VERSION "created by canmatrix"

NS_ :

BS_:

BU_: IPD

BO_ 299 LHZCU_LHBKBCANFD_20ms_FrP03: 8 Vector__XXX
 SG_ LHZCU_20ms_Group03_CRC : 7|8@0+ (1,0) [0|255] "null" IPD
 SG_ LHZCU_20ms_Group03_RC : 11|4@0+ (1,0) [0|15] "null" IPD
 SG_ LHZCU_20ms_Group03_Reserved1 : 15|4@0+ (1,0) [0|15] "null" IPD
 SG_ LHZCU_20ms_Group03_Reserved2 : 23|8@0+ (1,0) [0|255] "null" IPD
 SG_ LHZCU_20ms_Group03_Reserved3 : 31|8@0+ (1,0) [0|255] "null" IPD
 SG_ LHZCU_20ms_Group03_Reserved4 : 39|8@0+ (1,0) [0|255] "null" IPD
 SG_ LHZCU_20ms_Group03_Reserved6 : 41|4@0+ (1,0) [0|15] "null" IPD
 SG_ DippedBeamActStatus : 42|1@0+ (1,0) [0|1] "null" IPD
 SG_ LHZCU_20ms_Group03_Reserved5 : 47|5@0+ (1,0) [0|31] "null" IPD
 SG_ RevsLghtCtrl : 48|1@0+ (1,0) [0|1] "null" IPD
 SG_ PriySSBA : 49|1@0+ (1,0) [0|1] "null" IPD
 SG_ PriySSBAV : 50|1@0+ (1,0) [0|1] "null" IPD
 SG_ SecySSBA : 51|1@0+ (1,0) [0|1] "null" IPD
 SG_ SecySSBAV : 52|1@0+ (1,0) [0|1] "null" IPD
 SG_ SSBTrigd : 53|1@0+ (1,0) [0|1] "null" IPD
 SG_ RMainBeamLghtCtrl : 56|1@0+ (1,0) [0|1] "null" IPD
 SG_ LMainBeamLghtCtrl : 57|1@0+ (1,0) [0|1] "null" IPD
 SG_ RRDircnLghtCtrl : 58|1@0+ (1,0) [0|1] "null" IPD
 SG_ RLDircnLghtCtrl : 59|1@0+ (1,0) [0|1] "null" IPD
 SG_ FRDircnLghtCtrl : 60|1@0+ (1,0) [0|1] "null" IPD
 SG_ FLDircnLghtCtrl : 61|1@0+ (1,0) [0|1] "null" IPD
 SG_ BrkLghtCtrl : 62|1@0+ (1,0) [0|1] "null" IPD
 SG_ HzrdLghtSwReq : 63|1@0+ (1,0) [0|1] "null" IPD

BO_ 566 LHZCU_LHBKBCANFD_50ms_FrP04: 8 Vector__XXX
 SG_ FindCarFuncInfoDsp : 2|2@0+ (1,0) [0|3] "null" Vector__XXX
 SG_ FLDoorHndlPESwtActv : 7|2@0+ (1,0) [0|3] "null" IPD
 SG_ FRDoorHndlPESwtActv : 13|2@0+ (1,0) [0|3] "null" IPD
 SG_ BrkLghtSwStsV : 21|1@0+ (1,0) [0|1] "null" Vector__XXX
 SG_ BrkLghtSwSts : 22|1@0+ (1,0) [0|1] "null" Vector__XXX
 SG_ RrWiperReq : 23|1@0+ (1,0) [0|1] "null" Vector__XXX
 SG_ MainBeamLghtSwSts : 29|2@0+ (1,0) [0|3] "null" Vector__XXX
 SG_ DircnIndLghtSwSts : 31|2@0+ (1,0) [0|3] "null" IPD
 SG_ LdspcRlseSwtActv : 32|1@0+ (1,0) [0|1] "null" Vector__XXX
 SG_ FLDSP_RRWinSwtSts : 35|3@0+ (1,0) [0|7] "null" Vector__XXX
 SG_ FLDSP_RLWinSwtSts : 44|3@0+ (1,0) [0|7] "null" Vector__XXX
 SG_ FLDSP_FRWinSwtSts : 47|3@0+ (1,0) [0|7] "null" Vector__XXX
 SG_ BrkPdlTrigd : 49|1@0+ (1,0) [0|1] "null" Vector__XXX
 SG_ FLWinLclSwtSts : 52|3@0+ (1,0) [0|7] "null" Vector__XXX
 SG_ ExtrLckActnIndcn : 55|3@0+ (1,0) [0|7] "null" Vector__XXX
 SG_ AutoMainBeamLghtSts : 57|2@0+ (1,0) [0|3] "null" Vector__XXX
 SG_ DrvrDetSnsrFltSts : 60|3@0+ (1,0) [0|7] "null" Vector__XXX
 SG_ DircnIndLghtMdSts : 63|3@0+ (1,0) [0|7] "null" IPD

BO_ 652 LHZCU_LHBKBCANFD_50ms_FrP06: 8 Vector__XXX
 SG_ LHZCU_50ms_Group06_CRC : 7|8@0+ (1,0) [0|255] "null" IPD
 SG_ LHZCU_50ms_Group06_RC : 11|4@0+ (1,0) [0|15] "null" IPD
 SG_ DrvrDetSts : 13|2@0+ (1,0) [0|3] "null" IPD
 SG_ RLDoorOpenSts : 15|2@0+ (1,0) [0|3] "null" IPD
 SG_ LHZCU_50ms_Group06_Reserved1 : 16|1@0+ (1,0) [0|1] "null" IPD
 SG_ DrvrDoorOpenSts : 18|2@0+ (1,0) [0|3] "null" IPD
 SG_ BntOpenSts : 20|2@0+ (1,0) [0|3] "null" IPD
 SG_ VehLckSts : 23|3@0+ (1,0) [0|7] "null" IPD
 SG_ LHZCU_50ms_Group06_Reserved2 : 31|8@0+ (1,0) [0|255] "null" IPD
 SG_ LHZCU_50ms_Group06_Reserved3 : 39|8@0+ (1,0) [0|255] "null" IPD
 SG_ LHZCU_50ms_Group06_Reserved5 : 42|3@0+ (1,0) [0|7] "null" IPD
 SG_ RLSInitnFltPrst : 43|1@0+ (1,0) [0|1] "null" IPD
 SG_ LHZCU_50ms_Group06_Reserved4 : 47|4@0+ (1,0) [0|15] "null" IPD
 SG_ LHZCU_50ms_Group06_Reserved7 : 48|1@0+ (1,0) [0|1] "null" IPD
 SG_ DirnLghtSftyMonErr : 50|2@0+ (1,0) [0|3] "null" IPD
 SG_ LHZCU_50ms_Group06_Reserved6 : 55|5@0+ (1,0) [0|31] "null" IPD
 SG_ LHZCU_50ms_Group06_Reserved8 : 63|8@0+ (1,0) [0|255] "null" IPD

BO_ 547 LHZCU_LHBKBCANFD_50ms_FrP08: 8 Vector__XXX
 SG_ SideLghtSts : 0|1@0+ (1,0) [0|1] "null" IPD
 SG_ LHZCUeFs12Sts : 3|3@0+ (1,0) [0|7] "null" Vector__XXX
 SG_ LHZCUeFs12DiagSts : 7|4@0+ (1,0) [0|15] "null" Vector__XXX
 SG_ LHZCUeSw17Sts : 11|3@0+ (1,0) [0|7] "null" Vector__XXX
 SG_ LHZCUeSw17DiagSts : 15|4@0+ (1,0) [0|15] "null" Vector__XXX
 SG_ LHZCUeSw16Sts : 19|3@0+ (1,0) [0|7] "null" Vector__XXX
 SG_ LHZCUeSw16DiagSts : 23|4@0+ (1,0) [0|15] "null" Vector__XXX
 SG_ LHZCUeSw15Sts : 27|3@0+ (1,0) [0|7] "null" Vector__XXX
 SG_ LHZCUeSw15DiagSts : 31|4@0+ (1,0) [0|15] "null" Vector__XXX
 SG_ LHZCUeSw14Sts : 35|3@0+ (1,0) [0|7] "null" Vector__XXX
 SG_ LHZCUeSw14DiagSts : 39|4@0+ (1,0) [0|15] "null" Vector__XXX
 SG_ LHZCUeSw13Sts : 43|3@0+ (1,0) [0|7] "null" Vector__XXX
 SG_ LHZCUeSw13DiagSts : 47|4@0+ (1,0) [0|15] "null" Vector__XXX
 SG_ LHZCUeSw12Sts : 51|3@0+ (1,0) [0|7] "null" Vector__XXX
 SG_ LHZCUeSw12DiagSts : 55|4@0+ (1,0) [0|15] "null" Vector__XXX
 SG_ LHZCUeFs13Sts : 59|3@0+ (1,0) [0|7] "null" Vector__XXX
 SG_ LHZCUeFs13DiagSts : 63|4@0+ (1,0) [0|15] "null" Vector__XXX

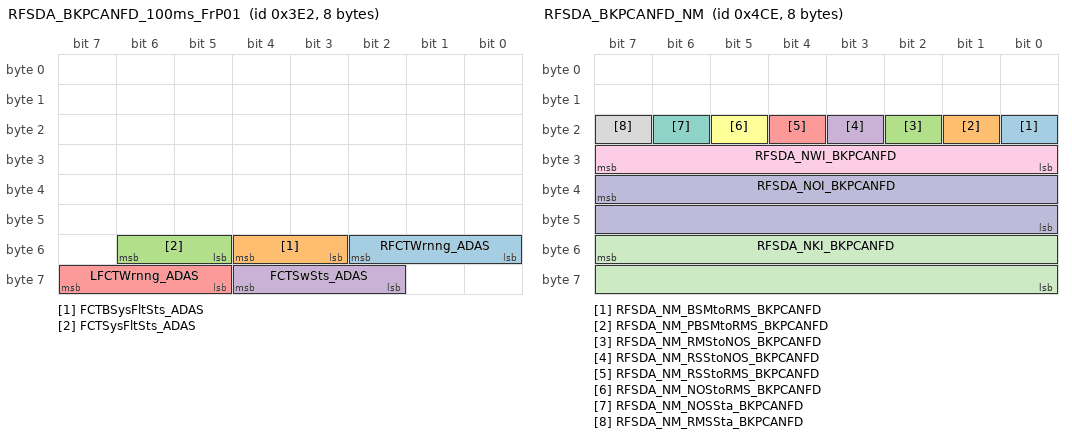
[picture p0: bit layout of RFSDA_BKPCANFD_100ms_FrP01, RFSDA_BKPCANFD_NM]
BO_ 994 RFSDA_BKPCANFD_100ms_FrP01: 8 Vector__XXX
 SG_ RFCTWrnng_ADAS : 50|3@0+ (1,0) [0|7] "null" IPD
 SG_ FCTBSysFltSts_ADAS : 52|2@0+ (1,0) [0|3] "null" IPD
 SG_ FCTSysFltSts_ADAS : 54|2@0+ (1,0) [0|3] "null" IPD
 SG_ FCTSwSts_ADAS : 60|3@0+ (1,0) [0|7] "null" IPD
 SG_ LFCTWrnng_ADAS : 63|3@0+ (1,0) [0|7] "null" IPD

BO_ 484 RFSDA_BKPCANFD_20ms_FrP02: 16 Vector__XXX
 SG_ RFSDA_20ms_Group02_CRC : 7|8@0+ (1,0) [0|255] "null" IPD
 SG_ RFSDA_20ms_Group02_RC : 11|4@0+ (1,0) [0|15] "null" IPD
 SG_ RFSDA_20ms_Group02_Reserved1 : 13|2@0+ (1,0) [0|3] "null" IPD
 SG_ AEBDclReqSts_ADAS : 15|2@0+ (1,0) [0|3] "null" IPD
 SG_ AEBDclReqToqVal_ADAS : 23|16@0+ (1,0) [0|65535] "Nm" IPD
 SG_ AEBDclReqVal_ADAS : 39|8@0+ (0.1,-12.7) [-12.7|12.8] "m/s2" IPD
 SG_ RFSDA_20ms_Group02_Reserved2 : 47|8@0+ (1,0) [0|255] "null" IPD
 SG_ RFSDA_20ms_Group02_Reserved3 : 55|8@0+ (1,0) [0|255] "null" IPD
 SG_ RFSDA_20ms_Group02_Reserved4 : 63|8@0+ (1,0) [0|255] "null" IPD
 SG_ RFSDA_20ms_Group02_Reserved5 : 71|8@0+ (1,0) [0|255] "null" IPD
 SG_ RFSDA_20ms_Group02_Reserved6 : 79|8@0+ (1,0) [0|255] "null" IPD
 SG_ RFSDA_20ms_Group02_Reserved7 : 87|8@0+ (1,0) [0|255] "null" IPD
 SG_ RFSDA_20ms_Group02_Reserved8 : 95|8@0+ (1,0) [0|255] "null" IPD
 SG_ RFSDA_20ms_Group02_Reserved9 : 103|8@0+ (1,0) [0|255] "null" IPD
 SG_ RFSDA_20ms_Group02_Reserved10 : 111|8@0+ (1,0) [0|255] "null" IPD
 SG_ RFSDA_20ms_Group02_Reserved11 : 119|8@0+ (1,0) [0|255] "null" IPD
 SG_ RFSDA_20ms_Group02_Reserved12 : 127|8@0+ (1,0) [0|255] "null" IPD

BO_ 1230 RFSDA_BKPCANFD_NM: 8 Vector__XXX
 SG_ RFSDA_NM_BSMtoRMS_BKPCANFD : 16|1@0+ (1,0) [0|1] "null" Vector__XXX
 SG_ RFSDA_NM_PBSMtoRMS_BKPCANFD : 17|1@0+ (1,0) [0|1] "null" Vector__XXX
 SG_ RFSDA_NM_RMStoNOS_BKPCANFD : 18|1@0+ (1,0) [0|1] "null" Vector__XXX
 SG_ RFSDA_NM_RSStoNOS_BKPCANFD : 19|1@0+ (1,0) [0|1] "null" Vector__XXX
 SG_ RFSDA_NM_RSStoRMS_BKPCANFD : 20|1@0+ (1,0) [0|1] "null" Vector__XXX
 SG_ RFSDA_NM_NOStoRMS_BKPCANFD : 21|1@0+ (1,0) [0|1] "null" Vector__XXX
 SG_ RFSDA_NM_NOSSta_BKPCANFD : 22|1@0+ (1,0) [0|1] "null" Vector__XXX
 SG_ RFSDA_NM_RMSSta_BKPCANFD : 23|1@0+ (1,0) [0|1] "null" Vector__XXX
 SG_ RFSDA_NWI_BKPCANFD : 31|8@0+ (1,0) [0|255] "null" Vector__XXX
 SG_ RFSDA_NOI_BKPCANFD : 39|16@0+ (1,0) [0|65535] "null" Vector__XXX
 SG_ RFSDA_NKI_BKPCANFD : 55|16@0+ (1,0) [0|65535] "null" Vector__XXX

BO_ 725 RHRDA_BKPCANFD_50ms_FrP04: 8 Vector__XXX
 SG_ RHRDA_50ms_Group04_CRC : 7|8@0+ (1,0) [0|255] "null" IPD
 SG_ RHRDA_50ms_Group04_RC : 11|4@0+ (1,0) [0|15] "null" IPD
 SG_ RDOWWrnng : 13|2@0+ (1,0) [0|3] "null" IPD
 SG_ LDOWWrnng : 15|2@0+ (1,0) [0|3] "null" IPD
 SG_ RHRDA_50ms_Group04_Reserved1 : 18|3@0+ (1,0) [0|7] "null" IPD
 SG_ RDASysSta : 23|5@0+ (1,0) [0|31] "null" IPD
 SG_ RBSDAndLCAWrnng : 25|2@0+ (1,0) [0|3] "null" IPD
 SG_ LBSDAndLCAWrnng : 27|2@0+ (1,0) [0|3] "null" IPD
 SG_ DOWSelSts : 29|2@0+ (1,0) [0|3] "null" IPD
 SG_ RDASwSts : 31|2@0+ (1,0) [0|3] "null" IPD
 SG_ LCASelSts : 33|2@0+ (1,0) [0|3] "null" IPD
 SG_ RRCTAWrnng : 35|2@0+ (1,0) [0|3] "null" IPD
 SG_ RCTSysSelSts : 37|2@0+ (1,0) [0|3] "null" IPD
 SG_ LRCTAWrnng : 39|2@0+ (1,0) [0|3] "null" IPD
 SG_ RHRDA_50ms_Group04_Reserved2 : 40|1@0+ (1,0) [0|1] "null" IPD
 SG_ RRRdrEmgcLineChngWrnng : 42|2@0+ (1,0) [0|3] "null" IPD
 SG_ RrCrnRdrCalSts : 45|3@0+ (1,0) [0|7] "null" IPD
 SG_ BSDSelSts : 47|2@0+ (1,0) [0|3] "null" IPD
 SG_ RHRDA_50ms_Group04_Reserved3 : 53|6@0+ (1,0) [0|63] "null" IPD
 SG_ RLRdrEmgcLineChngWrnng : 55|2@0+ (1,0) [0|3] "null" IPD
 SG_ RHRDA_50ms_Group04_Reserved4 : 63|8@0+ (1,0) [0|255] "null" IPD

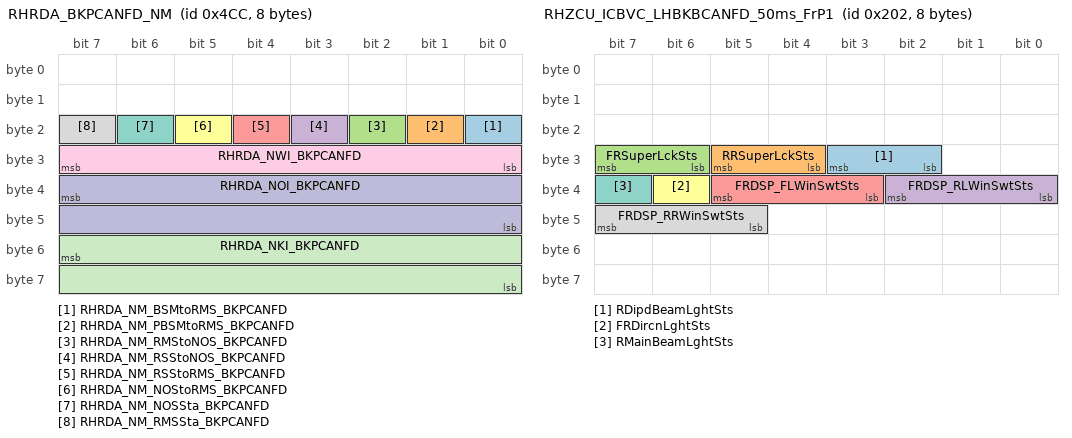
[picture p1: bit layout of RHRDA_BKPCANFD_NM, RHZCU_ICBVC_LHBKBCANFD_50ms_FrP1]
BO_ 1228 RHRDA_BKPCANFD_NM: 8 Vector__XXX
 SG_ RHRDA_NM_BSMtoRMS_BKPCANFD : 16|1@0+ (1,0) [0|1] "null" Vector__XXX
 SG_ RHRDA_NM_PBSMtoRMS_BKPCANFD : 17|1@0+ (1,0) [0|1] "null" Vector__XXX
 SG_ RHRDA_NM_RMStoNOS_BKPCANFD : 18|1@0+ (1,0) [0|1] "null" Vector__XXX
 SG_ RHRDA_NM_RSStoNOS_BKPCANFD : 19|1@0+ (1,0) [0|1] "null" Vector__XXX
 SG_ RHRDA_NM_RSStoRMS_BKPCANFD : 20|1@0+ (1,0) [0|1] "null" Vector__XXX
 SG_ RHRDA_NM_NOStoRMS_BKPCANFD : 21|1@0+ (1,0) [0|1] "null" Vector__XXX
 SG_ RHRDA_NM_NOSSta_BKPCANFD : 22|1@0+ (1,0) [0|1] "null" Vector__XXX
 SG_ RHRDA_NM_RMSSta_BKPCANFD : 23|1@0+ (1,0) [0|1] "null" Vector__XXX
 SG_ RHRDA_NWI_BKPCANFD : 31|8@0+ (1,0) [0|255] "null" Vector__XXX
 SG_ RHRDA_NOI_BKPCANFD : 39|16@0+ (1,0) [0|65535] "null" Vector__XXX
 SG_ RHRDA_NKI_BKPCANFD : 55|16@0+ (1,0) [0|65535] "null" Vector__XXX

BO_ 936 RHZCU_BDCAN_100ms_FrP06: 8 Vector__XXX
 SG_ FrtCamrHeatSts : 11|2@0+ (1,0) [0|3] "null" IPD
 SG_ FrSsdLrngFailRrsn : 22|3@0+ (1,0) [0|7] "null" Vector__XXX

BO_ 544 RHZCU_BKBCANFD_50ms_FrP27: 8 Vector__XXX
 SG_ RHZCU_50ms_Group27_CRC : 7|8@0+ (1,0) [0|255] "null" IPD
 SG_ RHZCU_50ms_Group27_RC : 11|4@0+ (1,0) [0|15] "null" IPD
 SG_ RHZCU_50ms_Group27_Reserved1 : 15|4@0+ (1,0) [0|15] "null" IPD
 SG_ RHZCU_50ms_Group27_Reserved2 : 16|1@0+ (1,0) [0|1] "null" IPD
 SG_ RHZCUeSw37Sts : 19|3@0+ (1,0) [0|7] "null" IPD
 SG_ RHZCUeSw37DiagSts : 23|4@0+ (1,0) [0|15] "null" IPD
 SG_ RHZCU_50ms_Group27_Reserved3 : 24|1@0+ (1,0) [0|1] "null" IPD
 SG_ RHZCUeSw3Sts : 27|3@0+ (1,0) [0|7] "null" IPD
 SG_ RHZCUeSw3DiagSts : 31|4@0+ (1,0) [0|15] "null" IPD
 SG_ RHZCU_50ms_Group27_Reserved4 : 32|1@0+ (1,0) [0|1] "null" IPD
 SG_ RHZCUeSw9Sts : 35|3@0+ (1,0) [0|7] "null" IPD
 SG_ RHZCUeSw9DiagSts : 39|4@0+ (1,0) [0|15] "null" IPD
 SG_ RHZCU_50ms_Group27_Reserved5 : 40|1@0+ (1,0) [0|1] "null" IPD
 SG_ RHZCUeSw33Sts : 43|3@0+ (1,0) [0|7] "null" IPD
 SG_ RHZCUeSw33DiagSts : 47|4@0+ (1,0) [0|15] "null" IPD
 SG_ RHZCU_50ms_Group27_Reserved6 : 48|1@0+ (1,0) [0|1] "null" IPD
 SG_ RHZCUeSw42Sts : 51|3@0+ (1,0) [0|7] "null" IPD
 SG_ RHZCUeSw42DiagSts : 55|4@0+ (1,0) [0|15] "null" IPD
 SG_ RHZCU_50ms_Group27_Reserved7 : 56|1@0+ (1,0) [0|1] "null" IPD
 SG_ RHZCUeSw43Sts : 59|3@0+ (1,0) [0|7] "null" IPD
 SG_ RHZCUeSw43DiagSts : 63|4@0+ (1,0) [0|15] "null" IPD

BO_ 514 RHZCU_ICBVC_LHBKBCANFD_50ms_FrP1: 8 Vector__XXX
 SG_ RDipdBeamLghtSts : 27|2@0+ (1,0) [0|3] "null" Vector__XXX
 SG_ RRSuperLckSts : 29|2@0+ (1,0) [0|3] "null" Vector__XXX
 SG_ FRSuperLckSts : 31|2@0+ (1,0) [0|3] "null" Vector__XXX
 SG_ FRDSP_RLWinSwtSts : 34|3@0+ (1,0) [0|7] "null" Vector__XXX
 SG_ FRDSP_FLWinSwtSts : 37|3@0+ (1,0) [0|7] "null" Vector__XXX
 SG_ FRDircnLghtSts : 38|1@0+ (1,0) [0|1] "null" IPD
 SG_ RMainBeamLghtSts : 39|1@0+ (1,0) [0|1] "null" Vector__XXX
 SG_ FRDSP_RRWinSwtSts : 47|3@0+ (1,0) [0|7] "null" Vector__XXX

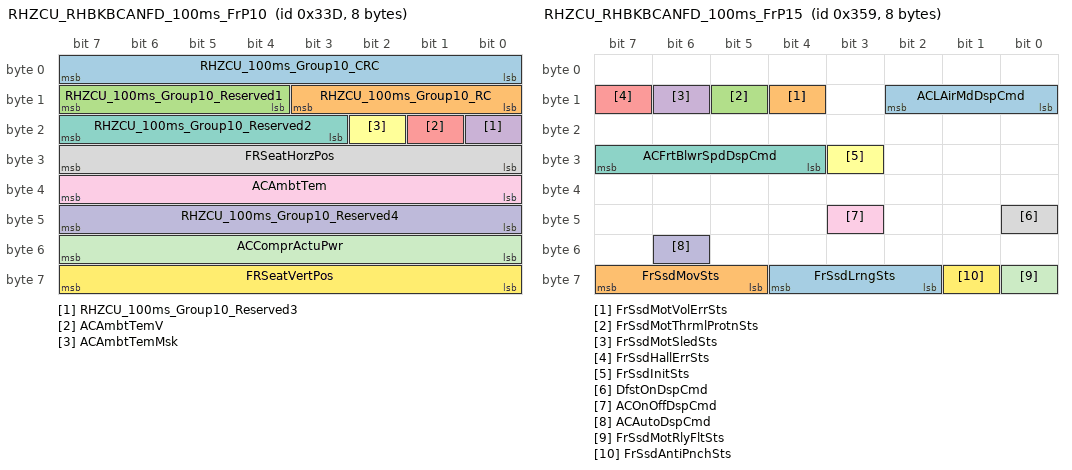
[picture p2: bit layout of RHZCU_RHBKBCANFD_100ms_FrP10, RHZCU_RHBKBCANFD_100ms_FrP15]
BO_ 829 RHZCU_RHBKBCANFD_100ms_FrP10: 8 Vector__XXX
 SG_ RHZCU_100ms_Group10_CRC : 7|8@0+ (1,0) [0|255] "null" IPD
 SG_ RHZCU_100ms_Group10_RC : 11|4@0+ (1,0) [0|15] "null" IPD
 SG_ RHZCU_100ms_Group10_Reserved1 : 15|4@0+ (1,0) [0|15] "null" IPD
 SG_ RHZCU_100ms_Group10_Reserved3 : 16|1@0+ (1,0) [0|1] "null" IPD
 SG_ ACAmbtTemV : 17|1@0+ (1,0) [0|1] "null" IPD
 SG_ ACAmbtTemMsk : 18|1@0+ (1,0) [0|1] "null" IPD
 SG_ RHZCU_100ms_Group10_Reserved2 : 23|5@0+ (1,0) [0|31] "null" IPD
 SG_ FRSeatHorzPos : 31|8@0+ (1,0) [0|255] "%" IPD
 SG_ ACAmbtTem : 39|8@0+ (0.5,-40) [-40|87.5] "degreeCelsius" IPD
 SG_ RHZCU_100ms_Group10_Reserved4 : 47|8@0+ (1,0) [0|255] "null" IPD
 SG_ ACComprActuPwr : 55|8@0+ (0.04,0) [0.00|10.20] "null" IPD
 SG_ FRSeatVertPos : 63|8@0+ (1,0) [0|255] "%" IPD

BO_ 857 RHZCU_RHBKBCANFD_100ms_FrP15: 8 Vector__XXX
 SG_ ACLAirMdDspCmd : 10|3@0+ (1,0) [0|7] "null" Vector__XXX
 SG_ FrSsdMotVolErrSts : 12|1@0+ (1,0) [0|1] "null" Vector__XXX
 SG_ FrSsdMotThrmlProtnSts : 13|1@0+ (1,0) [0|1] "null" Vector__XXX
 SG_ FrSsdMotSledSts : 14|1@0+ (1,0) [0|1] "null" Vector__XXX
 SG_ FrSsdHallErrSts : 15|1@0+ (1,0) [0|1] "null" Vector__XXX
 SG_ FrSsdInitSts : 27|1@0+ (1,0) [0|1] "null" Vector__XXX
 SG_ ACFrtBlwrSpdDspCmd : 31|4@0+ (1,0) [0|15] "null" Vector__XXX
 SG_ DfstOnDspCmd : 40|1@0+ (1,0) [0|1] "null" IPD
 SG_ ACOnOffDspCmd : 43|1@0+ (1,0) [0|1] "null" Vector__XXX
 SG_ ACAutoDspCmd : 54|1@0+ (1,0) [0|1] "null" Vector__XXX
 SG_ FrSsdMotRlyFltSts : 56|1@0+ (1,0) [0|1] "null" Vector__XXX
 SG_ FrSsdAntiPnchSts : 57|1@0+ (1,0) [0|1] "null" Vector__XXX
 SG_ FrSsdLrngSts : 60|3@0+ (1,0) [0|7] "null" Vector__XXX
 SG_ FrSsdMovSts : 63|3@0+ (1,0) [0|7] "null" Vector__XXX

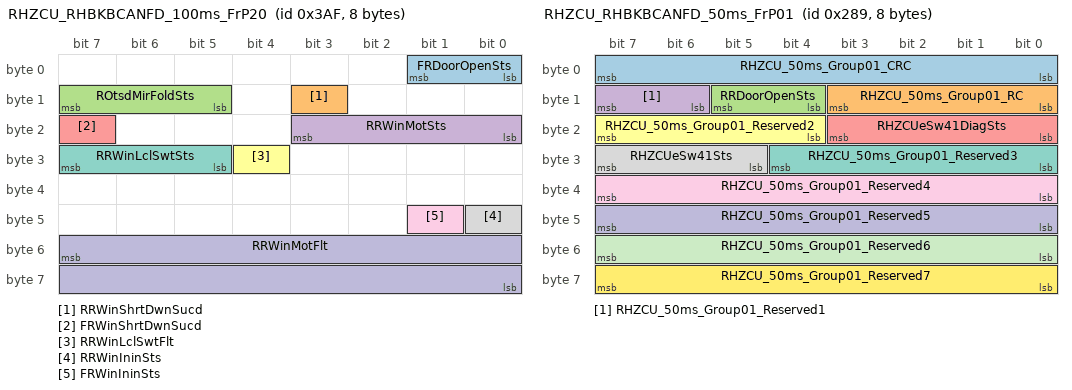
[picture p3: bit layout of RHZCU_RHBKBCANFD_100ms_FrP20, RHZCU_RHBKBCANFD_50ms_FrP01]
BO_ 943 RHZCU_RHBKBCANFD_100ms_FrP20: 8 Vector__XXX
 SG_ FRDoorOpenSts : 1|2@0+ (1,0) [0|3] "null" IPD
 SG_ RRWinShrtDwnSucd : 11|1@0+ (1,0) [0|1] "null" Vector__XXX
 SG_ ROtsdMirFoldSts : 15|3@0+ (1,0) [0|7] "null" Vector__XXX
 SG_ RRWinMotSts : 19|4@0+ (1,0) [0|15] "null" Vector__XXX
 SG_ FRWinShrtDwnSucd : 23|1@0+ (1,0) [0|1] "null" Vector__XXX
 SG_ RRWinLclSwtFlt : 28|1@0+ (1,0) [0|1] "null" Vector__XXX
 SG_ RRWinLclSwtSts : 31|3@0+ (1,0) [0|7] "null" Vector__XXX
 SG_ RRWinIninSts : 40|1@0+ (1,0) [0|1] "null" Vector__XXX
 SG_ FRWinIninSts : 41|1@0+ (1,0) [0|1] "null" Vector__XXX
 SG_ RRWinMotFlt : 55|16@0+ (1,0) [0|65535] "null" Vector__XXX

BO_ 649 RHZCU_RHBKBCANFD_50ms_FrP01: 8 Vector__XXX
 SG_ RHZCU_50ms_Group01_CRC : 7|8@0+ (1,0) [0|255] "null" IPD
 SG_ RHZCU_50ms_Group01_RC : 11|4@0+ (1,0) [0|15] "null" IPD
 SG_ RRDoorOpenSts : 13|2@0+ (1,0) [0|3] "null" IPD
 SG_ RHZCU_50ms_Group01_Reserved1 : 15|2@0+ (1,0) [0|3] "null" IPD
 SG_ RHZCUeSw41DiagSts : 19|4@0+ (1,0) [0|15] "null" IPD
 SG_ RHZCU_50ms_Group01_Reserved2 : 23|4@0+ (1,0) [0|15] "null" IPD
 SG_ RHZCU_50ms_Group01_Reserved3 : 28|5@0+ (1,0) [0|31] "null" IPD
 SG_ RHZCUeSw41Sts : 31|3@0+ (1,0) [0|7] "null" IPD
 SG_ RHZCU_50ms_Group01_Reserved4 : 39|8@0+ (1,0) [0|255] "null" IPD
 SG_ RHZCU_50ms_Group01_Reserved5 : 47|8@0+ (1,0) [0|255] "null" IPD
 SG_ RHZCU_50ms_Group01_Reserved6 : 55|8@0+ (1,0) [0|255] "null" IPD
 SG_ RHZCU_50ms_Group01_Reserved7 : 63|8@0+ (1,0) [0|255] "null" IPD

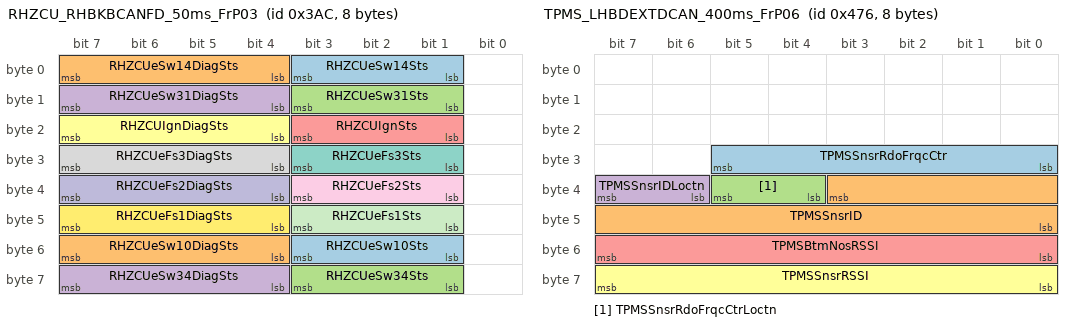
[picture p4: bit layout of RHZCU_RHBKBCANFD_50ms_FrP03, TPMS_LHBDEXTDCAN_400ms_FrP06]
BO_ 940 RHZCU_RHBKBCANFD_50ms_FrP03: 8 Vector__XXX
 SG_ RHZCUeSw14Sts : 3|3@0+ (1,0) [0|7] "null" Vector__XXX
 SG_ RHZCUeSw14DiagSts : 7|4@0+ (1,0) [0|15] "null" Vector__XXX
 SG_ RHZCUeSw31Sts : 11|3@0+ (1,0) [0|7] "null" Vector__XXX
 SG_ RHZCUeSw31DiagSts : 15|4@0+ (1,0) [0|15] "null" Vector__XXX
 SG_ RHZCUIgnSts : 19|3@0+ (1,0) [0|7] "null" Vector__XXX
 SG_ RHZCUIgnDiagSts : 23|4@0+ (1,0) [0|15] "null" Vector__XXX
 SG_ RHZCUeFs3Sts : 27|3@0+ (1,0) [0|7] "null" Vector__XXX
 SG_ RHZCUeFs3DiagSts : 31|4@0+ (1,0) [0|15] "null" Vector__XXX
 SG_ RHZCUeFs2Sts : 35|3@0+ (1,0) [0|7] "null" Vector__XXX
 SG_ RHZCUeFs2DiagSts : 39|4@0+ (1,0) [0|15] "null" Vector__XXX
 SG_ RHZCUeFs1Sts : 43|3@0+ (1,0) [0|7] "null" IPD
 SG_ RHZCUeFs1DiagSts : 47|4@0+ (1,0) [0|15] "null" Vector__XXX
 SG_ RHZCUeSw10Sts : 51|3@0+ (1,0) [0|7] "null" Vector__XXX
 SG_ RHZCUeSw10DiagSts : 55|4@0+ (1,0) [0|15] "null" Vector__XXX
 SG_ RHZCUeSw34Sts : 59|3@0+ (1,0) [0|7] "null" Vector__XXX
 SG_ RHZCUeSw34DiagSts : 63|4@0+ (1,0) [0|15] "null" Vector__XXX

BO_ 564 RZCU_LHBKBCANFD_50ms_FrP37: 8 Vector__XXX
 SG_ RZCU_50ms_Group37_CRC : 7|8@0+ (1,0) [0|255] "null" IPD
 SG_ RZCU_50ms_Group37_RC : 11|4@0+ (1,0) [0|15] "null" IPD
 SG_ RZCU_50ms_Group37_Reserved15 : 15|4@0+ (1,0) [0|15] "null" IPD
 SG_ RZCU_50ms_Group37_Reserved23 : 23|8@0+ (1,0) [0|255] "null" IPD
 SG_ ChrgrFlapLtchCtrl : 25|2@0+ (1,0) [0|3] "null" IPD
 SG_ RLDircnLghtSts : 26|1@0+ (1,0) [0|1] "null" IPD
 SG_ RZCU_50ms_Group37_Reserved31 : 31|5@0+ (1,0) [0|31] "null" IPD
 SG_ RZCU_50ms_Group37_Reserved34 : 34|5@0+ (1,0) [0|31] "null" IPD
 SG_ RRDircnLghtSts : 35|1@0+ (1,0) [0|1] "null" IPD
 SG_ RZCU_50ms_Group37_Reserved36 : 36|1@0+ (1,0) [0|1] "null" IPD
 SG_ RRDircnLghtFltsts : 37|1@0+ (1,0) [0|1] "null" IPD
 SG_ RZCU_50ms_Group37_Reserved38 : 38|1@0+ (1,0) [0|1] "null" IPD
 SG_ RLDircnLghtFltsts : 39|1@0+ (1,0) [0|1] "null" IPD
 SG_ RRDircnLghtFltsts_HW : 40|1@0+ (1,0) [0|1] "null" IPD
 SG_ RLDircnLghtFltsts_HW : 41|1@0+ (1,0) [0|1] "null" IPD
 SG_ RearFogLghtFltsts : 42|1@0+ (1,0) [0|1] "null" IPD
 SG_ RearFogLghtSts : 43|1@0+ (1,0) [0|1] "null" IPD
 SG_ RevsLghtFltSts : 44|1@0+ (1,0) [0|1] "null" IPD
 SG_ BrkLghtFltSts_HW : 45|1@0+ (1,0) [0|1] "null" IPD
 SG_ PwrLftgtClsSwtActv : 49|2@0+ (1,0) [0|3] "null" IPD
 SG_ BrkLghtSts_HW : 50|1@0+ (1,0) [0|1] "null" IPD
 SG_ RLDircnLghtSts_HW : 51|1@0+ (1,0) [0|1] "null" IPD
 SG_ RRDircnLghtSts_HW : 52|1@0+ (1,0) [0|1] "null" IPD
 SG_ LdspcOpenSts : 53|1@0+ (1,0) [0|1] "null" IPD
 SG_ RevsLghtSts : 54|1@0+ (1,0) [0|1] "null" IPD
 SG_ LdspcOpenStsV : 55|1@0+ (1,0) [0|1] "null" IPD
 SG_ RZCU_50ms_Group37_Reserved63 : 63|8@0+ (1,0) [0|255] "null" IPD

BO_ 1142 TPMS_LHBDEXTDCAN_400ms_FrP06: 8 Vector__XXX
 SG_ TPMSSnsrRdoFrqcCtr : 29|6@0+ (1,0) [0|63] "null" IPD
 SG_ TPMSSnsrID : 35|12@0+ (1,0) [0|4095] "null" IPD
 SG_ TPMSSnsrRdoFrqcCtrLoctn : 37|2@0+ (1,0) [0|3] "null" IPD
 SG_ TPMSSnsrIDLoctn : 39|2@0+ (1,0) [0|3] "null" IPD
 SG_ TPMSBtmNosRSSI : 55|8@0+ (1,0) [0|255] "null" IPD
 SG_ TPMSSnsrRSSI : 63|8@0+ (1,0) [0|255] "null" IPD

BO_ 210 Tester_ECM_SFCANFD_10ms_FrP20: 8 Vector__XXX
 SG_ En12VoltStrMotCmddOn : 56|1@0+ (1,0) [0|1] "null" IPD

BO_ 805 ZXD_BKBCANFD_100ms_FrP257: 24 Vector__XXX
 SG_ NOAQukChgSwReq : 12|1@0+ (1,0) [0|1] "null" IPD
 SG_ PDCPwrSts : 13|1@0+ (1,0) [0|1] "null" Vector__XXX
 SG_ MMCUPwrSts : 14|1@0+ (1,0) [0|1] "null" Vector__XXX
 SG_ FICMACRTemV : 15|1@0+ (1,0) [0|1] "null" Vector__XXX
 SG_ AIParkngReq_ZXD : 23|8@0+ (1,0) [0|255] "null" IPD
 SG_ FICMACRAirMdSwReq : 25|2@0+ (1,0) [0|3] "null" Vector__XXX
 SG_ FICMACLAirMdSwReq : 27|2@0+ (1,0) [0|3] "null" Vector__XXX
 SG_ FICMACIonizerReqSwReq : 29|2@0+ (1,0) [0|3] "null" Vector__XXX
 SG_ FICMACFreshSwReq : 31|2@0+ (1,0) [0|3] "null" Vector__XXX
 SG_ FICMClmOnOffSwReq : 33|2@0+ (1,0) [0|3] "null" Vector__XXX
 SG_ FICMACSyncSwReq : 35|2@0+ (1,0) [0|3] "null" Vector__XXX
 SG_ FICMACRTemIncSwReq : 37|2@0+ (1,0) [0|3] "null" Vector__XXX
 SG_ FICMACRTemDecSwReq : 39|2@0+ (1,0) [0|3] "null" Vector__XXX
 SG_ FICMAirClnrBlwrLvlReq : 42|3@0+ (1,0) [0|7] "null" Vector__XXX
 SG_ FICMACRTemReq : 47|5@0+ (0.5,15.5) [15.5|31] "null" Vector__XXX
 SG_ AutoLaneChngVcCmd : 51|4@0+ (1,0) [0|15] "null" IPD
 SG_ APAParkInOffsetTypeReq : 55|4@0+ (1,0) [0|15] "null" IPD
 SG_ FICMIFPACOnOffSwReq : 57|2@0+ (1,0) [0|3] "null" Vector__XXX
 SG_ NOAReportSetSwReq : 60|3@0+ (1,0) [0|7] "null" IPD
 SG_ NarRoVslAssSwReq : 63|3@0+ (1,0) [0|7] "null" IPD
 SG_ ParkngSpdSwResp : 65|2@0+ (1,0) [0|3] "null" IPD
 SG_ NrwroadBwdAssSwReq : 68|3@0+ (1,0) [0|7] "null" IPD
 SG_ AutoLaneChngSwReq : 71|3@0+ (1,0) [0|7] "null" IPD
 SG_ ESSAdoWrnngReq : 73|2@0+ (1,0) [0|3] "null" IPD
 SG_ AutoLaneChngSetReq : 75|2@0+ (1,0) [0|3] "null" IPD
 SG_ APASWReq : 77|2@0+ (1,0) [0|3] "null" IPD
 SG_ APAOneKeyParkSwReq : 79|2@0+ (1,0) [0|3] "null" IPD
 SG_ NarRoVslAssQuit : 81|2@0+ (1,0) [0|3] "null" IPD
 SG_ LCRSwReq : 83|2@0+ (1,0) [0|3] "null" IPD
 SG_ FrtCarGoNotfrSwReq : 85|2@0+ (1,0) [0|3] "null" IPD
 SG_ ESSswReq : 87|2@0+ (1,0) [0|3] "null" IPD
 SG_ NOPSwReq : 89|2@0+ (1,0) [0|3] "null" IPD
 SG_ NOPCitySwReq : 91|2@0+ (1,0) [0|3] "null" IPD
 SG_ NOALaneSetSwReq : 93|2@0+ (1,0) [0|3] "null" IPD
 SG_ NOAETCSetSwReq : 95|2@0+ (1,0) [0|3] "null" IPD
 SG_ WlcmLghtReq : 96|1@0+ (1,0) [0|1] "null" Vector__XXX
 SG_ D2DSwReq : 98|2@0+ (1,0) [0|3] "null" IPD
 SG_ ParkngDirSw : 101|2@0+ (1,0) [0|3] "null" IPD
 SG_ NrwroadBwdAssConfrmSwReq : 103|2@0+ (1,0) [0|3] "null" IPD
 SG_ DistToDsttnNavForSus : 111|8@0+ (2,0) [0|510] "m" Vector__XXX
 SG_ FrwlLghtReq : 112|1@0+ (1,0) [0|1] "null" Vector__XXX
 SG_ FollowMeHomeReq : 113|1@0+ (1,0) [0|1] "null" Vector__XXX
 SG_ FICMChrgSttnMchngSta : 115|2@0+ (1,0) [0|3] "null" Vector__XXX
 SG_ FVCMPowerFailSwReq : 117|2@0+ (1,0) [0|3] "null" Vector__XXX
 SG_ D2DPriETClanSwReq : 119|2@0+ (1,0) [0|3] "null" IPD
 SG_ SLIFWrnngMdReq : 126|2@0+ (1,0) [0|3] "null" IPD
 SG_ AIParkngEPAMdsw : 127|1@0+ (1,0) [0|1] "null" IPD
 SG_ PEBSwReq : 135|1@0+ (1,0) [0|1] "null" IPD

BO_ 711 ZXD_BKPCANFD_100ms_FrP76: 16 Vector__XXX
 SG_ SpedRegulaModSwReq : 55|3@0+ (1,0) [0|7] "null" IPD

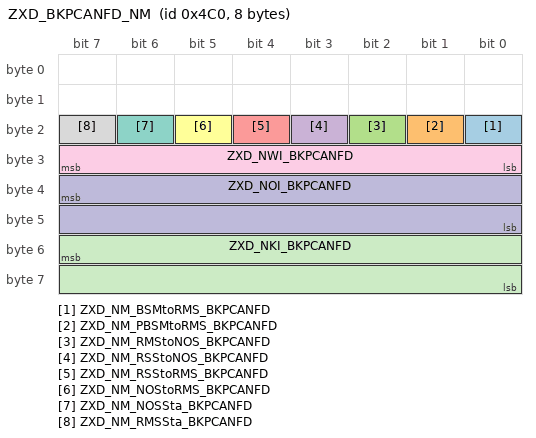
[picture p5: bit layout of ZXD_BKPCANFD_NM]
BO_ 1216 ZXD_BKPCANFD_NM: 8 Vector__XXX
 SG_ ZXD_NM_BSMtoRMS_BKPCANFD : 16|1@0+ (1,0) [0|1] "null" Vector__XXX
 SG_ ZXD_NM_PBSMtoRMS_BKPCANFD : 17|1@0+ (1,0) [0|1] "null" Vector__XXX
 SG_ ZXD_NM_RMStoNOS_BKPCANFD : 18|1@0+ (1,0) [0|1] "null" Vector__XXX
 SG_ ZXD_NM_RSStoNOS_BKPCANFD : 19|1@0+ (1,0) [0|1] "null" Vector__XXX
 SG_ ZXD_NM_RSStoRMS_BKPCANFD : 20|1@0+ (1,0) [0|1] "null" Vector__XXX
 SG_ ZXD_NM_NOStoRMS_BKPCANFD : 21|1@0+ (1,0) [0|1] "null" Vector__XXX
 SG_ ZXD_NM_NOSSta_BKPCANFD : 22|1@0+ (1,0) [0|1] "null" Vector__XXX
 SG_ ZXD_NM_RMSSta_BKPCANFD : 23|1@0+ (1,0) [0|1] "null" Vector__XXX
 SG_ ZXD_NWI_BKPCANFD : 31|8@0+ (1,0) [0|255] "null" Vector__XXX
 SG_ ZXD_NOI_BKPCANFD : 39|16@0+ (1,0) [0|65535] "null" Vector__XXX
 SG_ ZXD_NKI_BKPCANFD : 55|16@0+ (1,0) [0|65535] "null" Vector__XXX

BA_DEF_ BO_ "FrameTriggeringName" STRING;
BA_DEF_ BO_ "GenMsgCycleTime" INT 0 65535;
BA_DEF_ BO_ "GenMsgDelayTime" INT 0 65535;
BA_DEF_ BO_ "GenMsgSendType" ENUM  "cyclicX","spontanX","cyclicIfActiveX","spontanWithDelay","cyclicAndSpontanX","cyclicAndSpontanWithDelay","spontanWithRepitition","cyclicIfActiveAndSpontanWD","cyclicIfActiveFast","cyclicWithRepeatOnDemand","none";
BA_DEF_ BO_ "GenMsgStartValue" STRING;
BA_DEF_ BO_ "PduName" STRING;
BA_DEF_ BO_ "SystemMessageLongSymbol" STRING;
BA_DEF_ BO_ "VFrameFormat" ENUM  "StandardCAN","ExtendedCAN","reserved","reserved","reserved","reserved","reserved","reserved","reserved","reserved","reserved","reserved","reserved","reserved","StandardCAN_FD","ExtendedCAN_FD";
BA_DEF_ SG_ "CompuMethodName" STRING;
BA_DEF_ SG_ "GenSigStartValue" FLOAT 0 100000000000;
BA_DEF_ SG_ "ISignalName" STRING;
BA_DEF_ SG_ "LongName" STRING;
BA_DEF_ SG_ "SysSignalName" STRING;
BA_DEF_ SG_ "SystemSignalLongSymbol" STRING;
BA_ "FrameTriggeringName" BO_ 299 "LHZCU_LHBKBCANFD_20ms_FrP03";
BA_ "GenMsgCycleTime" BO_ 299 20;
BA_ "GenMsgSendType" BO_ 299 0;
BA_ "GenMsgStartValue" BO_ 299 "00f0fffffffbc000";
BA_ "PduName" BO_ 299 "LHZCU_20ms_PDU03";
BA_ "VFrameFormat" BO_ 299 14;
BA_ "FrameTriggeringName" BO_ 566 "LHZCU_LHBKBCANFD_50ms_FrP04";
BA_ "GenMsgCycleTime" BO_ 566 50;
BA_ "GenMsgSendType" BO_ 566 0;
BA_ "GenMsgStartValue" BO_ 566 "0000000000000000";
BA_ "PduName" BO_ 566 "LHZCU_50ms_PDU04";
BA_ "VFrameFormat" BO_ 566 14;
BA_ "FrameTriggeringName" BO_ 652 "LHZCU_LHBKBCANFD_50ms_FrP06";
BA_ "GenMsgCycleTime" BO_ 652 50;
BA_ "GenMsgSendType" BO_ 652 0;
BA_ "GenMsgStartValue" BO_ 652 "0000e1fffff7f9ff";
BA_ "PduName" BO_ 652 "LHZCU_50ms_PDU06";
BA_ "VFrameFormat" BO_ 652 14;
BA_ "FrameTriggeringName" BO_ 547 "LHZCU_LHBKBCANFD_50ms_FrP08";
BA_ "GenMsgCycleTime" BO_ 547 50;
BA_ "GenMsgSendType" BO_ 547 0;
BA_ "GenMsgStartValue" BO_ 547 "0000000000000000";
BA_ "PduName" BO_ 547 "LHZCU_50ms_PDU08";
BA_ "VFrameFormat" BO_ 547 14;
BA_ "FrameTriggeringName" BO_ 994 "RFSDA_BKPCANFD_100ms_FrP01";
BA_ "GenMsgCycleTime" BO_ 994 100;
BA_ "GenMsgSendType" BO_ 994 0;
BA_ "GenMsgStartValue" BO_ 994 "0000000000000004";
BA_ "PduName" BO_ 994 "RFSDA_100ms_PDU01";
BA_ "VFrameFormat" BO_ 994 14;
BA_ "FrameTriggeringName" BO_ 484 "RFSDA_BKPCANFD_20ms_FrP02";
BA_ "GenMsgCycleTime" BO_ 484 20;
BA_ "GenMsgSendType" BO_ 484 0;
BA_ "GenMsgStartValue" BO_ 484 "003000007fffffffffffffffffffffff";
BA_ "PduName" BO_ 484 "RFSDA_20ms_PDU02";
BA_ "VFrameFormat" BO_ 484 14;
BA_ "FrameTriggeringName" BO_ 1230 "RFSDA_BKPCANFD_NM";
BA_ "GenMsgSendType" BO_ 1230 1;
BA_ "GenMsgStartValue" BO_ 1230 "0000000000000000";
BA_ "PduName" BO_ 1230 "NmPDU_BKPCANFD_RFSDA";
BA_ "VFrameFormat" BO_ 1230 14;
BA_ "FrameTriggeringName" BO_ 725 "RHRDA_BKPCANFD_50ms_FrP04";
BA_ "GenMsgCycleTime" BO_ 725 50;
BA_ "GenMsgSendType" BO_ 725 0;
BA_ "GenMsgStartValue" BO_ 725 "00000f0000013fff";
BA_ "PduName" BO_ 725 "RHRDA_50ms_PDU04";
BA_ "VFrameFormat" BO_ 725 14;
BA_ "FrameTriggeringName" BO_ 1228 "RHRDA_BKPCANFD_NM";
BA_ "GenMsgSendType" BO_ 1228 1;
BA_ "GenMsgStartValue" BO_ 1228 "0000000000000000";
BA_ "PduName" BO_ 1228 "NmPDU_BKPCANFD_RHRDA";
BA_ "VFrameFormat" BO_ 1228 14;
BA_ "FrameTriggeringName" BO_ 936 "RHZCU_BDCAN_100ms_FrP06";
BA_ "GenMsgCycleTime" BO_ 936 100;
BA_ "GenMsgSendType" BO_ 936 0;
BA_ "GenMsgStartValue" BO_ 936 "0000000000000000";
BA_ "PduName" BO_ 936 "RHZCU_100ms_PDU06";
BA_ "VFrameFormat" BO_ 936 14;
BA_ "FrameTriggeringName" BO_ 544 "RHZCU_BKBCANFD_50ms_FrP27";
BA_ "GenMsgCycleTime" BO_ 544 50;
BA_ "GenMsgSendType" BO_ 544 0;
BA_ "GenMsgStartValue" BO_ 544 "00f0010101010101";
BA_ "PduName" BO_ 544 "RHZCU_50ms_PDU27";
BA_ "VFrameFormat" BO_ 544 14;
BA_ "FrameTriggeringName" BO_ 514 "RHZCU_ICBVC_LHBKBCANFD_50ms_FrP14";
BA_ "GenMsgCycleTime" BO_ 514 50;
BA_ "GenMsgSendType" BO_ 514 0;
BA_ "GenMsgStartValue" BO_ 514 "0000000000000000";
BA_ "PduName" BO_ 514 "RHZCU_ICBVC_50ms_PDU14";
BA_ "SystemMessageLongSymbol" BO_ 514 "RHZCU_ICBVC_LHBKBCANFD_50ms_FrP14";
BA_ "VFrameFormat" BO_ 514 14;
BA_ "FrameTriggeringName" BO_ 829 "RHZCU_RHBKBCANFD_100ms_FrP10";
BA_ "GenMsgCycleTime" BO_ 829 100;
BA_ "GenMsgSendType" BO_ 829 0;
BA_ "GenMsgStartValue" BO_ 829 "00f0fbff00ff00ff";
BA_ "PduName" BO_ 829 "RHZCU_100ms_PDU10";
BA_ "VFrameFormat" BO_ 829 14;
BA_ "FrameTriggeringName" BO_ 857 "RHZCU_RHBKBCANFD_100ms_FrP15";
BA_ "GenMsgCycleTime" BO_ 857 100;
BA_ "GenMsgSendType" BO_ 857 0;
BA_ "GenMsgStartValue" BO_ 857 "000700f000000000";
BA_ "PduName" BO_ 857 "RHZCU_100ms_PDU15";
BA_ "VFrameFormat" BO_ 857 14;
BA_ "FrameTriggeringName" BO_ 943 "RHZCU_RHBKBCANFD_100ms_FrP20";
BA_ "GenMsgCycleTime" BO_ 943 100;
BA_ "GenMsgSendType" BO_ 943 0;
BA_ "GenMsgStartValue" BO_ 943 "0000000000000000";
BA_ "PduName" BO_ 943 "RHZCU_100ms_PDU20";
BA_ "VFrameFormat" BO_ 943 14;
BA_ "FrameTriggeringName" BO_ 649 "RHZCU_RHBKBCANFD_50ms_FrP01";
BA_ "GenMsgCycleTime" BO_ 649 50;
BA_ "GenMsgSendType" BO_ 649 0;
BA_ "GenMsgStartValue" BO_ 649 "00c0f01fffffffff";
BA_ "PduName" BO_ 649 "RHZCU_50ms_PDU01";
BA_ "VFrameFormat" BO_ 649 14;
BA_ "FrameTriggeringName" BO_ 940 "RHZCU_RHBKBCANFD_50ms_FrP03";
BA_ "GenMsgCycleTime" BO_ 940 50;
BA_ "GenMsgSendType" BO_ 940 0;
BA_ "GenMsgStartValue" BO_ 940 "0000000000000000";
BA_ "PduName" BO_ 940 "RHZCU_50ms_PDU03";
BA_ "VFrameFormat" BO_ 940 14;
BA_ "FrameTriggeringName" BO_ 564 "RZCU_LHBKBCANFD_50ms_FrP37";
BA_ "GenMsgCycleTime" BO_ 564 50;
BA_ "GenMsgSendType" BO_ 564 0;
BA_ "GenMsgStartValue" BO_ 564 "00f0fff857c000ff";
BA_ "PduName" BO_ 564 "RZCU_50ms_PDU37";
BA_ "VFrameFormat" BO_ 564 14;
BA_ "FrameTriggeringName" BO_ 1142 "TPMS_LHBDEXTDCAN_400ms_FrP06";
BA_ "GenMsgCycleTime" BO_ 1142 400;
BA_ "GenMsgSendType" BO_ 1142 0;
BA_ "GenMsgStartValue" BO_ 1142 "0000000000000000";
BA_ "PduName" BO_ 1142 "TPMS_400ms_PDU06";
BA_ "VFrameFormat" BO_ 1142 14;
BA_ "FrameTriggeringName" BO_ 210 "Tester_ECM_SFCANFD_10ms_FrP20";
BA_ "GenMsgCycleTime" BO_ 210 10;
BA_ "GenMsgSendType" BO_ 210 0;
BA_ "GenMsgStartValue" BO_ 210 "0000000000000000";
BA_ "PduName" BO_ 210 "Teter_ECM_10ms_PDU20";
BA_ "VFrameFormat" BO_ 210 14;
BA_ "FrameTriggeringName" BO_ 805 "ZXD_BKBCANFD_100ms_FrP257";
BA_ "GenMsgCycleTime" BO_ 805 100;
BA_ "GenMsgSendType" BO_ 805 0;
BA_ "GenMsgStartValue" BO_ 805 "0080000000f800000000000000ff00000000000000000000";
BA_ "PduName" BO_ 805 "ICBVC_100ms_PDU257";
BA_ "VFrameFormat" BO_ 805 14;
BA_ "FrameTriggeringName" BO_ 711 "ZXD_BKPCANFD_100ms_FrP76";
BA_ "GenMsgCycleTime" BO_ 711 100;
BA_ "GenMsgSendType" BO_ 711 0;
BA_ "GenMsgStartValue" BO_ 711 "00000000000000000000000000000000";
BA_ "PduName" BO_ 711 "ZXD_100ms_PDU76";
BA_ "VFrameFormat" BO_ 711 14;
BA_ "FrameTriggeringName" BO_ 1216 "ZXD_BKPCANFD_NM";
BA_ "GenMsgSendType" BO_ 1216 1;
BA_ "GenMsgStartValue" BO_ 1216 "0000000000000000";
BA_ "PduName" BO_ 1216 "NmPDU_BKPCANFD_ZXD";
BA_ "VFrameFormat" BO_ 1216 14;
BA_ "CompuMethodName" SG_ 299 LHZCU_20ms_Group03_CRC "LHZCU_20ms_Group03_CRC";
BA_ "ISignalName" SG_ 299 LHZCU_20ms_Group03_CRC "ILHZCU_20ms_Group03_CRC";
BA_ "LongName" SG_ 299 LHZCU_20ms_Group03_CRC "LHZCU_20ms_Group03_CRC";
BA_ "SysSignalName" SG_ 299 LHZCU_20ms_Group03_CRC "LHZCU_20ms_Group03_CRC";
BA_ "CompuMethodName" SG_ 299 LHZCU_20ms_Group03_RC "LHZCU_20ms_Group03_RC";
BA_ "ISignalName" SG_ 299 LHZCU_20ms_Group03_RC "ILHZCU_20ms_Group03_RC";
BA_ "LongName" SG_ 299 LHZCU_20ms_Group03_RC "LHZCU_20ms_Group03_RC";
BA_ "SysSignalName" SG_ 299 LHZCU_20ms_Group03_RC "LHZCU_20ms_Group03_RC";
BA_ "CompuMethodName" SG_ 299 LHZCU_20ms_Group03_Reserved1 "LHZCU_20ms_Group03_Reserved1";
BA_ "GenSigStartValue" SG_ 299 LHZCU_20ms_Group03_Reserved1 15;
BA_ "ISignalName" SG_ 299 LHZCU_20ms_Group03_Reserved1 "ILHZCU_20ms_Group03_Reserved1";
BA_ "SysSignalName" SG_ 299 LHZCU_20ms_Group03_Reserved1 "LHZCU_20ms_Group03_Reserved1";
BA_ "CompuMethodName" SG_ 299 LHZCU_20ms_Group03_Reserved2 "LHZCU_20ms_Group03_Reserved2";
BA_ "GenSigStartValue" SG_ 299 LHZCU_20ms_Group03_Reserved2 255;
BA_ "ISignalName" SG_ 299 LHZCU_20ms_Group03_Reserved2 "ILHZCU_20ms_Group03_Reserved2";
BA_ "SysSignalName" SG_ 299 LHZCU_20ms_Group03_Reserved2 "LHZCU_20ms_Group03_Reserved2";
BA_ "CompuMethodName" SG_ 299 LHZCU_20ms_Group03_Reserved3 "LHZCU_20ms_Group03_Reserved3";
BA_ "GenSigStartValue" SG_ 299 LHZCU_20ms_Group03_Reserved3 255;
BA_ "ISignalName" SG_ 299 LHZCU_20ms_Group03_Reserved3 "ILHZCU_20ms_Group03_Reserved3";
BA_ "SysSignalName" SG_ 299 LHZCU_20ms_Group03_Reserved3 "LHZCU_20ms_Group03_Reserved3";
BA_ "CompuMethodName" SG_ 299 LHZCU_20ms_Group03_Reserved4 "LHZCU_20ms_Group03_Reserved4";
BA_ "GenSigStartValue" SG_ 299 LHZCU_20ms_Group03_Reserved4 255;
BA_ "ISignalName" SG_ 299 LHZCU_20ms_Group03_Reserved4 "ILHZCU_20ms_Group03_Reserved4";
BA_ "SysSignalName" SG_ 299 LHZCU_20ms_Group03_Reserved4 "LHZCU_20ms_Group03_Reserved4";
BA_ "CompuMethodName" SG_ 299 LHZCU_20ms_Group03_Reserved6 "LHZCU_20ms_Group03_Reserved6";
BA_ "GenSigStartValue" SG_ 299 LHZCU_20ms_Group03_Reserved6 15;
BA_ "ISignalName" SG_ 299 LHZCU_20ms_Group03_Reserved6 "ILHZCU_20ms_Group03_Reserved6";
BA_ "SysSignalName" SG_ 299 LHZCU_20ms_Group03_Reserved6 "LHZCU_20ms_Group03_Reserved6";
BA_ "CompuMethodName" SG_ 299 DippedBeamActStatus "DippedBeamActStatus";
BA_ "ISignalName" SG_ 299 DippedBeamActStatus "IDippedBeamActStatus";
BA_ "LongName" SG_ 299 DippedBeamActStatus "Dipped Beam Activated Status";
BA_ "SysSignalName" SG_ 299 DippedBeamActStatus "DippedBeamActStatus";
BA_ "CompuMethodName" SG_ 299 LHZCU_20ms_Group03_Reserved5 "LHZCU_20ms_Group03_Reserved5";
BA_ "GenSigStartValue" SG_ 299 LHZCU_20ms_Group03_Reserved5 31;
BA_ "ISignalName" SG_ 299 LHZCU_20ms_Group03_Reserved5 "ILHZCU_20ms_Group03_Reserved5";
BA_ "SysSignalName" SG_ 299 LHZCU_20ms_Group03_Reserved5 "LHZCU_20ms_Group03_Reserved5";
BA_ "CompuMethodName" SG_ 299 RevsLghtCtrl "RevsLghtCtrl";
BA_ "ISignalName" SG_ 299 RevsLghtCtrl "IRevsLghtCtrl";
BA_ "LongName" SG_ 299 RevsLghtCtrl "Reverse_Light_Control";
BA_ "SysSignalName" SG_ 299 RevsLghtCtrl "RevsLghtCtrl";
BA_ "CompuMethodName" SG_ 299 PriySSBA "PriySSBA";
BA_ "ISignalName" SG_ 299 PriySSBA "IPriySSBA";
BA_ "LongName" SG_ 299 PriySSBA "Primary_Start_Stop_Button_Active";
BA_ "SysSignalName" SG_ 299 PriySSBA "PriySSBA";
BA_ "CompuMethodName" SG_ 299 PriySSBAV "PriySSBAV";
BA_ "ISignalName" SG_ 299 PriySSBAV "IPriySSBAV";
BA_ "LongName" SG_ 299 PriySSBAV "Primary_Start_Stop_Button_Active_Validity";
BA_ "SysSignalName" SG_ 299 PriySSBAV "PriySSBAV";
BA_ "CompuMethodName" SG_ 299 SecySSBA "SecySSBA";
BA_ "ISignalName" SG_ 299 SecySSBA "ISecySSBA";
BA_ "LongName" SG_ 299 SecySSBA "Secondary_Start_Stop_Button_Active";
BA_ "SysSignalName" SG_ 299 SecySSBA "SecySSBA";
BA_ "CompuMethodName" SG_ 299 SecySSBAV "SecySSBAV";
BA_ "ISignalName" SG_ 299 SecySSBAV "ISecySSBAV";
BA_ "LongName" SG_ 299 SecySSBAV "Secondary_Start_Stop_Button_Active_Validity";
BA_ "SysSignalName" SG_ 299 SecySSBAV "SecySSBAV";
BA_ "CompuMethodName" SG_ 299 SSBTrigd "SSBTrigd";
BA_ "ISignalName" SG_ 299 SSBTrigd "ISSBTrigd";
BA_ "LongName" SG_ 299 SSBTrigd "Start Stop Button Triggered";
BA_ "SysSignalName" SG_ 299 SSBTrigd "SSBTrigd";
BA_ "CompuMethodName" SG_ 299 RMainBeamLghtCtrl "RMainBeamLghtCtrl";
BA_ "ISignalName" SG_ 299 RMainBeamLghtCtrl "IRMainBeamLghtCtrl";
BA_ "LongName" SG_ 299 RMainBeamLghtCtrl "Right_Main_beam_Light _Control";
BA_ "SysSignalName" SG_ 299 RMainBeamLghtCtrl "RMainBeamLghtCtrl";
BA_ "CompuMethodName" SG_ 299 LMainBeamLghtCtrl "LMainBeamLghtCtrl";
BA_ "ISignalName" SG_ 299 LMainBeamLghtCtrl "ILMainBeamLghtCtrl";
BA_ "LongName" SG_ 299 LMainBeamLghtCtrl "Left_Main_beam_Light _Control";
BA_ "SysSignalName" SG_ 299 LMainBeamLghtCtrl "LMainBeamLghtCtrl";
BA_ "CompuMethodName" SG_ 299 RRDircnLghtCtrl "RRDircnLghtCtrl";
BA_ "ISignalName" SG_ 299 RRDircnLghtCtrl "IRRDircnLghtCtrl";
BA_ "LongName" SG_ 299 RRDircnLghtCtrl "Right_Rear_Direction_Light_Control";
BA_ "SysSignalName" SG_ 299 RRDircnLghtCtrl "RRDircnLghtCtrl";
BA_ "CompuMethodName" SG_ 299 RLDircnLghtCtrl "RLDircnLghtCtrl";
BA_ "ISignalName" SG_ 299 RLDircnLghtCtrl "IRLDircnLghtCtrl";
BA_ "LongName" SG_ 299 RLDircnLghtCtrl "Left_Rear_Direction_Light_Control";
BA_ "SysSignalName" SG_ 299 RLDircnLghtCtrl "RLDircnLghtCtrl";
BA_ "CompuMethodName" SG_ 299 FRDircnLghtCtrl "FRDircnLghtCtrl";
BA_ "ISignalName" SG_ 299 FRDircnLghtCtrl "IFRDircnLghtCtrl";
BA_ "LongName" SG_ 299 FRDircnLghtCtrl "Right_Front_Direction_Light_Control";
BA_ "SysSignalName" SG_ 299 FRDircnLghtCtrl "FRDircnLghtCtrl";
BA_ "CompuMethodName" SG_ 299 FLDircnLghtCtrl "FLDircnLghtCtrl";
BA_ "ISignalName" SG_ 299 FLDircnLghtCtrl "IFLDircnLghtCtrl";
BA_ "LongName" SG_ 299 FLDircnLghtCtrl "Left_Front_Direction_Light_Control";
BA_ "SysSignalName" SG_ 299 FLDircnLghtCtrl "FLDircnLghtCtrl";
BA_ "CompuMethodName" SG_ 299 BrkLghtCtrl "BrkLghtCtrl";
BA_ "ISignalName" SG_ 299 BrkLghtCtrl "IBrkLghtCtrl";
BA_ "LongName" SG_ 299 BrkLghtCtrl "Brake_Light_Control";
BA_ "SysSignalName" SG_ 299 BrkLghtCtrl "BrkLghtCtrl";
BA_ "CompuMethodName" SG_ 299 HzrdLghtSwReq "HzrdLghtSwReq";
BA_ "ISignalName" SG_ 299 HzrdLghtSwReq "IHzrdLghtSwReq";
BA_ "LongName" SG_ 299 HzrdLghtSwReq "Hazard_Light_Switch_Request";
BA_ "SysSignalName" SG_ 299 HzrdLghtSwReq "HzrdLghtSwReq";
BA_ "CompuMethodName" SG_ 566 FindCarFuncInfoDsp "FindCarFuncInfoDsp";
BA_ "ISignalName" SG_ 566 FindCarFuncInfoDsp "IFindCarFuncInfoDsp";
BA_ "LongName" SG_ 566 FindCarFuncInfoDsp "Find car function information Display";
BA_ "SysSignalName" SG_ 566 FindCarFuncInfoDsp "FindCarFuncInfoDsp";
BA_ "CompuMethodName" SG_ 566 FLDoorHndlPESwtActv "FLDoorHndlPESwtActv";
BA_ "ISignalName" SG_ 566 FLDoorHndlPESwtActv "IFLDoorHndlPESwtActv";
BA_ "LongName" SG_ 566 FLDoorHndlPESwtActv "Front Left Door Handle Passive Entry Switch Active";
BA_ "SysSignalName" SG_ 566 FLDoorHndlPESwtActv "FLDoorHndlPESwtActv";
BA_ "CompuMethodName" SG_ 566 FRDoorHndlPESwtActv "FRDoorHndlPESwtActv";
BA_ "ISignalName" SG_ 566 FRDoorHndlPESwtActv "IFRDoorHndlPESwtActv";
BA_ "LongName" SG_ 566 FRDoorHndlPESwtActv "Front Right Door Handle Passive Entry Switch Active";
BA_ "SysSignalName" SG_ 566 FRDoorHndlPESwtActv "FRDoorHndlPESwtActv";
BA_ "CompuMethodName" SG_ 566 BrkLghtSwStsV "BrkLghtSwStsV";
BA_ "ISignalName" SG_ 566 BrkLghtSwStsV "IBrkLghtSwStsV";
BA_ "LongName" SG_ 566 BrkLghtSwStsV "Brake_Light_Switch _Status_Validty";
BA_ "SysSignalName" SG_ 566 BrkLghtSwStsV "BrkLghtSwStsV";
BA_ "CompuMethodName" SG_ 566 BrkLghtSwSts "BrkLghtSwSts";
BA_ "ISignalName" SG_ 566 BrkLghtSwSts "IBrkLghtSwSts";
BA_ "LongName" SG_ 566 BrkLghtSwSts "Brake Light Switch Status";
BA_ "SysSignalName" SG_ 566 BrkLghtSwSts "BrkLghtSwSts";
BA_ "CompuMethodName" SG_ 566 RrWiperReq "RrWiperReq";
BA_ "ISignalName" SG_ 566 RrWiperReq "IRrWiperReq";
BA_ "LongName" SG_ 566 RrWiperReq "Rear Wiper Request";
BA_ "SysSignalName" SG_ 566 RrWiperReq "RrWiperReq";
BA_ "CompuMethodName" SG_ 566 MainBeamLghtSwSts "MainBeamLghtSwSts";
BA_ "ISignalName" SG_ 566 MainBeamLghtSwSts "IMainBeamLghtSwSts";
BA_ "LongName" SG_ 566 MainBeamLghtSwSts "Main beam Light switch  Status";
BA_ "SysSignalName" SG_ 566 MainBeamLghtSwSts "MainBeamLghtSwSts";
BA_ "CompuMethodName" SG_ 566 DircnIndLghtSwSts "DircnIndLghtSwSts";
BA_ "ISignalName" SG_ 566 DircnIndLghtSwSts "IDircnIndLghtSwSts";
BA_ "LongName" SG_ 566 DircnIndLghtSwSts "Direction_Indication_Light_Switch_Status";
BA_ "SysSignalName" SG_ 566 DircnIndLghtSwSts "DircnIndLghtSwSts";
BA_ "CompuMethodName" SG_ 566 LdspcRlseSwtActv "LdspcRlseSwtActv";
BA_ "ISignalName" SG_ 566 LdspcRlseSwtActv "ILdspcRlseSwtActv";
BA_ "LongName" SG_ 566 LdspcRlseSwtActv "Loadspace Release Switch Active";
BA_ "SysSignalName" SG_ 566 LdspcRlseSwtActv "LdspcRlseSwtActv";
BA_ "CompuMethodName" SG_ 566 FLDSP_RRWinSwtSts "FLDSP_RRWinSwtSts";
BA_ "ISignalName" SG_ 566 FLDSP_RRWinSwtSts "IFLDSP_RRWinSwtSts";
BA_ "LongName" SG_ 566 FLDSP_RRWinSwtSts "Rear Right Window Driver Switch Status";
BA_ "SysSignalName" SG_ 566 FLDSP_RRWinSwtSts "FLDSP_RRWinSwtSts";
BA_ "CompuMethodName" SG_ 566 FLDSP_RLWinSwtSts "FLDSP_RLWinSwtSts";
BA_ "ISignalName" SG_ 566 FLDSP_RLWinSwtSts "IFLDSP_RLWinSwtSts";
BA_ "LongName" SG_ 566 FLDSP_RLWinSwtSts "Rear Left Window Driver Switch Status";
BA_ "SysSignalName" SG_ 566 FLDSP_RLWinSwtSts "FLDSP_RLWinSwtSts";
BA_ "CompuMethodName" SG_ 566 FLDSP_FRWinSwtSts "FLDSP_FRWinSwtSts";
BA_ "ISignalName" SG_ 566 FLDSP_FRWinSwtSts "IFLDSP_FRWinSwtSts";
BA_ "LongName" SG_ 566 FLDSP_FRWinSwtSts "Front Right Window Driver Switch Status";
BA_ "SysSignalName" SG_ 566 FLDSP_FRWinSwtSts "FLDSP_FRWinSwtSts";
BA_ "CompuMethodName" SG_ 566 BrkPdlTrigd "BrkPdlTrigd";
BA_ "ISignalName" SG_ 566 BrkPdlTrigd "IBrkPdlTrigd";
BA_ "LongName" SG_ 566 BrkPdlTrigd "Brake Pedal Triggerd";
BA_ "SysSignalName" SG_ 566 BrkPdlTrigd "BrkPdlTrigd";
BA_ "CompuMethodName" SG_ 566 FLWinLclSwtSts "FLWinLclSwtSts";
BA_ "ISignalName" SG_ 566 FLWinLclSwtSts "IFLWinLclSwtSts";
BA_ "LongName" SG_ 566 FLWinLclSwtSts "Front Left Window Local Switch Status";
BA_ "SysSignalName" SG_ 566 FLWinLclSwtSts "FLWinLclSwtSts";
BA_ "CompuMethodName" SG_ 566 ExtrLckActnIndcn "ExtrLckActnIndcn";
BA_ "ISignalName" SG_ 566 ExtrLckActnIndcn "IExtrLckActnIndcn";
BA_ "LongName" SG_ 566 ExtrLckActnIndcn "Exterior Lock Action Indication";
BA_ "SysSignalName" SG_ 566 ExtrLckActnIndcn "ExtrLckActnIndcn";
BA_ "CompuMethodName" SG_ 566 AutoMainBeamLghtSts "AutoMainBeamLghtSts";
BA_ "ISignalName" SG_ 566 AutoMainBeamLghtSts "IAutoMainBeamLghtSts";
BA_ "LongName" SG_ 566 AutoMainBeamLghtSts "Auto_Main_Beam_Light_Status";
BA_ "SysSignalName" SG_ 566 AutoMainBeamLghtSts "AutoMainBeamLghtSts";
BA_ "CompuMethodName" SG_ 566 DrvrDetSnsrFltSts "DrvrDetSnsrFltSts";
BA_ "ISignalName" SG_ 566 DrvrDetSnsrFltSts "IDrvrDetSnsrFltSts";
BA_ "LongName" SG_ 566 DrvrDetSnsrFltSts "Driver Detected Sensor Fault Status";
BA_ "SysSignalName" SG_ 566 DrvrDetSnsrFltSts "DrvrDetSnsrFltSts";
BA_ "CompuMethodName" SG_ 566 DircnIndLghtMdSts "DircnIndLghtMdSts";
BA_ "ISignalName" SG_ 566 DircnIndLghtMdSts "IDircnIndLghtMdSts";
BA_ "LongName" SG_ 566 DircnIndLghtMdSts "Direction Indication Light Mode Status";
BA_ "SysSignalName" SG_ 566 DircnIndLghtMdSts "DircnIndLghtMdSts";
BA_ "CompuMethodName" SG_ 652 LHZCU_50ms_Group06_CRC "LHZCU_50ms_Group06_CRC";
BA_ "ISignalName" SG_ 652 LHZCU_50ms_Group06_CRC "ILHZCU_50ms_Group06_CRC";
BA_ "LongName" SG_ 652 LHZCU_50ms_Group06_CRC "LHZCU_50ms_Group06_CRC";
BA_ "SysSignalName" SG_ 652 LHZCU_50ms_Group06_CRC "LHZCU_50ms_Group06_CRC";
BA_ "CompuMethodName" SG_ 652 LHZCU_50ms_Group06_RC "LHZCU_50ms_Group06_RC";
BA_ "ISignalName" SG_ 652 LHZCU_50ms_Group06_RC "ILHZCU_50ms_Group06_RC";
BA_ "LongName" SG_ 652 LHZCU_50ms_Group06_RC "LHZCU_50ms_Group06_RC";
BA_ "SysSignalName" SG_ 652 LHZCU_50ms_Group06_RC "LHZCU_50ms_Group06_RC";
BA_ "CompuMethodName" SG_ 652 DrvrDetSts "DrvrDetSts";
BA_ "ISignalName" SG_ 652 DrvrDetSts "IDrvrDetSts";
BA_ "LongName" SG_ 652 DrvrDetSts "Driver Detected Status";
BA_ "SysSignalName" SG_ 652 DrvrDetSts "DrvrDetSts";
BA_ "CompuMethodName" SG_ 652 RLDoorOpenSts "RLDoorOpenSts";
BA_ "ISignalName" SG_ 652 RLDoorOpenSts "IRLDoorOpenSts";
BA_ "LongName" SG_ 652 RLDoorOpenSts "Rear Left Door Open Status";
BA_ "SysSignalName" SG_ 652 RLDoorOpenSts "RLDoorOpenSts";
BA_ "CompuMethodName" SG_ 652 LHZCU_50ms_Group06_Reserved1 "LHZCU_50ms_Group06_Reserved1";
BA_ "GenSigStartValue" SG_ 652 LHZCU_50ms_Group06_Reserved1 1;
BA_ "ISignalName" SG_ 652 LHZCU_50ms_Group06_Reserved1 "ILHZCU_50ms_Group06_Reserved1";
BA_ "SysSignalName" SG_ 652 LHZCU_50ms_Group06_Reserved1 "LHZCU_50ms_Group06_Reserved1";
BA_ "CompuMethodName" SG_ 652 DrvrDoorOpenSts "DrvrDoorOpenSts";
BA_ "ISignalName" SG_ 652 DrvrDoorOpenSts "IDrvrDoorOpenSts";
BA_ "LongName" SG_ 652 DrvrDoorOpenSts "Driver Door Open Status";
BA_ "SysSignalName" SG_ 652 DrvrDoorOpenSts "DrvrDoorOpenSts";
BA_ "CompuMethodName" SG_ 652 BntOpenSts "BntOpenSts";
BA_ "ISignalName" SG_ 652 BntOpenSts "IBntOpenSts";
BA_ "LongName" SG_ 652 BntOpenSts "Bonnet Open Status";
BA_ "SysSignalName" SG_ 652 BntOpenSts "BntOpenSts";
BA_ "CompuMethodName" SG_ 652 VehLckSts "VehLckSts";
BA_ "GenSigStartValue" SG_ 652 VehLckSts 7;
BA_ "ISignalName" SG_ 652 VehLckSts "IVehLckSts";
BA_ "LongName" SG_ 652 VehLckSts "Vehicle Lock Status";
BA_ "SysSignalName" SG_ 652 VehLckSts "VehLckSts";
BA_ "CompuMethodName" SG_ 652 LHZCU_50ms_Group06_Reserved2 "LHZCU_50ms_Group06_Reserved2";
BA_ "GenSigStartValue" SG_ 652 LHZCU_50ms_Group06_Reserved2 255;
BA_ "ISignalName" SG_ 652 LHZCU_50ms_Group06_Reserved2 "ILHZCU_50ms_Group06_Reserved2";
BA_ "SysSignalName" SG_ 652 LHZCU_50ms_Group06_Reserved2 "LHZCU_50ms_Group06_Reserved2";
BA_ "CompuMethodName" SG_ 652 LHZCU_50ms_Group06_Reserved3 "LHZCU_50ms_Group06_Reserved3";
BA_ "GenSigStartValue" SG_ 652 LHZCU_50ms_Group06_Reserved3 255;
BA_ "ISignalName" SG_ 652 LHZCU_50ms_Group06_Reserved3 "ILHZCU_50ms_Group06_Reserved3";
BA_ "SysSignalName" SG_ 652 LHZCU_50ms_Group06_Reserved3 "LHZCU_50ms_Group06_Reserved3";
BA_ "CompuMethodName" SG_ 652 LHZCU_50ms_Group06_Reserved5 "LHZCU_50ms_Group06_Reserved5";
BA_ "GenSigStartValue" SG_ 652 LHZCU_50ms_Group06_Reserved5 7;
BA_ "ISignalName" SG_ 652 LHZCU_50ms_Group06_Reserved5 "ILHZCU_50ms_Group06_Reserved5";
BA_ "SysSignalName" SG_ 652 LHZCU_50ms_Group06_Reserved5 "LHZCU_50ms_Group06_Reserved5";
BA_ "CompuMethodName" SG_ 652 RLSInitnFltPrst "RLSInitnFltPrst";
BA_ "ISignalName" SG_ 652 RLSInitnFltPrst "IRLSInitnFltPrst";
BA_ "LongName" SG_ 652 RLSInitnFltPrst "Rain Light Sensor Initialization Fault Present";
BA_ "SysSignalName" SG_ 652 RLSInitnFltPrst "RLSInitnFltPrst";
BA_ "CompuMethodName" SG_ 652 LHZCU_50ms_Group06_Reserved4 "LHZCU_50ms_Group06_Reserved4";
BA_ "GenSigStartValue" SG_ 652 LHZCU_50ms_Group06_Reserved4 15;
BA_ "ISignalName" SG_ 652 LHZCU_50ms_Group06_Reserved4 "ILHZCU_50ms_Group06_Reserved4";
BA_ "SysSignalName" SG_ 652 LHZCU_50ms_Group06_Reserved4 "LHZCU_50ms_Group06_Reserved4";
BA_ "CompuMethodName" SG_ 652 LHZCU_50ms_Group06_Reserved7 "LHZCU_50ms_Group06_Reserved7";
BA_ "GenSigStartValue" SG_ 652 LHZCU_50ms_Group06_Reserved7 1;
BA_ "ISignalName" SG_ 652 LHZCU_50ms_Group06_Reserved7 "ILHZCU_50ms_Group06_Reserved7";
BA_ "SysSignalName" SG_ 652 LHZCU_50ms_Group06_Reserved7 "LHZCU_50ms_Group06_Reserved7";
BA_ "CompuMethodName" SG_ 652 DirnLghtSftyMonErr "DirnLghtSftyMonErr";
BA_ "ISignalName" SG_ 652 DirnLghtSftyMonErr "IDirnLghtSftyMonErr";
BA_ "LongName" SG_ 652 DirnLghtSftyMonErr "Direction_Light_safety monitor error";
BA_ "SysSignalName" SG_ 652 DirnLghtSftyMonErr "DirnLghtSftyMonErr";
BA_ "CompuMethodName" SG_ 652 LHZCU_50ms_Group06_Reserved6 "LHZCU_50ms_Group06_Reserved6";
BA_ "GenSigStartValue" SG_ 652 LHZCU_50ms_Group06_Reserved6 31;
BA_ "ISignalName" SG_ 652 LHZCU_50ms_Group06_Reserved6 "ILHZCU_50ms_Group06_Reserved6";
BA_ "SysSignalName" SG_ 652 LHZCU_50ms_Group06_Reserved6 "LHZCU_50ms_Group06_Reserved6";
BA_ "CompuMethodName" SG_ 652 LHZCU_50ms_Group06_Reserved8 "LHZCU_50ms_Group06_Reserved8";
BA_ "GenSigStartValue" SG_ 652 LHZCU_50ms_Group06_Reserved8 255;
BA_ "ISignalName" SG_ 652 LHZCU_50ms_Group06_Reserved8 "ILHZCU_50ms_Group06_Reserved8";
BA_ "SysSignalName" SG_ 652 LHZCU_50ms_Group06_Reserved8 "LHZCU_50ms_Group06_Reserved8";
BA_ "CompuMethodName" SG_ 547 SideLghtSts "SideLghtSts";
BA_ "ISignalName" SG_ 547 SideLghtSts "ISideLghtSts";
BA_ "LongName" SG_ 547 SideLghtSts "Side_Light_Status";
BA_ "SysSignalName" SG_ 547 SideLghtSts "SideLghtSts";
BA_ "CompuMethodName" SG_ 547 LHZCUeFs12Sts "LHZCUeFs12Sts";
BA_ "ISignalName" SG_ 547 LHZCUeFs12Sts "ILHZCUeFs12Sts";
BA_ "LongName" SG_ 547 LHZCUeFs12Sts "LHZCU eFuse12 Status";
BA_ "SysSignalName" SG_ 547 LHZCUeFs12Sts "LHZCUeFs12Sts";
BA_ "CompuMethodName" SG_ 547 LHZCUeFs12DiagSts "LHZCUeFs12DiagSts";
BA_ "ISignalName" SG_ 547 LHZCUeFs12DiagSts "ILHZCUeFs12DiagSts";
BA_ "LongName" SG_ 547 LHZCUeFs12DiagSts "LHZCU_eFuse12 Diagnostic Status";
BA_ "SysSignalName" SG_ 547 LHZCUeFs12DiagSts "LHZCUeFs12DiagSts";
BA_ "CompuMethodName" SG_ 547 LHZCUeSw17Sts "LHZCUeSw17Sts";
BA_ "ISignalName" SG_ 547 LHZCUeSw17Sts "ILHZCUeSw17Sts";
BA_ "LongName" SG_ 547 LHZCUeSw17Sts "LHZCU eSwitch17 Status";
BA_ "SysSignalName" SG_ 547 LHZCUeSw17Sts "LHZCUeSw17Sts";
BA_ "CompuMethodName" SG_ 547 LHZCUeSw17DiagSts "LHZCUeSw17DiagSts";
BA_ "ISignalName" SG_ 547 LHZCUeSw17DiagSts "ILHZCUeSw17DiagSts";
BA_ "LongName" SG_ 547 LHZCUeSw17DiagSts "LHZCU eSwitch17 Diagnostic Status";
BA_ "SysSignalName" SG_ 547 LHZCUeSw17DiagSts "LHZCUeSw17DiagSts";
BA_ "CompuMethodName" SG_ 547 LHZCUeSw16Sts "LHZCUeSw16Sts";
BA_ "ISignalName" SG_ 547 LHZCUeSw16Sts "ILHZCUeSw16Sts";
BA_ "LongName" SG_ 547 LHZCUeSw16Sts "LHZCU eSwitch16 Status";
BA_ "SysSignalName" SG_ 547 LHZCUeSw16Sts "LHZCUeSw16Sts";
BA_ "CompuMethodName" SG_ 547 LHZCUeSw16DiagSts "LHZCUeSw16DiagSts";
BA_ "ISignalName" SG_ 547 LHZCUeSw16DiagSts "ILHZCUeSw16DiagSts";
BA_ "LongName" SG_ 547 LHZCUeSw16DiagSts "LHZCU eSwitch16 Diagnostic Status";
BA_ "SysSignalName" SG_ 547 LHZCUeSw16DiagSts "LHZCUeSw16DiagSts";
BA_ "CompuMethodName" SG_ 547 LHZCUeSw15Sts "LHZCUeSw15Sts";
BA_ "ISignalName" SG_ 547 LHZCUeSw15Sts "ILHZCUeSw15Sts";
BA_ "LongName" SG_ 547 LHZCUeSw15Sts "LHZCU eSwitch15 Status";
BA_ "SysSignalName" SG_ 547 LHZCUeSw15Sts "LHZCUeSw15Sts";
BA_ "CompuMethodName" SG_ 547 LHZCUeSw15DiagSts "LHZCUeSw15DiagSts";
BA_ "ISignalName" SG_ 547 LHZCUeSw15DiagSts "ILHZCUeSw15DiagSts";
BA_ "LongName" SG_ 547 LHZCUeSw15DiagSts "LHZCU eSwitch15 Diagnostic Status";
BA_ "SysSignalName" SG_ 547 LHZCUeSw15DiagSts "LHZCUeSw15DiagSts";
BA_ "CompuMethodName" SG_ 547 LHZCUeSw14Sts "LHZCUeSw14Sts";
BA_ "ISignalName" SG_ 547 LHZCUeSw14Sts "ILHZCUeSw14Sts";
BA_ "LongName" SG_ 547 LHZCUeSw14Sts "LHZCU eSwitch14 Status";
BA_ "SysSignalName" SG_ 547 LHZCUeSw14Sts "LHZCUeSw14Sts";
BA_ "CompuMethodName" SG_ 547 LHZCUeSw14DiagSts "LHZCUeSw14DiagSts";
BA_ "ISignalName" SG_ 547 LHZCUeSw14DiagSts "ILHZCUeSw14DiagSts";
BA_ "LongName" SG_ 547 LHZCUeSw14DiagSts "LHZCU eSwitch14 Diagnostic Status";
BA_ "SysSignalName" SG_ 547 LHZCUeSw14DiagSts "LHZCUeSw14DiagSts";
BA_ "CompuMethodName" SG_ 547 LHZCUeSw13Sts "LHZCUeSw13Sts";
BA_ "ISignalName" SG_ 547 LHZCUeSw13Sts "ILHZCUeSw13Sts";
BA_ "LongName" SG_ 547 LHZCUeSw13Sts "LHZCU eSwitch13 Status";
BA_ "SysSignalName" SG_ 547 LHZCUeSw13Sts "LHZCUeSw13Sts";
BA_ "CompuMethodName" SG_ 547 LHZCUeSw13DiagSts "LHZCUeSw13DiagSts";
BA_ "ISignalName" SG_ 547 LHZCUeSw13DiagSts "ILHZCUeSw13DiagSts";
BA_ "LongName" SG_ 547 LHZCUeSw13DiagSts "LHZCU eSwitch13 Diagnostic Status";
BA_ "SysSignalName" SG_ 547 LHZCUeSw13DiagSts "LHZCUeSw13DiagSts";
BA_ "CompuMethodName" SG_ 547 LHZCUeSw12Sts "LHZCUeSw12Sts";
BA_ "ISignalName" SG_ 547 LHZCUeSw12Sts "ILHZCUeSw12Sts";
BA_ "LongName" SG_ 547 LHZCUeSw12Sts "LHZCU eSwitch12 Status";
BA_ "SysSignalName" SG_ 547 LHZCUeSw12Sts "LHZCUeSw12Sts";
BA_ "CompuMethodName" SG_ 547 LHZCUeSw12DiagSts "LHZCUeSw12DiagSts";
BA_ "ISignalName" SG_ 547 LHZCUeSw12DiagSts "ILHZCUeSw12DiagSts";
BA_ "LongName" SG_ 547 LHZCUeSw12DiagSts "LHZCU eSwitch12 Diagnostic Status";
BA_ "SysSignalName" SG_ 547 LHZCUeSw12DiagSts "LHZCUeSw12DiagSts";
BA_ "CompuMethodName" SG_ 547 LHZCUeFs13Sts "LHZCUeFs13Sts";
BA_ "ISignalName" SG_ 547 LHZCUeFs13Sts "ILHZCUeFs13Sts";
BA_ "LongName" SG_ 547 LHZCUeFs13Sts "LHZCU eFuse13 Status";
BA_ "SysSignalName" SG_ 547 LHZCUeFs13Sts "LHZCUeFs13Sts";
BA_ "CompuMethodName" SG_ 547 LHZCUeFs13DiagSts "LHZCUeFs13DiagSts";
BA_ "ISignalName" SG_ 547 LHZCUeFs13DiagSts "ILHZCUeFs13DiagSts";
BA_ "LongName" SG_ 547 LHZCUeFs13DiagSts "LHZCU_eFuse13 Diagnostic Status";
BA_ "SysSignalName" SG_ 547 LHZCUeFs13DiagSts "LHZCUeFs13DiagSts";
BA_ "CompuMethodName" SG_ 994 RFCTWrnng_ADAS "RFCTWrnng_ADAS";
BA_ "ISignalName" SG_ 994 RFCTWrnng_ADAS "IRFCTWrnng_ADAS";
BA_ "LongName" SG_ 994 RFCTWrnng_ADAS "Right FCTAB_Warning";
BA_ "SysSignalName" SG_ 994 RFCTWrnng_ADAS "RFCTWrnng_ADAS";
BA_ "CompuMethodName" SG_ 994 FCTBSysFltSts_ADAS "FCTBSysFltSts_ADAS";
BA_ "ISignalName" SG_ 994 FCTBSysFltSts_ADAS "IFCTBSysFltSts_ADAS";
BA_ "LongName" SG_ 994 FCTBSysFltSts_ADAS "FCTB System Fault Status";
BA_ "SysSignalName" SG_ 994 FCTBSysFltSts_ADAS "FCTBSysFltSts_ADAS";
BA_ "CompuMethodName" SG_ 994 FCTSysFltSts_ADAS "FCTSysFltSts_ADAS";
BA_ "ISignalName" SG_ 994 FCTSysFltSts_ADAS "IFCTSysFltSts_ADAS";
BA_ "LongName" SG_ 994 FCTSysFltSts_ADAS "FCTA System Fault Status";
BA_ "SysSignalName" SG_ 994 FCTSysFltSts_ADAS "FCTSysFltSts_ADAS";
BA_ "CompuMethodName" SG_ 994 FCTSwSts_ADAS "FCTSwSts_ADAS";
BA_ "GenSigStartValue" SG_ 994 FCTSwSts_ADAS 1;
BA_ "ISignalName" SG_ 994 FCTSwSts_ADAS "IFCTSwSts_ADAS";
BA_ "LongName" SG_ 994 FCTSwSts_ADAS "FCTAB  Switch status";
BA_ "SysSignalName" SG_ 994 FCTSwSts_ADAS "FCTSwSts_ADAS";
BA_ "CompuMethodName" SG_ 994 LFCTWrnng_ADAS "LFCTWrnng_ADAS";
BA_ "ISignalName" SG_ 994 LFCTWrnng_ADAS "ILFCTWrnng_ADAS";
BA_ "LongName" SG_ 994 LFCTWrnng_ADAS "Left FCTAB_Warning";
BA_ "SysSignalName" SG_ 994 LFCTWrnng_ADAS "LFCTWrnng_ADAS";
BA_ "CompuMethodName" SG_ 484 RFSDA_20ms_Group02_CRC "RFSDA_20ms_Group02_CRC";
BA_ "ISignalName" SG_ 484 RFSDA_20ms_Group02_CRC "IRFSDA_20ms_Group02_CRC";
BA_ "LongName" SG_ 484 RFSDA_20ms_Group02_CRC "RFSDA_20ms_Group02_CRC";
BA_ "SysSignalName" SG_ 484 RFSDA_20ms_Group02_CRC "RFSDA_20ms_Group02_CRC";
BA_ "CompuMethodName" SG_ 484 RFSDA_20ms_Group02_RC "RFSDA_20ms_Group02_RC";
BA_ "ISignalName" SG_ 484 RFSDA_20ms_Group02_RC "IRFSDA_20ms_Group02_RC";
BA_ "LongName" SG_ 484 RFSDA_20ms_Group02_RC "RFSDA_20ms_Group02_RC";
BA_ "SysSignalName" SG_ 484 RFSDA_20ms_Group02_RC "RFSDA_20ms_Group02_RC";
BA_ "CompuMethodName" SG_ 484 RFSDA_20ms_Group02_Reserved1 "RFSDA_20ms_Group02_Reserved1";
BA_ "GenSigStartValue" SG_ 484 RFSDA_20ms_Group02_Reserved1 3;
BA_ "ISignalName" SG_ 484 RFSDA_20ms_Group02_Reserved1 "IRFSDA_20ms_Group02_Reserved1";
BA_ "SysSignalName" SG_ 484 RFSDA_20ms_Group02_Reserved1 "RFSDA_20ms_Group02_Reserved1";
BA_ "CompuMethodName" SG_ 484 AEBDclReqSts_ADAS "AEBDclReqSts_ADAS";
BA_ "ISignalName" SG_ 484 AEBDclReqSts_ADAS "IAEBDclReqSts_ADAS";
BA_ "LongName" SG_ 484 AEBDclReqSts_ADAS "Autonomous Emergency Braking Deceleration Request Status";
BA_ "SysSignalName" SG_ 484 AEBDclReqSts_ADAS "AEBDclReqSts_ADAS";
BA_ "CompuMethodName" SG_ 484 AEBDclReqToqVal_ADAS "AEBDclReqToqVal_ADAS";
BA_ "ISignalName" SG_ 484 AEBDclReqToqVal_ADAS "IAEBDclReqToqVal_ADAS";
BA_ "LongName" SG_ 484 AEBDclReqToqVal_ADAS "Autonomous Emergency Braking Deceleration Request Torque Value";
BA_ "SysSignalName" SG_ 484 AEBDclReqToqVal_ADAS "AEBDclReqToqVal_ADAS";
BA_ "CompuMethodName" SG_ 484 AEBDclReqVal_ADAS "AEBDclReqVal_ADAS";
BA_ "GenSigStartValue" SG_ 484 AEBDclReqVal_ADAS 127;
BA_ "ISignalName" SG_ 484 AEBDclReqVal_ADAS "IAEBDclReqVal_ADAS";
BA_ "LongName" SG_ 484 AEBDclReqVal_ADAS "Autonomous Emergency Braking Deceleration Request Value";
BA_ "SysSignalName" SG_ 484 AEBDclReqVal_ADAS "AEBDclReqVal_ADAS";
BA_ "CompuMethodName" SG_ 484 RFSDA_20ms_Group02_Reserved2 "RFSDA_20ms_Group02_Reserved2";
BA_ "GenSigStartValue" SG_ 484 RFSDA_20ms_Group02_Reserved2 255;
BA_ "ISignalName" SG_ 484 RFSDA_20ms_Group02_Reserved2 "IRFSDA_20ms_Group02_Reserved2";
BA_ "SysSignalName" SG_ 484 RFSDA_20ms_Group02_Reserved2 "RFSDA_20ms_Group02_Reserved2";
BA_ "CompuMethodName" SG_ 484 RFSDA_20ms_Group02_Reserved3 "RFSDA_20ms_Group02_Reserved3";
BA_ "GenSigStartValue" SG_ 484 RFSDA_20ms_Group02_Reserved3 255;
BA_ "ISignalName" SG_ 484 RFSDA_20ms_Group02_Reserved3 "IRFSDA_20ms_Group02_Reserved3";
BA_ "SysSignalName" SG_ 484 RFSDA_20ms_Group02_Reserved3 "RFSDA_20ms_Group02_Reserved3";
BA_ "CompuMethodName" SG_ 484 RFSDA_20ms_Group02_Reserved4 "RFSDA_20ms_Group02_Reserved4";
BA_ "GenSigStartValue" SG_ 484 RFSDA_20ms_Group02_Reserved4 255;
BA_ "ISignalName" SG_ 484 RFSDA_20ms_Group02_Reserved4 "IRFSDA_20ms_Group02_Reserved4";
BA_ "SysSignalName" SG_ 484 RFSDA_20ms_Group02_Reserved4 "RFSDA_20ms_Group02_Reserved4";
BA_ "CompuMethodName" SG_ 484 RFSDA_20ms_Group02_Reserved5 "RFSDA_20ms_Group02_Reserved5";
BA_ "GenSigStartValue" SG_ 484 RFSDA_20ms_Group02_Reserved5 255;
BA_ "ISignalName" SG_ 484 RFSDA_20ms_Group02_Reserved5 "IRFSDA_20ms_Group02_Reserved5";
BA_ "SysSignalName" SG_ 484 RFSDA_20ms_Group02_Reserved5 "RFSDA_20ms_Group02_Reserved5";
BA_ "CompuMethodName" SG_ 484 RFSDA_20ms_Group02_Reserved6 "RFSDA_20ms_Group02_Reserved6";
BA_ "GenSigStartValue" SG_ 484 RFSDA_20ms_Group02_Reserved6 255;
BA_ "ISignalName" SG_ 484 RFSDA_20ms_Group02_Reserved6 "IRFSDA_20ms_Group02_Reserved6";
BA_ "SysSignalName" SG_ 484 RFSDA_20ms_Group02_Reserved6 "RFSDA_20ms_Group02_Reserved6";
BA_ "CompuMethodName" SG_ 484 RFSDA_20ms_Group02_Reserved7 "RFSDA_20ms_Group02_Reserved7";
BA_ "GenSigStartValue" SG_ 484 RFSDA_20ms_Group02_Reserved7 255;
BA_ "ISignalName" SG_ 484 RFSDA_20ms_Group02_Reserved7 "IRFSDA_20ms_Group02_Reserved7";
BA_ "SysSignalName" SG_ 484 RFSDA_20ms_Group02_Reserved7 "RFSDA_20ms_Group02_Reserved7";
BA_ "CompuMethodName" SG_ 484 RFSDA_20ms_Group02_Reserved8 "RFSDA_20ms_Group02_Reserved8";
BA_ "GenSigStartValue" SG_ 484 RFSDA_20ms_Group02_Reserved8 255;
BA_ "ISignalName" SG_ 484 RFSDA_20ms_Group02_Reserved8 "IRFSDA_20ms_Group02_Reserved8";
BA_ "SysSignalName" SG_ 484 RFSDA_20ms_Group02_Reserved8 "RFSDA_20ms_Group02_Reserved8";
BA_ "CompuMethodName" SG_ 484 RFSDA_20ms_Group02_Reserved9 "RFSDA_20ms_Group02_Reserved9";
BA_ "GenSigStartValue" SG_ 484 RFSDA_20ms_Group02_Reserved9 255;
BA_ "ISignalName" SG_ 484 RFSDA_20ms_Group02_Reserved9 "IRFSDA_20ms_Group02_Reserved9";
BA_ "SysSignalName" SG_ 484 RFSDA_20ms_Group02_Reserved9 "RFSDA_20ms_Group02_Reserved9";
BA_ "CompuMethodName" SG_ 484 RFSDA_20ms_Group02_Reserved10 "RFSDA_20ms_Group02_Reserved10";
BA_ "GenSigStartValue" SG_ 484 RFSDA_20ms_Group02_Reserved10 255;
BA_ "ISignalName" SG_ 484 RFSDA_20ms_Group02_Reserved10 "IRFSDA_20ms_Group02_Reserved10";
BA_ "SysSignalName" SG_ 484 RFSDA_20ms_Group02_Reserved10 "RFSDA_20ms_Group02_Reserved10";
BA_ "CompuMethodName" SG_ 484 RFSDA_20ms_Group02_Reserved11 "RFSDA_20ms_Group02_Reserved11";
BA_ "GenSigStartValue" SG_ 484 RFSDA_20ms_Group02_Reserved11 255;
BA_ "ISignalName" SG_ 484 RFSDA_20ms_Group02_Reserved11 "IRFSDA_20ms_Group02_Reserved11";
BA_ "SysSignalName" SG_ 484 RFSDA_20ms_Group02_Reserved11 "RFSDA_20ms_Group02_Reserved11";
BA_ "CompuMethodName" SG_ 484 RFSDA_20ms_Group02_Reserved12 "RFSDA_20ms_Group02_Reserved12";
BA_ "GenSigStartValue" SG_ 484 RFSDA_20ms_Group02_Reserved12 255;
BA_ "ISignalName" SG_ 484 RFSDA_20ms_Group02_Reserved12 "IRFSDA_20ms_Group02_Reserved12";
BA_ "SysSignalName" SG_ 484 RFSDA_20ms_Group02_Reserved12 "RFSDA_20ms_Group02_Reserved12";
BA_ "CompuMethodName" SG_ 1230 RFSDA_NM_BSMtoRMS_BKPCANFD "RFSDA_NM_BSMtoRMS_BKPCANFD";
BA_ "ISignalName" SG_ 1230 RFSDA_NM_BSMtoRMS_BKPCANFD "IRFSDA_NM_BSMtoRMS_BKPCANFD";
BA_ "LongName" SG_ 1230 RFSDA_NM_BSMtoRMS_BKPCANFD "RFSDA_NM_BSMtoRMS_BKPCANFD";
BA_ "SysSignalName" SG_ 1230 RFSDA_NM_BSMtoRMS_BKPCANFD "RFSDA_NM_BSMtoRMS_BKPCANFD";
BA_ "CompuMethodName" SG_ 1230 RFSDA_NM_PBSMtoRMS_BKPCANFD "RFSDA_NM_PBSMtoRMS_BKPCANFD";
BA_ "ISignalName" SG_ 1230 RFSDA_NM_PBSMtoRMS_BKPCANFD "IRFSDA_NM_PBSMtoRMS_BKPCANFD";
BA_ "LongName" SG_ 1230 RFSDA_NM_PBSMtoRMS_BKPCANFD "RFSDA_NM_PBSMtoRMS_BKPCANFD";
BA_ "SysSignalName" SG_ 1230 RFSDA_NM_PBSMtoRMS_BKPCANFD "RFSDA_NM_PBSMtoRMS_BKPCANFD";
BA_ "CompuMethodName" SG_ 1230 RFSDA_NM_RMStoNOS_BKPCANFD "RFSDA_NM_RMStoNOS_BKPCANFD";
BA_ "ISignalName" SG_ 1230 RFSDA_NM_RMStoNOS_BKPCANFD "IRFSDA_NM_RMStoNOS_BKPCANFD";
BA_ "LongName" SG_ 1230 RFSDA_NM_RMStoNOS_BKPCANFD "RFSDA_NM_RMStoNOS_BKPCANFD";
BA_ "SysSignalName" SG_ 1230 RFSDA_NM_RMStoNOS_BKPCANFD "RFSDA_NM_RMStoNOS_BKPCANFD";
BA_ "CompuMethodName" SG_ 1230 RFSDA_NM_RSStoNOS_BKPCANFD "RFSDA_NM_RSStoNOS_BKPCANFD";
BA_ "ISignalName" SG_ 1230 RFSDA_NM_RSStoNOS_BKPCANFD "IRFSDA_NM_RSStoNOS_BKPCANFD";
BA_ "LongName" SG_ 1230 RFSDA_NM_RSStoNOS_BKPCANFD "RFSDA_NM_RSStoNOS_BKPCANFD";
BA_ "SysSignalName" SG_ 1230 RFSDA_NM_RSStoNOS_BKPCANFD "RFSDA_NM_RSStoNOS_BKPCANFD";
BA_ "CompuMethodName" SG_ 1230 RFSDA_NM_RSStoRMS_BKPCANFD "RFSDA_NM_RSStoRMS_BKPCANFD";
BA_ "ISignalName" SG_ 1230 RFSDA_NM_RSStoRMS_BKPCANFD "IRFSDA_NM_RSStoRMS_BKPCANFD";
BA_ "LongName" SG_ 1230 RFSDA_NM_RSStoRMS_BKPCANFD "RFSDA_NM_RSStoRMS_BKPCANFD";
BA_ "SysSignalName" SG_ 1230 RFSDA_NM_RSStoRMS_BKPCANFD "RFSDA_NM_RSStoRMS_BKPCANFD";
BA_ "CompuMethodName" SG_ 1230 RFSDA_NM_NOStoRMS_BKPCANFD "RFSDA_NM_NOStoRMS_BKPCANFD";
BA_ "ISignalName" SG_ 1230 RFSDA_NM_NOStoRMS_BKPCANFD "IRFSDA_NM_NOStoRMS_BKPCANFD";
BA_ "LongName" SG_ 1230 RFSDA_NM_NOStoRMS_BKPCANFD "RFSDA_NM_NOStoRMS_BKPCANFD";
BA_ "SysSignalName" SG_ 1230 RFSDA_NM_NOStoRMS_BKPCANFD "RFSDA_NM_NOStoRMS_BKPCANFD";
BA_ "CompuMethodName" SG_ 1230 RFSDA_NM_NOSSta_BKPCANFD "RFSDA_NM_NOSSta_BKPCANFD";
BA_ "ISignalName" SG_ 1230 RFSDA_NM_NOSSta_BKPCANFD "IRFSDA_NM_NOSSta_BKPCANFD";
BA_ "LongName" SG_ 1230 RFSDA_NM_NOSSta_BKPCANFD "RFSDA_NM_NOSSta_BKPCANFD";
BA_ "SysSignalName" SG_ 1230 RFSDA_NM_NOSSta_BKPCANFD "RFSDA_NM_NOSSta_BKPCANFD";
BA_ "CompuMethodName" SG_ 1230 RFSDA_NM_RMSSta_BKPCANFD "RFSDA_NM_RMSSta_BKPCANFD";
BA_ "ISignalName" SG_ 1230 RFSDA_NM_RMSSta_BKPCANFD "IRFSDA_NM_RMSSta_BKPCANFD";
BA_ "LongName" SG_ 1230 RFSDA_NM_RMSSta_BKPCANFD "RFSDA_NM_RMSSta_BKPCANFD";
BA_ "SysSignalName" SG_ 1230 RFSDA_NM_RMSSta_BKPCANFD "RFSDA_NM_RMSSta_BKPCANFD";
BA_ "CompuMethodName" SG_ 1230 RFSDA_NWI_BKPCANFD "RFSDA_NWI_BKPCANFD";
BA_ "ISignalName" SG_ 1230 RFSDA_NWI_BKPCANFD "IRFSDA_NWI_BKPCANFD";
BA_ "LongName" SG_ 1230 RFSDA_NWI_BKPCANFD "RFSDA_BKPCANFD Network Wakeup Indication";
BA_ "SysSignalName" SG_ 1230 RFSDA_NWI_BKPCANFD "RFSDA_NWI_BKPCANFD";
BA_ "CompuMethodName" SG_ 1230 RFSDA_NOI_BKPCANFD "RFSDA_NOI_BKPCANFD";
BA_ "ISignalName" SG_ 1230 RFSDA_NOI_BKPCANFD "IRFSDA_NOI_BKPCANFD";
BA_ "LongName" SG_ 1230 RFSDA_NOI_BKPCANFD "RFSDA BKPCANFD Network Operation Indication";
BA_ "SysSignalName" SG_ 1230 RFSDA_NOI_BKPCANFD "RFSDA_NOI_BKPCANFD";
BA_ "CompuMethodName" SG_ 1230 RFSDA_NKI_BKPCANFD "RFSDA_NKI_BKPCANFD";
BA_ "ISignalName" SG_ 1230 RFSDA_NKI_BKPCANFD "IRFSDA_NKI_BKPCANFD";
BA_ "LongName" SG_ 1230 RFSDA_NKI_BKPCANFD "RFSDA BKPCANFD Network Keep Indication";
BA_ "SysSignalName" SG_ 1230 RFSDA_NKI_BKPCANFD "RFSDA_NKI_BKPCANFD";
BA_ "CompuMethodName" SG_ 725 RHRDA_50ms_Group04_CRC "RHRDA_50ms_Group04_CRC";
BA_ "ISignalName" SG_ 725 RHRDA_50ms_Group04_CRC "IRHRDA_50ms_Group04_CRC";
BA_ "SysSignalName" SG_ 725 RHRDA_50ms_Group04_CRC "RHRDA_50ms_Group04_CRC";
BA_ "CompuMethodName" SG_ 725 RHRDA_50ms_Group04_RC "RHRDA_50ms_Group04_RC";
BA_ "ISignalName" SG_ 725 RHRDA_50ms_Group04_RC "IRHRDA_50ms_Group04_RC";
BA_ "SysSignalName" SG_ 725 RHRDA_50ms_Group04_RC "RHRDA_50ms_Group04_RC";
BA_ "CompuMethodName" SG_ 725 RDOWWrnng "RDOWWrnng";
BA_ "ISignalName" SG_ 725 RDOWWrnng "IRDOWWrnng";
BA_ "LongName" SG_ 725 RDOWWrnng "Right Door Open Warning Warning";
BA_ "SysSignalName" SG_ 725 RDOWWrnng "RDOWWrnng";
BA_ "CompuMethodName" SG_ 725 LDOWWrnng "LDOWWrnng";
BA_ "ISignalName" SG_ 725 LDOWWrnng "ILDOWWrnng";
BA_ "LongName" SG_ 725 LDOWWrnng "Left Door Open Warning Warning";
BA_ "SysSignalName" SG_ 725 LDOWWrnng "LDOWWrnng";
BA_ "CompuMethodName" SG_ 725 RHRDA_50ms_Group04_Reserved1 "RHRDA_50ms_Group04_Reserved1";
BA_ "GenSigStartValue" SG_ 725 RHRDA_50ms_Group04_Reserved1 7;
BA_ "ISignalName" SG_ 725 RHRDA_50ms_Group04_Reserved1 "IRHRDA_50ms_Group04_Reserved1";
BA_ "SysSignalName" SG_ 725 RHRDA_50ms_Group04_Reserved1 "RHRDA_50ms_Group04_Reserved1";
BA_ "CompuMethodName" SG_ 725 RDASysSta "RDASysSta";
BA_ "GenSigStartValue" SG_ 725 RDASysSta 1;
BA_ "ISignalName" SG_ 725 RDASysSta "IRDASysSta";
BA_ "LongName" SG_ 725 RDASysSta "Rear Drive Assist System State";
BA_ "SysSignalName" SG_ 725 RDASysSta "RDASysSta";
BA_ "CompuMethodName" SG_ 725 RBSDAndLCAWrnng "RBSDAndLCAWrnng";
BA_ "ISignalName" SG_ 725 RBSDAndLCAWrnng "IRBSDAndLCAWrnng";
BA_ "LongName" SG_ 725 RBSDAndLCAWrnng "Right Blind Spot Detect And Lane Change Assist Warning";
BA_ "SysSignalName" SG_ 725 RBSDAndLCAWrnng "RBSDAndLCAWrnng";
BA_ "CompuMethodName" SG_ 725 LBSDAndLCAWrnng "LBSDAndLCAWrnng";
BA_ "ISignalName" SG_ 725 LBSDAndLCAWrnng "ILBSDAndLCAWrnng";
BA_ "LongName" SG_ 725 LBSDAndLCAWrnng "Left Blind Spot Detect And Lane Change Assist Warning";
BA_ "SysSignalName" SG_ 725 LBSDAndLCAWrnng "LBSDAndLCAWrnng";
BA_ "CompuMethodName" SG_ 725 DOWSelSts "DOWSelSts";
BA_ "ISignalName" SG_ 725 DOWSelSts "IDOWSelSts";
BA_ "LongName" SG_ 725 DOWSelSts "Door Open Warning Select Status";
BA_ "SysSignalName" SG_ 725 DOWSelSts "DOWSelSts";
BA_ "CompuMethodName" SG_ 725 RDASwSts "RDASwSts";
BA_ "ISignalName" SG_ 725 RDASwSts "IRDASwSts";
BA_ "LongName" SG_ 725 RDASwSts "Rear Drive Assist Switch Status";
BA_ "SysSignalName" SG_ 725 RDASwSts "RDASwSts";
BA_ "CompuMethodName" SG_ 725 LCASelSts "LCASelSts";
BA_ "ISignalName" SG_ 725 LCASelSts "ILCASelSts";
BA_ "LongName" SG_ 725 LCASelSts "Lane Change Assist Select Status";
BA_ "SysSignalName" SG_ 725 LCASelSts "LCASelSts";
BA_ "CompuMethodName" SG_ 725 RRCTAWrnng "RRCTAWrnng";
BA_ "ISignalName" SG_ 725 RRCTAWrnng "IRRCTAWrnng";
BA_ "LongName" SG_ 725 RRCTAWrnng "Rear Right Cross Traffic Alert Warning";
BA_ "SysSignalName" SG_ 725 RRCTAWrnng "RRCTAWrnng";
BA_ "CompuMethodName" SG_ 725 RCTSysSelSts "RCTSysSelSts";
BA_ "ISignalName" SG_ 725 RCTSysSelSts "IRCTSysSelSts";
BA_ "LongName" SG_ 725 RCTSysSelSts "Rear Cross Traffic System Select Status";
BA_ "SysSignalName" SG_ 725 RCTSysSelSts "RCTSysSelSts";
BA_ "CompuMethodName" SG_ 725 LRCTAWrnng "LRCTAWrnng";
BA_ "ISignalName" SG_ 725 LRCTAWrnng "ILRCTAWrnng";
BA_ "LongName" SG_ 725 LRCTAWrnng "Left Rear Cross Traffic Alert Warning";
BA_ "SysSignalName" SG_ 725 LRCTAWrnng "LRCTAWrnng";
BA_ "CompuMethodName" SG_ 725 RHRDA_50ms_Group04_Reserved2 "RHRDA_50ms_Group04_Reserved2";
BA_ "GenSigStartValue" SG_ 725 RHRDA_50ms_Group04_Reserved2 1;
BA_ "ISignalName" SG_ 725 RHRDA_50ms_Group04_Reserved2 "IRHRDA_50ms_Group04_Reserved2";
BA_ "SysSignalName" SG_ 725 RHRDA_50ms_Group04_Reserved2 "RHRDA_50ms_Group04_Reserved2";
BA_ "CompuMethodName" SG_ 725 RRRdrEmgcLineChngWrnng "RRRdrEmgcLineChngWrnng";
BA_ "ISignalName" SG_ 725 RRRdrEmgcLineChngWrnng "IRRRdrEmgcLineChngWrnng";
BA_ "LongName" SG_ 725 RRRdrEmgcLineChngWrnng "Right Rear Radar Emergency Line Change Warning";
BA_ "SysSignalName" SG_ 725 RRRdrEmgcLineChngWrnng "RRRdrEmgcLineChngWrnng";
BA_ "CompuMethodName" SG_ 725 RrCrnRdrCalSts "RrCrnRdrCalSts";
BA_ "ISignalName" SG_ 725 RrCrnRdrCalSts "IRrCrnRdrCalSts";
BA_ "LongName" SG_ 725 RrCrnRdrCalSts "Rear Corner Radar Calibration Status";
BA_ "SysSignalName" SG_ 725 RrCrnRdrCalSts "RrCrnRdrCalSts";
BA_ "CompuMethodName" SG_ 725 BSDSelSts "BSDSelSts";
BA_ "ISignalName" SG_ 725 BSDSelSts "IBSDSelSts";
BA_ "LongName" SG_ 725 BSDSelSts "Blind Spot Detect Select Status";
BA_ "SysSignalName" SG_ 725 BSDSelSts "BSDSelSts";
BA_ "CompuMethodName" SG_ 725 RHRDA_50ms_Group04_Reserved3 "RHRDA_50ms_Group04_Reserved3";
BA_ "GenSigStartValue" SG_ 725 RHRDA_50ms_Group04_Reserved3 63;
BA_ "ISignalName" SG_ 725 RHRDA_50ms_Group04_Reserved3 "IRHRDA_50ms_Group04_Reserved3";
BA_ "SysSignalName" SG_ 725 RHRDA_50ms_Group04_Reserved3 "RHRDA_50ms_Group04_Reserved3";
BA_ "CompuMethodName" SG_ 725 RLRdrEmgcLineChngWrnng "RLRdrEmgcLineChngWrnng";
BA_ "ISignalName" SG_ 725 RLRdrEmgcLineChngWrnng "IRLRdrEmgcLineChngWrnng";
BA_ "LongName" SG_ 725 RLRdrEmgcLineChngWrnng "Rear Left Radar Emergency Line Change Warning";
BA_ "SysSignalName" SG_ 725 RLRdrEmgcLineChngWrnng "RLRdrEmgcLineChngWrnng";
BA_ "CompuMethodName" SG_ 725 RHRDA_50ms_Group04_Reserved4 "RHRDA_50ms_Group04_Reserved4";
BA_ "GenSigStartValue" SG_ 725 RHRDA_50ms_Group04_Reserved4 255;
BA_ "ISignalName" SG_ 725 RHRDA_50ms_Group04_Reserved4 "IRHRDA_50ms_Group04_Reserved4";
BA_ "SysSignalName" SG_ 725 RHRDA_50ms_Group04_Reserved4 "RHRDA_50ms_Group04_Reserved4";
BA_ "CompuMethodName" SG_ 1228 RHRDA_NM_BSMtoRMS_BKPCANFD "RHRDA_NM_BSMtoRMS_BKPCANFD";
BA_ "ISignalName" SG_ 1228 RHRDA_NM_BSMtoRMS_BKPCANFD "IRHRDA_NM_BSMtoRMS_BKPCANFD";
BA_ "LongName" SG_ 1228 RHRDA_NM_BSMtoRMS_BKPCANFD "RHRDA_NM_BSMtoRMS_BKPCANFD";
BA_ "SysSignalName" SG_ 1228 RHRDA_NM_BSMtoRMS_BKPCANFD "RHRDA_NM_BSMtoRMS_BKPCANFD";
BA_ "CompuMethodName" SG_ 1228 RHRDA_NM_PBSMtoRMS_BKPCANFD "RHRDA_NM_PBSMtoRMS_BKPCANFD";
BA_ "ISignalName" SG_ 1228 RHRDA_NM_PBSMtoRMS_BKPCANFD "IRHRDA_NM_PBSMtoRMS_BKPCANFD";
BA_ "LongName" SG_ 1228 RHRDA_NM_PBSMtoRMS_BKPCANFD "RHRDA_NM_PBSMtoRMS_BKPCANFD";
BA_ "SysSignalName" SG_ 1228 RHRDA_NM_PBSMtoRMS_BKPCANFD "RHRDA_NM_PBSMtoRMS_BKPCANFD";
BA_ "CompuMethodName" SG_ 1228 RHRDA_NM_RMStoNOS_BKPCANFD "RHRDA_NM_RMStoNOS_BKPCANFD";
BA_ "ISignalName" SG_ 1228 RHRDA_NM_RMStoNOS_BKPCANFD "IRHRDA_NM_RMStoNOS_BKPCANFD";
BA_ "LongName" SG_ 1228 RHRDA_NM_RMStoNOS_BKPCANFD "RHRDA_NM_RMStoNOS_BKPCANFD";
BA_ "SysSignalName" SG_ 1228 RHRDA_NM_RMStoNOS_BKPCANFD "RHRDA_NM_RMStoNOS_BKPCANFD";
BA_ "CompuMethodName" SG_ 1228 RHRDA_NM_RSStoNOS_BKPCANFD "RHRDA_NM_RSStoNOS_BKPCANFD";
BA_ "ISignalName" SG_ 1228 RHRDA_NM_RSStoNOS_BKPCANFD "IRHRDA_NM_RSStoNOS_BKPCANFD";
BA_ "LongName" SG_ 1228 RHRDA_NM_RSStoNOS_BKPCANFD "RHRDA_NM_RSStoNOS_BKPCANFD";
BA_ "SysSignalName" SG_ 1228 RHRDA_NM_RSStoNOS_BKPCANFD "RHRDA_NM_RSStoNOS_BKPCANFD";
BA_ "CompuMethodName" SG_ 1228 RHRDA_NM_RSStoRMS_BKPCANFD "RHRDA_NM_RSStoRMS_BKPCANFD";
BA_ "ISignalName" SG_ 1228 RHRDA_NM_RSStoRMS_BKPCANFD "IRHRDA_NM_RSStoRMS_BKPCANFD";
BA_ "LongName" SG_ 1228 RHRDA_NM_RSStoRMS_BKPCANFD "RHRDA_NM_RSStoRMS_BKPCANFD";
BA_ "SysSignalName" SG_ 1228 RHRDA_NM_RSStoRMS_BKPCANFD "RHRDA_NM_RSStoRMS_BKPCANFD";
BA_ "CompuMethodName" SG_ 1228 RHRDA_NM_NOStoRMS_BKPCANFD "RHRDA_NM_NOStoRMS_BKPCANFD";
BA_ "ISignalName" SG_ 1228 RHRDA_NM_NOStoRMS_BKPCANFD "IRHRDA_NM_NOStoRMS_BKPCANFD";
BA_ "LongName" SG_ 1228 RHRDA_NM_NOStoRMS_BKPCANFD "RHRDA_NM_NOStoRMS_BKPCANFD";
BA_ "SysSignalName" SG_ 1228 RHRDA_NM_NOStoRMS_BKPCANFD "RHRDA_NM_NOStoRMS_BKPCANFD";
BA_ "CompuMethodName" SG_ 1228 RHRDA_NM_NOSSta_BKPCANFD "RHRDA_NM_NOSSta_BKPCANFD";
BA_ "ISignalName" SG_ 1228 RHRDA_NM_NOSSta_BKPCANFD "IRHRDA_NM_NOSSta_BKPCANFD";
BA_ "LongName" SG_ 1228 RHRDA_NM_NOSSta_BKPCANFD "RHRDA_NM_NOSSta_BKPCANFD";
BA_ "SysSignalName" SG_ 1228 RHRDA_NM_NOSSta_BKPCANFD "RHRDA_NM_NOSSta_BKPCANFD";
BA_ "CompuMethodName" SG_ 1228 RHRDA_NM_RMSSta_BKPCANFD "RHRDA_NM_RMSSta_BKPCANFD";
BA_ "ISignalName" SG_ 1228 RHRDA_NM_RMSSta_BKPCANFD "IRHRDA_NM_RMSSta_BKPCANFD";
BA_ "LongName" SG_ 1228 RHRDA_NM_RMSSta_BKPCANFD "RHRDA_NM_RMSSta_BKPCANFD";
BA_ "SysSignalName" SG_ 1228 RHRDA_NM_RMSSta_BKPCANFD "RHRDA_NM_RMSSta_BKPCANFD";
BA_ "CompuMethodName" SG_ 1228 RHRDA_NWI_BKPCANFD "RHRDA_NWI_BKPCANFD";
BA_ "ISignalName" SG_ 1228 RHRDA_NWI_BKPCANFD "IRHRDA_NWI_BKPCANFD";
BA_ "LongName" SG_ 1228 RHRDA_NWI_BKPCANFD "RHRDA BKPCANFD Network_Wakeup_Indication";
BA_ "SysSignalName" SG_ 1228 RHRDA_NWI_BKPCANFD "RHRDA_NWI_BKPCANFD";
BA_ "CompuMethodName" SG_ 1228 RHRDA_NOI_BKPCANFD "RHRDA_NOI_BKPCANFD";
BA_ "ISignalName" SG_ 1228 RHRDA_NOI_BKPCANFD "IRHRDA_NOI_BKPCANFD";
BA_ "LongName" SG_ 1228 RHRDA_NOI_BKPCANFD "RHRDA BKPCANFD Network Operation Indication";
BA_ "SysSignalName" SG_ 1228 RHRDA_NOI_BKPCANFD "RHRDA_NOI_BKPCANFD";
BA_ "CompuMethodName" SG_ 1228 RHRDA_NKI_BKPCANFD "RHRDA_NKI_BKPCANFD";
BA_ "ISignalName" SG_ 1228 RHRDA_NKI_BKPCANFD "IRHRDA_NKI_BKPCANFD";
BA_ "LongName" SG_ 1228 RHRDA_NKI_BKPCANFD "RHRDA BKPCANFD Network Keep Indication";
BA_ "SysSignalName" SG_ 1228 RHRDA_NKI_BKPCANFD "RHRDA_NKI_BKPCANFD";
BA_ "CompuMethodName" SG_ 936 FrtCamrHeatSts "FrtCamrHeatSts";
BA_ "ISignalName" SG_ 936 FrtCamrHeatSts "IFrtCamrHeatSts";
BA_ "LongName" SG_ 936 FrtCamrHeatSts "Front Camera Heat Status";
BA_ "SysSignalName" SG_ 936 FrtCamrHeatSts "FrtCamrHeatSts";
BA_ "CompuMethodName" SG_ 936 FrSsdLrngFailRrsn "FrSsdLrngFailRrsn";
BA_ "ISignalName" SG_ 936 FrSsdLrngFailRrsn "IFrSsdLrngFailRrsn";
BA_ "LongName" SG_ 936 FrSsdLrngFailRrsn "Front_Sunshade_Learning_Fail_Reason";
BA_ "SysSignalName" SG_ 936 FrSsdLrngFailRrsn "FrSsdLrngFailRrsn";
BA_ "CompuMethodName" SG_ 544 RHZCU_50ms_Group27_CRC "RHZCU_50ms_Group27_CRC";
BA_ "ISignalName" SG_ 544 RHZCU_50ms_Group27_CRC "IRHZCU_50ms_Group27_CRC";
BA_ "LongName" SG_ 544 RHZCU_50ms_Group27_CRC "RHZCU_50ms_Group27_CRC";
BA_ "SysSignalName" SG_ 544 RHZCU_50ms_Group27_CRC "RHZCU_50ms_Group27_CRC";
BA_ "CompuMethodName" SG_ 544 RHZCU_50ms_Group27_RC "RHZCU_50ms_Group27_RC";
BA_ "ISignalName" SG_ 544 RHZCU_50ms_Group27_RC "IRHZCU_50ms_Group27_RC";
BA_ "LongName" SG_ 544 RHZCU_50ms_Group27_RC "RHZCU_50ms_Group27_RC";
BA_ "SysSignalName" SG_ 544 RHZCU_50ms_Group27_RC "RHZCU_50ms_Group27_RC";
BA_ "CompuMethodName" SG_ 544 RHZCU_50ms_Group27_Reserved1 "RHZCU_50ms_Group27_Reserved1";
BA_ "GenSigStartValue" SG_ 544 RHZCU_50ms_Group27_Reserved1 15;
BA_ "ISignalName" SG_ 544 RHZCU_50ms_Group27_Reserved1 "IRHZCU_50ms_Group27_Reserved1";
BA_ "SysSignalName" SG_ 544 RHZCU_50ms_Group27_Reserved1 "RHZCU_50ms_Group27_Reserved1";
BA_ "CompuMethodName" SG_ 544 RHZCU_50ms_Group27_Reserved2 "RHZCU_50ms_Group27_Reserved2";
BA_ "GenSigStartValue" SG_ 544 RHZCU_50ms_Group27_Reserved2 1;
BA_ "ISignalName" SG_ 544 RHZCU_50ms_Group27_Reserved2 "IRHZCU_50ms_Group27_Reserved2";
BA_ "SysSignalName" SG_ 544 RHZCU_50ms_Group27_Reserved2 "RHZCU_50ms_Group27_Reserved2";
BA_ "CompuMethodName" SG_ 544 RHZCUeSw37Sts "RHZCUeSw37Sts";
BA_ "ISignalName" SG_ 544 RHZCUeSw37Sts "IRHZCUeSw37Sts";
BA_ "LongName" SG_ 544 RHZCUeSw37Sts "RHZCU eSwitch37 Status";
BA_ "SysSignalName" SG_ 544 RHZCUeSw37Sts "RHZCUeSw37Sts";
BA_ "CompuMethodName" SG_ 544 RHZCUeSw37DiagSts "RHZCUeSw37DiagSts";
BA_ "ISignalName" SG_ 544 RHZCUeSw37DiagSts "IRHZCUeSw37DiagSts";
BA_ "LongName" SG_ 544 RHZCUeSw37DiagSts "RHZCU eSwitch37 Diagnostic Status";
BA_ "SysSignalName" SG_ 544 RHZCUeSw37DiagSts "RHZCUeSw37DiagSts";
BA_ "CompuMethodName" SG_ 544 RHZCU_50ms_Group27_Reserved3 "RHZCU_50ms_Group27_Reserved3";
BA_ "GenSigStartValue" SG_ 544 RHZCU_50ms_Group27_Reserved3 1;
BA_ "ISignalName" SG_ 544 RHZCU_50ms_Group27_Reserved3 "IRHZCU_50ms_Group27_Reserved3";
BA_ "SysSignalName" SG_ 544 RHZCU_50ms_Group27_Reserved3 "RHZCU_50ms_Group27_Reserved3";
BA_ "CompuMethodName" SG_ 544 RHZCUeSw3Sts "RHZCUeSw3Sts";
BA_ "ISignalName" SG_ 544 RHZCUeSw3Sts "IRHZCUeSw3Sts";
BA_ "LongName" SG_ 544 RHZCUeSw3Sts "RHZCU eSwitch3 Status";
BA_ "SysSignalName" SG_ 544 RHZCUeSw3Sts "RHZCUeSw3Sts";
BA_ "CompuMethodName" SG_ 544 RHZCUeSw3DiagSts "RHZCUeSw3DiagSts";
BA_ "ISignalName" SG_ 544 RHZCUeSw3DiagSts "IRHZCUeSw3DiagSts";
BA_ "LongName" SG_ 544 RHZCUeSw3DiagSts "RHZCU eSwitch3 Diagnostic Status";
BA_ "SysSignalName" SG_ 544 RHZCUeSw3DiagSts "RHZCUeSw3DiagSts";
BA_ "CompuMethodName" SG_ 544 RHZCU_50ms_Group27_Reserved4 "RHZCU_50ms_Group27_Reserved4";
BA_ "GenSigStartValue" SG_ 544 RHZCU_50ms_Group27_Reserved4 1;
BA_ "ISignalName" SG_ 544 RHZCU_50ms_Group27_Reserved4 "IRHZCU_50ms_Group27_Reserved4";
BA_ "SysSignalName" SG_ 544 RHZCU_50ms_Group27_Reserved4 "RHZCU_50ms_Group27_Reserved4";
BA_ "CompuMethodName" SG_ 544 RHZCUeSw9Sts "RHZCUeSw9Sts";
BA_ "ISignalName" SG_ 544 RHZCUeSw9Sts "IRHZCUeSw9Sts";
BA_ "LongName" SG_ 544 RHZCUeSw9Sts "RHZCU eSwitch9 Status";
BA_ "SysSignalName" SG_ 544 RHZCUeSw9Sts "RHZCUeSw9Sts";
BA_ "CompuMethodName" SG_ 544 RHZCUeSw9DiagSts "RHZCUeSw9DiagSts";
BA_ "ISignalName" SG_ 544 RHZCUeSw9DiagSts "IRHZCUeSw9DiagSts";
BA_ "LongName" SG_ 544 RHZCUeSw9DiagSts "RHZCU eSwitch9 Diagnostic Status";
BA_ "SysSignalName" SG_ 544 RHZCUeSw9DiagSts "RHZCUeSw9DiagSts";
BA_ "CompuMethodName" SG_ 544 RHZCU_50ms_Group27_Reserved5 "RHZCU_50ms_Group27_Reserved5";
BA_ "GenSigStartValue" SG_ 544 RHZCU_50ms_Group27_Reserved5 1;
BA_ "ISignalName" SG_ 544 RHZCU_50ms_Group27_Reserved5 "IRHZCU_50ms_Group27_Reserved5";
BA_ "SysSignalName" SG_ 544 RHZCU_50ms_Group27_Reserved5 "RHZCU_50ms_Group27_Reserved5";
BA_ "CompuMethodName" SG_ 544 RHZCUeSw33Sts "RHZCUeSw33Sts";
BA_ "ISignalName" SG_ 544 RHZCUeSw33Sts "IRHZCUeSw33Sts";
BA_ "LongName" SG_ 544 RHZCUeSw33Sts "RHZCU eSwitch33 Status";
BA_ "SysSignalName" SG_ 544 RHZCUeSw33Sts "RHZCUeSw33Sts";
BA_ "CompuMethodName" SG_ 544 RHZCUeSw33DiagSts "RHZCUeSw33DiagSts";
BA_ "ISignalName" SG_ 544 RHZCUeSw33DiagSts "IRHZCUeSw33DiagSts";
BA_ "LongName" SG_ 544 RHZCUeSw33DiagSts "RHZCU eSwitch33 Diagnostic Status";
BA_ "SysSignalName" SG_ 544 RHZCUeSw33DiagSts "RHZCUeSw33DiagSts";
BA_ "CompuMethodName" SG_ 544 RHZCU_50ms_Group27_Reserved6 "RHZCU_50ms_Group27_Reserved6";
BA_ "GenSigStartValue" SG_ 544 RHZCU_50ms_Group27_Reserved6 1;
BA_ "ISignalName" SG_ 544 RHZCU_50ms_Group27_Reserved6 "IRHZCU_50ms_Group27_Reserved6";
BA_ "SysSignalName" SG_ 544 RHZCU_50ms_Group27_Reserved6 "RHZCU_50ms_Group27_Reserved6";
BA_ "CompuMethodName" SG_ 544 RHZCUeSw42Sts "RHZCUeSw42Sts";
BA_ "ISignalName" SG_ 544 RHZCUeSw42Sts "IRHZCUeSw42Sts";
BA_ "LongName" SG_ 544 RHZCUeSw42Sts "RHZCU eSwitch42 Status";
BA_ "SysSignalName" SG_ 544 RHZCUeSw42Sts "RHZCUeSw42Sts";
BA_ "CompuMethodName" SG_ 544 RHZCUeSw42DiagSts "RHZCUeSw42DiagSts";
BA_ "ISignalName" SG_ 544 RHZCUeSw42DiagSts "IRHZCUeSw42DiagSts";
BA_ "LongName" SG_ 544 RHZCUeSw42DiagSts "RHZCU eSwitch42 Diagnostic Status";
BA_ "SysSignalName" SG_ 544 RHZCUeSw42DiagSts "RHZCUeSw42DiagSts";
BA_ "CompuMethodName" SG_ 544 RHZCU_50ms_Group27_Reserved7 "RHZCU_50ms_Group27_Reserved7";
BA_ "GenSigStartValue" SG_ 544 RHZCU_50ms_Group27_Reserved7 1;
BA_ "ISignalName" SG_ 544 RHZCU_50ms_Group27_Reserved7 "IRHZCU_50ms_Group27_Reserved7";
BA_ "SysSignalName" SG_ 544 RHZCU_50ms_Group27_Reserved7 "RHZCU_50ms_Group27_Reserved7";
BA_ "CompuMethodName" SG_ 544 RHZCUeSw43Sts "RHZCUeSw43Sts";
BA_ "ISignalName" SG_ 544 RHZCUeSw43Sts "IRHZCUeSw43Sts";
BA_ "LongName" SG_ 544 RHZCUeSw43Sts "RHZCU eSwitch43 Status";
BA_ "SysSignalName" SG_ 544 RHZCUeSw43Sts "RHZCUeSw43Sts";
BA_ "CompuMethodName" SG_ 544 RHZCUeSw43DiagSts "RHZCUeSw43DiagSts";
BA_ "ISignalName" SG_ 544 RHZCUeSw43DiagSts "IRHZCUeSw43DiagSts";
BA_ "LongName" SG_ 544 RHZCUeSw43DiagSts "RHZCU eSwitch43 Diagnostic Status";
BA_ "SysSignalName" SG_ 544 RHZCUeSw43DiagSts "RHZCUeSw43DiagSts";
BA_ "CompuMethodName" SG_ 514 RDipdBeamLghtSts "RDipdBeamLghtSts";
BA_ "ISignalName" SG_ 514 RDipdBeamLghtSts "IRDipdBeamLghtSts";
BA_ "LongName" SG_ 514 RDipdBeamLghtSts "Right  Dipped BeamLight State";
BA_ "SysSignalName" SG_ 514 RDipdBeamLghtSts "RDipdBeamLghtSts";
BA_ "CompuMethodName" SG_ 514 RRSuperLckSts "RRSuperLckSts";
BA_ "ISignalName" SG_ 514 RRSuperLckSts "IRRSuperLckSts";
BA_ "LongName" SG_ 514 RRSuperLckSts "Rear Right SuperLock Status";
BA_ "SysSignalName" SG_ 514 RRSuperLckSts "RRSuperLckSts";
BA_ "CompuMethodName" SG_ 514 FRSuperLckSts "FRSuperLckSts";
BA_ "ISignalName" SG_ 514 FRSuperLckSts "IFRSuperLckSts";
BA_ "LongName" SG_ 514 FRSuperLckSts "Front Right SuperLock Status";
BA_ "SysSignalName" SG_ 514 FRSuperLckSts "FRSuperLckSts";
BA_ "CompuMethodName" SG_ 514 FRDSP_RLWinSwtSts "FRDSP_RLWinSwtSts";
BA_ "ISignalName" SG_ 514 FRDSP_RLWinSwtSts "IFRDSP_RLWinSwtSts";
BA_ "LongName" SG_ 514 FRDSP_RLWinSwtSts "Front Left Door Switch Package:Rear Left Window Switch Status";
BA_ "SysSignalName" SG_ 514 FRDSP_RLWinSwtSts "FRDSP_RLWinSwtSts";
BA_ "CompuMethodName" SG_ 514 FRDSP_FLWinSwtSts "FRDSP_FLWinSwtSts";
BA_ "ISignalName" SG_ 514 FRDSP_FLWinSwtSts "IFRDSP_FLWinSwtSts";
BA_ "LongName" SG_ 514 FRDSP_FLWinSwtSts "Front Left Door Switch Package:Front Right Window Switch Status";
BA_ "SysSignalName" SG_ 514 FRDSP_FLWinSwtSts "FRDSP_FLWinSwtSts";
BA_ "CompuMethodName" SG_ 514 FRDircnLghtSts "FRDircnLghtSts";
BA_ "ISignalName" SG_ 514 FRDircnLghtSts "IFRDircnLghtSts";
BA_ "LongName" SG_ 514 FRDircnLghtSts "Right_Front_Direction_Light_Status";
BA_ "SysSignalName" SG_ 514 FRDircnLghtSts "FRDircnLghtSts";
BA_ "CompuMethodName" SG_ 514 RMainBeamLghtSts "RMainBeamLghtSts";
BA_ "ISignalName" SG_ 514 RMainBeamLghtSts "IRMainBeamLghtSts";
BA_ "LongName" SG_ 514 RMainBeamLghtSts "Right_Main_beam_Light_Status";
BA_ "SysSignalName" SG_ 514 RMainBeamLghtSts "RMainBeamLghtSts";
BA_ "CompuMethodName" SG_ 514 FRDSP_RRWinSwtSts "FRDSP_RRWinSwtSts";
BA_ "ISignalName" SG_ 514 FRDSP_RRWinSwtSts "IFRDSP_RRWinSwtSts";
BA_ "LongName" SG_ 514 FRDSP_RRWinSwtSts "Front Left Door Switch Package:Rear Right Window Switch Status";
BA_ "SysSignalName" SG_ 514 FRDSP_RRWinSwtSts "FRDSP_RRWinSwtSts";
BA_ "CompuMethodName" SG_ 829 RHZCU_100ms_Group10_CRC "RHZCU_100ms_Group10_CRC";
BA_ "ISignalName" SG_ 829 RHZCU_100ms_Group10_CRC "IRHZCU_100ms_Group10_CRC";
BA_ "LongName" SG_ 829 RHZCU_100ms_Group10_CRC "RHZCU_100ms_Group10_CRC";
BA_ "SysSignalName" SG_ 829 RHZCU_100ms_Group10_CRC "RHZCU_100ms_Group10_CRC";
BA_ "CompuMethodName" SG_ 829 RHZCU_100ms_Group10_RC "RHZCU_100ms_Group10_RC";
BA_ "ISignalName" SG_ 829 RHZCU_100ms_Group10_RC "IRHZCU_100ms_Group10_RC";
BA_ "LongName" SG_ 829 RHZCU_100ms_Group10_RC "RHZCU_100ms_Group10_RC";
BA_ "SysSignalName" SG_ 829 RHZCU_100ms_Group10_RC "RHZCU_100ms_Group10_RC";
BA_ "CompuMethodName" SG_ 829 RHZCU_100ms_Group10_Reserved1 "RHZCU_100ms_Group10_Reserved1";
BA_ "GenSigStartValue" SG_ 829 RHZCU_100ms_Group10_Reserved1 15;
BA_ "ISignalName" SG_ 829 RHZCU_100ms_Group10_Reserved1 "IRHZCU_100ms_Group10_Reserved1";
BA_ "SysSignalName" SG_ 829 RHZCU_100ms_Group10_Reserved1 "RHZCU_100ms_Group10_Reserved1";
BA_ "CompuMethodName" SG_ 829 RHZCU_100ms_Group10_Reserved3 "RHZCU_100ms_Group10_Reserved3";
BA_ "GenSigStartValue" SG_ 829 RHZCU_100ms_Group10_Reserved3 1;
BA_ "ISignalName" SG_ 829 RHZCU_100ms_Group10_Reserved3 "IRHZCU_100ms_Group10_Reserved3";
BA_ "SysSignalName" SG_ 829 RHZCU_100ms_Group10_Reserved3 "RHZCU_100ms_Group10_Reserved3";
BA_ "CompuMethodName" SG_ 829 ACAmbtTemV "ACAmbtTemV";
BA_ "GenSigStartValue" SG_ 829 ACAmbtTemV 1;
BA_ "ISignalName" SG_ 829 ACAmbtTemV "IACAmbtTemV";
BA_ "LongName" SG_ 829 ACAmbtTemV "Air Conditioning Ambient Temperature Validity";
BA_ "SysSignalName" SG_ 829 ACAmbtTemV "ACAmbtTemV";
BA_ "CompuMethodName" SG_ 829 ACAmbtTemMsk "ACAmbtTemMsk";
BA_ "ISignalName" SG_ 829 ACAmbtTemMsk "IACAmbtTemMsk";
BA_ "LongName" SG_ 829 ACAmbtTemMsk "Air Conditioning Ambient Temperature Mask";
BA_ "SysSignalName" SG_ 829 ACAmbtTemMsk "ACAmbtTemMsk";
BA_ "CompuMethodName" SG_ 829 RHZCU_100ms_Group10_Reserved2 "RHZCU_100ms_Group10_Reserved2";
BA_ "GenSigStartValue" SG_ 829 RHZCU_100ms_Group10_Reserved2 31;
BA_ "ISignalName" SG_ 829 RHZCU_100ms_Group10_Reserved2 "IRHZCU_100ms_Group10_Reserved2";
BA_ "SysSignalName" SG_ 829 RHZCU_100ms_Group10_Reserved2 "RHZCU_100ms_Group10_Reserved2";
BA_ "CompuMethodName" SG_ 829 FRSeatHorzPos "FRSeatHorzPos";
BA_ "GenSigStartValue" SG_ 829 FRSeatHorzPos 255;
BA_ "ISignalName" SG_ 829 FRSeatHorzPos "IFRSeatHorzPos";
BA_ "LongName" SG_ 829 FRSeatHorzPos "FRONT RIGHT
Seat Horizontal Position";
BA_ "SysSignalName" SG_ 829 FRSeatHorzPos "FRSeatHorzPos";
BA_ "CompuMethodName" SG_ 829 ACAmbtTem "ACAmbtTem";
BA_ "ISignalName" SG_ 829 ACAmbtTem "IACAmbtTem";
BA_ "LongName" SG_ 829 ACAmbtTem "Air Conditioning Ambient Temperature";
BA_ "SysSignalName" SG_ 829 ACAmbtTem "ACAmbtTem";
BA_ "CompuMethodName" SG_ 829 RHZCU_100ms_Group10_Reserved4 "RHZCU_100ms_Group10_Reserved4";
BA_ "GenSigStartValue" SG_ 829 RHZCU_100ms_Group10_Reserved4 255;
BA_ "ISignalName" SG_ 829 RHZCU_100ms_Group10_Reserved4 "IRHZCU_100ms_Group10_Reserved4";
BA_ "SysSignalName" SG_ 829 RHZCU_100ms_Group10_Reserved4 "RHZCU_100ms_Group10_Reserved4";
BA_ "CompuMethodName" SG_ 829 ACComprActuPwr "ACComprActuPwr";
BA_ "ISignalName" SG_ 829 ACComprActuPwr "IACComprActuPwr";
BA_ "LongName" SG_ 829 ACComprActuPwr "Air Conditioning Compressor Actual Power";
BA_ "SysSignalName" SG_ 829 ACComprActuPwr "ACComprActuPwr";
BA_ "CompuMethodName" SG_ 829 FRSeatVertPos "FRSeatVertPos";
BA_ "GenSigStartValue" SG_ 829 FRSeatVertPos 255;
BA_ "ISignalName" SG_ 829 FRSeatVertPos "IFRSeatVertPos";
BA_ "LongName" SG_ 829 FRSeatVertPos "FRONT RIGHT
Seat Vert Position";
BA_ "SysSignalName" SG_ 829 FRSeatVertPos "FRSeatVertPos";
BA_ "CompuMethodName" SG_ 857 ACLAirMdDspCmd "ACLAirMdDspCmd";
BA_ "GenSigStartValue" SG_ 857 ACLAirMdDspCmd 7;
BA_ "ISignalName" SG_ 857 ACLAirMdDspCmd "IACLAirMdDspCmd";
BA_ "LongName" SG_ 857 ACLAirMdDspCmd "Air Conditioning Left Air Mode Display Command";
BA_ "SysSignalName" SG_ 857 ACLAirMdDspCmd "ACLAirMdDspCmd";
BA_ "CompuMethodName" SG_ 857 FrSsdMotVolErrSts "FrSsdMotVolErrSts";
BA_ "ISignalName" SG_ 857 FrSsdMotVolErrSts "IFrSsdMotVolErrSts";
BA_ "LongName" SG_ 857 FrSsdMotVolErrSts "Front_Sunshade_Motor_Voltage_Error_Status";
BA_ "SysSignalName" SG_ 857 FrSsdMotVolErrSts "FrSsdMotVolErrSts";
BA_ "CompuMethodName" SG_ 857 FrSsdMotThrmlProtnSts "FrSsdMotThrmlProtnSts";
BA_ "ISignalName" SG_ 857 FrSsdMotThrmlProtnSts "IFrSsdMotThrmlProtnSts";
BA_ "LongName" SG_ 857 FrSsdMotThrmlProtnSts "Front_Sunshade_Motor_Thermal_Protection_Status";
BA_ "SysSignalName" SG_ 857 FrSsdMotThrmlProtnSts "FrSsdMotThrmlProtnSts";
BA_ "CompuMethodName" SG_ 857 FrSsdMotSledSts "FrSsdMotSledSts";
BA_ "ISignalName" SG_ 857 FrSsdMotSledSts "IFrSsdMotSledSts";
BA_ "LongName" SG_ 857 FrSsdMotSledSts "Front_Sunshade_Motor_Stalled_Status";
BA_ "SysSignalName" SG_ 857 FrSsdMotSledSts "FrSsdMotSledSts";
BA_ "CompuMethodName" SG_ 857 FrSsdHallErrSts "FrSsdHallErrSts";
BA_ "ISignalName" SG_ 857 FrSsdHallErrSts "IFrSsdHallErrSts";
BA_ "LongName" SG_ 857 FrSsdHallErrSts "Front_Sunshade_Hall_Error_Status";
BA_ "SysSignalName" SG_ 857 FrSsdHallErrSts "FrSsdHallErrSts";
BA_ "CompuMethodName" SG_ 857 FrSsdInitSts "FrSsdInitSts";
BA_ "ISignalName" SG_ 857 FrSsdInitSts "IFrSsdInitSts";
BA_ "LongName" SG_ 857 FrSsdInitSts "Front_Sunshade_Initialization_Status";
BA_ "SysSignalName" SG_ 857 FrSsdInitSts "FrSsdInitSts";
BA_ "CompuMethodName" SG_ 857 ACFrtBlwrSpdDspCmd "ACFrtBlwrSpdDspCmd";
BA_ "GenSigStartValue" SG_ 857 ACFrtBlwrSpdDspCmd 15;
BA_ "ISignalName" SG_ 857 ACFrtBlwrSpdDspCmd "IACFrtBlwrSpdDspCmd";
BA_ "LongName" SG_ 857 ACFrtBlwrSpdDspCmd "Air Conditioning Front Blower Speed Display Command";
BA_ "SysSignalName" SG_ 857 ACFrtBlwrSpdDspCmd "ACFrtBlwrSpdDspCmd";
BA_ "CompuMethodName" SG_ 857 DfstOnDspCmd "DfstOnDspCmd";
BA_ "ISignalName" SG_ 857 DfstOnDspCmd "IDfstOnDspCmd";
BA_ "LongName" SG_ 857 DfstOnDspCmd "Defrost On Display Command";
BA_ "SysSignalName" SG_ 857 DfstOnDspCmd "DfstOnDspCmd";
BA_ "CompuMethodName" SG_ 857 ACOnOffDspCmd "ACOnOffDspCmd";
BA_ "ISignalName" SG_ 857 ACOnOffDspCmd "IACOnOffDspCmd";
BA_ "LongName" SG_ 857 ACOnOffDspCmd "Air Conditioning On Off Display Command";
BA_ "SysSignalName" SG_ 857 ACOnOffDspCmd "ACOnOffDspCmd";
BA_ "CompuMethodName" SG_ 857 ACAutoDspCmd "ACAutoDspCmd";
BA_ "ISignalName" SG_ 857 ACAutoDspCmd "IACAutoDspCmd";
BA_ "LongName" SG_ 857 ACAutoDspCmd "Air Conditioning Auto Display Command";
BA_ "SysSignalName" SG_ 857 ACAutoDspCmd "ACAutoDspCmd";
BA_ "CompuMethodName" SG_ 857 FrSsdMotRlyFltSts "FrSsdMotRlyFltSts";
BA_ "ISignalName" SG_ 857 FrSsdMotRlyFltSts "IFrSsdMotRlyFltSts";
BA_ "LongName" SG_ 857 FrSsdMotRlyFltSts "Front_Sunshade_Motor_Relay_Fault_Status";
BA_ "SysSignalName" SG_ 857 FrSsdMotRlyFltSts "FrSsdMotRlyFltSts";
BA_ "CompuMethodName" SG_ 857 FrSsdAntiPnchSts "FrSsdAntiPnchSts";
BA_ "ISignalName" SG_ 857 FrSsdAntiPnchSts "IFrSsdAntiPnchSts";
BA_ "LongName" SG_ 857 FrSsdAntiPnchSts "Front_Sunshade_Anti_Pinch_Status";
BA_ "SysSignalName" SG_ 857 FrSsdAntiPnchSts "FrSsdAntiPnchSts";
BA_ "CompuMethodName" SG_ 857 FrSsdLrngSts "FrSsdLrngSts";
BA_ "ISignalName" SG_ 857 FrSsdLrngSts "IFrSsdLrngSts";
BA_ "LongName" SG_ 857 FrSsdLrngSts "Front_Sunshade_Learning_Status";
BA_ "SysSignalName" SG_ 857 FrSsdLrngSts "FrSsdLrngSts";
BA_ "CompuMethodName" SG_ 857 FrSsdMovSts "FrSsdMovSts";
BA_ "ISignalName" SG_ 857 FrSsdMovSts "IFrSsdMovSts";
BA_ "LongName" SG_ 857 FrSsdMovSts "Front_Sunshade_Moving_Status";
BA_ "SysSignalName" SG_ 857 FrSsdMovSts "FrSsdMovSts";
BA_ "CompuMethodName" SG_ 943 FRDoorOpenSts "FRDoorOpenSts";
BA_ "ISignalName" SG_ 943 FRDoorOpenSts "IFRDoorOpenSts";
BA_ "LongName" SG_ 943 FRDoorOpenSts "Front Right Door Open Status";
BA_ "SysSignalName" SG_ 943 FRDoorOpenSts "FRDoorOpenSts";
BA_ "CompuMethodName" SG_ 943 RRWinShrtDwnSucd "RRWinShrtDwnSucd";
BA_ "ISignalName" SG_ 943 RRWinShrtDwnSucd "IRRWinShrtDwnSucd";
BA_ "LongName" SG_ 943 RRWinShrtDwnSucd "Rear Right Window short down successed";
BA_ "SysSignalName" SG_ 943 RRWinShrtDwnSucd "RRWinShrtDwnSucd";
BA_ "CompuMethodName" SG_ 943 ROtsdMirFoldSts "ROtsdMirFoldSts";
BA_ "ISignalName" SG_ 943 ROtsdMirFoldSts "IROtsdMirFoldSts";
BA_ "LongName" SG_ 943 ROtsdMirFoldSts "Right_Outside_Mirror_Fold_Status";
BA_ "SysSignalName" SG_ 943 ROtsdMirFoldSts "ROtsdMirFoldSts";
BA_ "CompuMethodName" SG_ 943 RRWinMotSts "RRWinMotSts";
BA_ "ISignalName" SG_ 943 RRWinMotSts "IRRWinMotSts";
BA_ "LongName" SG_ 943 RRWinMotSts "Rear Right Window Motor Status";
BA_ "SysSignalName" SG_ 943 RRWinMotSts "RRWinMotSts";
BA_ "CompuMethodName" SG_ 943 FRWinShrtDwnSucd "FRWinShrtDwnSucd";
BA_ "ISignalName" SG_ 943 FRWinShrtDwnSucd "IFRWinShrtDwnSucd";
BA_ "LongName" SG_ 943 FRWinShrtDwnSucd "Front Right Window short down successed";
BA_ "SysSignalName" SG_ 943 FRWinShrtDwnSucd "FRWinShrtDwnSucd";
BA_ "CompuMethodName" SG_ 943 RRWinLclSwtFlt "RRWinLclSwtFlt";
BA_ "ISignalName" SG_ 943 RRWinLclSwtFlt "IRRWinLclSwtFlt";
BA_ "LongName" SG_ 943 RRWinLclSwtFlt "Rear Right Window Local Switch Fault";
BA_ "SysSignalName" SG_ 943 RRWinLclSwtFlt "RRWinLclSwtFlt";
BA_ "CompuMethodName" SG_ 943 RRWinLclSwtSts "RRWinLclSwtSts";
BA_ "ISignalName" SG_ 943 RRWinLclSwtSts "IRRWinLclSwtSts";
BA_ "LongName" SG_ 943 RRWinLclSwtSts "Rear Right Window Local Switch Status";
BA_ "SysSignalName" SG_ 943 RRWinLclSwtSts "RRWinLclSwtSts";
BA_ "CompuMethodName" SG_ 943 RRWinIninSts "RRWinIninSts";
BA_ "ISignalName" SG_ 943 RRWinIninSts "IRRWinIninSts";
BA_ "LongName" SG_ 943 RRWinIninSts "Rear Right Window Initialized status";
BA_ "SysSignalName" SG_ 943 RRWinIninSts "RRWinIninSts";
BA_ "CompuMethodName" SG_ 943 FRWinIninSts "FRWinIninSts";
BA_ "ISignalName" SG_ 943 FRWinIninSts "IFRWinIninSts";
BA_ "LongName" SG_ 943 FRWinIninSts "Front Right Window Initialized status";
BA_ "SysSignalName" SG_ 943 FRWinIninSts "FRWinIninSts";
BA_ "CompuMethodName" SG_ 943 RRWinMotFlt "RRWinMotFlt";
BA_ "ISignalName" SG_ 943 RRWinMotFlt "IRRWinMotFlt";
BA_ "LongName" SG_ 943 RRWinMotFlt "Rear Right Window Motor Fault";
BA_ "SysSignalName" SG_ 943 RRWinMotFlt "RRWinMotFlt";
BA_ "CompuMethodName" SG_ 649 RHZCU_50ms_Group01_CRC "RHZCU_50ms_Group01_CRC";
BA_ "ISignalName" SG_ 649 RHZCU_50ms_Group01_CRC "IRHZCU_50ms_Group01_CRC";
BA_ "LongName" SG_ 649 RHZCU_50ms_Group01_CRC "RHZCU_50ms_Group01_CRC";
BA_ "SysSignalName" SG_ 649 RHZCU_50ms_Group01_CRC "RHZCU_50ms_Group01_CRC";
BA_ "CompuMethodName" SG_ 649 RHZCU_50ms_Group01_RC "RHZCU_50ms_Group01_RC";
BA_ "ISignalName" SG_ 649 RHZCU_50ms_Group01_RC "IRHZCU_50ms_Group01_RC";
BA_ "LongName" SG_ 649 RHZCU_50ms_Group01_RC "RHZCU_50ms_Group01_RC";
BA_ "SysSignalName" SG_ 649 RHZCU_50ms_Group01_RC "RHZCU_50ms_Group01_RC";
BA_ "CompuMethodName" SG_ 649 RRDoorOpenSts "RRDoorOpenSts";
BA_ "ISignalName" SG_ 649 RRDoorOpenSts "IRRDoorOpenSts";
BA_ "LongName" SG_ 649 RRDoorOpenSts "Rear Right Door Open Status";
BA_ "SysSignalName" SG_ 649 RRDoorOpenSts "RRDoorOpenSts";
BA_ "CompuMethodName" SG_ 649 RHZCU_50ms_Group01_Reserved1 "RHZCU_50ms_Group01_Reserved1";
BA_ "GenSigStartValue" SG_ 649 RHZCU_50ms_Group01_Reserved1 3;
BA_ "ISignalName" SG_ 649 RHZCU_50ms_Group01_Reserved1 "IRHZCU_50ms_Group01_Reserved1";
BA_ "SysSignalName" SG_ 649 RHZCU_50ms_Group01_Reserved1 "RHZCU_50ms_Group01_Reserved1";
BA_ "CompuMethodName" SG_ 649 RHZCUeSw41DiagSts "RHZCUeSw41DiagSts";
BA_ "ISignalName" SG_ 649 RHZCUeSw41DiagSts "IRHZCUeSw41DiagSts";
BA_ "LongName" SG_ 649 RHZCUeSw41DiagSts "RHZCU eSwitch41 Diagnostic Status";
BA_ "SysSignalName" SG_ 649 RHZCUeSw41DiagSts "RHZCUeSw41DiagSts";
BA_ "CompuMethodName" SG_ 649 RHZCU_50ms_Group01_Reserved2 "RHZCU_50ms_Group01_Reserved2";
BA_ "GenSigStartValue" SG_ 649 RHZCU_50ms_Group01_Reserved2 15;
BA_ "ISignalName" SG_ 649 RHZCU_50ms_Group01_Reserved2 "IRHZCU_50ms_Group01_Reserved2";
BA_ "SysSignalName" SG_ 649 RHZCU_50ms_Group01_Reserved2 "RHZCU_50ms_Group01_Reserved2";
BA_ "CompuMethodName" SG_ 649 RHZCU_50ms_Group01_Reserved3 "RHZCU_50ms_Group01_Reserved3";
BA_ "GenSigStartValue" SG_ 649 RHZCU_50ms_Group01_Reserved3 31;
BA_ "ISignalName" SG_ 649 RHZCU_50ms_Group01_Reserved3 "IRHZCU_50ms_Group01_Reserved3";
BA_ "SysSignalName" SG_ 649 RHZCU_50ms_Group01_Reserved3 "RHZCU_50ms_Group01_Reserved3";
BA_ "CompuMethodName" SG_ 649 RHZCUeSw41Sts "RHZCUeSw41Sts";
BA_ "ISignalName" SG_ 649 RHZCUeSw41Sts "IRHZCUeSw41Sts";
BA_ "LongName" SG_ 649 RHZCUeSw41Sts "RHZCU eSwitch41 Status";
BA_ "SysSignalName" SG_ 649 RHZCUeSw41Sts "RHZCUeSw41Sts";
BA_ "CompuMethodName" SG_ 649 RHZCU_50ms_Group01_Reserved4 "RHZCU_50ms_Group01_Reserved4";
BA_ "GenSigStartValue" SG_ 649 RHZCU_50ms_Group01_Reserved4 255;
BA_ "ISignalName" SG_ 649 RHZCU_50ms_Group01_Reserved4 "IRHZCU_50ms_Group01_Reserved4";
BA_ "SysSignalName" SG_ 649 RHZCU_50ms_Group01_Reserved4 "RHZCU_50ms_Group01_Reserved4";
BA_ "CompuMethodName" SG_ 649 RHZCU_50ms_Group01_Reserved5 "RHZCU_50ms_Group01_Reserved5";
BA_ "GenSigStartValue" SG_ 649 RHZCU_50ms_Group01_Reserved5 255;
BA_ "ISignalName" SG_ 649 RHZCU_50ms_Group01_Reserved5 "IRHZCU_50ms_Group01_Reserved5";
BA_ "SysSignalName" SG_ 649 RHZCU_50ms_Group01_Reserved5 "RHZCU_50ms_Group01_Reserved5";
BA_ "CompuMethodName" SG_ 649 RHZCU_50ms_Group01_Reserved6 "RHZCU_50ms_Group01_Reserved6";
BA_ "GenSigStartValue" SG_ 649 RHZCU_50ms_Group01_Reserved6 255;
BA_ "ISignalName" SG_ 649 RHZCU_50ms_Group01_Reserved6 "IRHZCU_50ms_Group01_Reserved6";
BA_ "SysSignalName" SG_ 649 RHZCU_50ms_Group01_Reserved6 "RHZCU_50ms_Group01_Reserved6";
BA_ "CompuMethodName" SG_ 649 RHZCU_50ms_Group01_Reserved7 "RHZCU_50ms_Group01_Reserved7";
BA_ "GenSigStartValue" SG_ 649 RHZCU_50ms_Group01_Reserved7 255;
BA_ "ISignalName" SG_ 649 RHZCU_50ms_Group01_Reserved7 "IRHZCU_50ms_Group01_Reserved7";
BA_ "SysSignalName" SG_ 649 RHZCU_50ms_Group01_Reserved7 "RHZCU_50ms_Group01_Reserved7";
BA_ "CompuMethodName" SG_ 940 RHZCUeSw14Sts "RHZCUeSw14Sts";
BA_ "ISignalName" SG_ 940 RHZCUeSw14Sts "IRHZCUeSw14Sts";
BA_ "LongName" SG_ 940 RHZCUeSw14Sts "RHZCU eSwitch14 Status";
BA_ "SysSignalName" SG_ 940 RHZCUeSw14Sts "RHZCUeSw14Sts";
BA_ "CompuMethodName" SG_ 940 RHZCUeSw14DiagSts "RHZCUeSw14DiagSts";
BA_ "ISignalName" SG_ 940 RHZCUeSw14DiagSts "IRHZCUeSw14DiagSts";
BA_ "LongName" SG_ 940 RHZCUeSw14DiagSts "RHZCU eSwitch14 Diagnostic Status";
BA_ "SysSignalName" SG_ 940 RHZCUeSw14DiagSts "RHZCUeSw14DiagSts";
BA_ "CompuMethodName" SG_ 940 RHZCUeSw31Sts "RHZCUeSw31Sts";
BA_ "ISignalName" SG_ 940 RHZCUeSw31Sts "IRHZCUeSw31Sts";
BA_ "LongName" SG_ 940 RHZCUeSw31Sts "RHZCU eSwitch31 Status";
BA_ "SysSignalName" SG_ 940 RHZCUeSw31Sts "RHZCUeSw31Sts";
BA_ "CompuMethodName" SG_ 940 RHZCUeSw31DiagSts "RHZCUeSw31DiagSts";
BA_ "ISignalName" SG_ 940 RHZCUeSw31DiagSts "IRHZCUeSw31DiagSts";
BA_ "LongName" SG_ 940 RHZCUeSw31DiagSts "RHZCU eSwitch31 Diagnostic Status";
BA_ "SysSignalName" SG_ 940 RHZCUeSw31DiagSts "RHZCUeSw31DiagSts";
BA_ "CompuMethodName" SG_ 940 RHZCUIgnSts "RHZCUIgnSts";
BA_ "ISignalName" SG_ 940 RHZCUIgnSts "IRHZCUIgnSts";
BA_ "LongName" SG_ 940 RHZCUIgnSts "RHZCU Ignition Status";
BA_ "SysSignalName" SG_ 940 RHZCUIgnSts "RHZCUIgnSts";
BA_ "CompuMethodName" SG_ 940 RHZCUIgnDiagSts "RHZCUIgnDiagSts";
BA_ "ISignalName" SG_ 940 RHZCUIgnDiagSts "IRHZCUIgnDiagSts";
BA_ "LongName" SG_ 940 RHZCUIgnDiagSts "RHZCU Ignition Diagnostic Status";
BA_ "SysSignalName" SG_ 940 RHZCUIgnDiagSts "RHZCUIgnDiagSts";
BA_ "CompuMethodName" SG_ 940 RHZCUeFs3Sts "RHZCUeFs3Sts";
BA_ "ISignalName" SG_ 940 RHZCUeFs3Sts "IRHZCUeFs3Sts";
BA_ "LongName" SG_ 940 RHZCUeFs3Sts "RHZCU eFuse3 Status";
BA_ "SysSignalName" SG_ 940 RHZCUeFs3Sts "RHZCUeFs3Sts";
BA_ "CompuMethodName" SG_ 940 RHZCUeFs3DiagSts "RHZCUeFs3DiagSts";
BA_ "ISignalName" SG_ 940 RHZCUeFs3DiagSts "IRHZCUeFs3DiagSts";
BA_ "LongName" SG_ 940 RHZCUeFs3DiagSts "RHZCU eFuse3 Diagnostic Status";
BA_ "SysSignalName" SG_ 940 RHZCUeFs3DiagSts "RHZCUeFs3DiagSts";
BA_ "CompuMethodName" SG_ 940 RHZCUeFs2Sts "RHZCUeFs2Sts";
BA_ "ISignalName" SG_ 940 RHZCUeFs2Sts "IRHZCUeFs2Sts";
BA_ "LongName" SG_ 940 RHZCUeFs2Sts "RHZCU eFuse2 Status";
BA_ "SysSignalName" SG_ 940 RHZCUeFs2Sts "RHZCUeFs2Sts";
BA_ "CompuMethodName" SG_ 940 RHZCUeFs2DiagSts "RHZCUeFs2DiagSts";
BA_ "ISignalName" SG_ 940 RHZCUeFs2DiagSts "IRHZCUeFs2DiagSts";
BA_ "LongName" SG_ 940 RHZCUeFs2DiagSts "RHZCU eFuse2 Diagnostic Status";
BA_ "SysSignalName" SG_ 940 RHZCUeFs2DiagSts "RHZCUeFs2DiagSts";
BA_ "CompuMethodName" SG_ 940 RHZCUeFs1Sts "RHZCUeFs1Sts";
BA_ "ISignalName" SG_ 940 RHZCUeFs1Sts "IRHZCUeFs1Sts";
BA_ "LongName" SG_ 940 RHZCUeFs1Sts "RHZCU eFuse1 Status";
BA_ "SysSignalName" SG_ 940 RHZCUeFs1Sts "RHZCUeFs1Sts";
BA_ "CompuMethodName" SG_ 940 RHZCUeFs1DiagSts "RHZCUeFs1DiagSts";
BA_ "ISignalName" SG_ 940 RHZCUeFs1DiagSts "IRHZCUeFs1DiagSts";
BA_ "LongName" SG_ 940 RHZCUeFs1DiagSts "RHZCU eFuse1 Diagnostic Status";
BA_ "SysSignalName" SG_ 940 RHZCUeFs1DiagSts "RHZCUeFs1DiagSts";
BA_ "CompuMethodName" SG_ 940 RHZCUeSw10Sts "RHZCUeSw10Sts";
BA_ "ISignalName" SG_ 940 RHZCUeSw10Sts "IRHZCUeSw10Sts";
BA_ "LongName" SG_ 940 RHZCUeSw10Sts "RHZCU eSwitch10 Status";
BA_ "SysSignalName" SG_ 940 RHZCUeSw10Sts "RHZCUeSw10Sts";
BA_ "CompuMethodName" SG_ 940 RHZCUeSw10DiagSts "RHZCUeSw10DiagSts";
BA_ "ISignalName" SG_ 940 RHZCUeSw10DiagSts "IRHZCUeSw10DiagSts";
BA_ "LongName" SG_ 940 RHZCUeSw10DiagSts "RHZCU eSwitch10 Diagnostic Status";
BA_ "SysSignalName" SG_ 940 RHZCUeSw10DiagSts "RHZCUeSw10DiagSts";
BA_ "CompuMethodName" SG_ 940 RHZCUeSw34Sts "RHZCUeSw34Sts";
BA_ "ISignalName" SG_ 940 RHZCUeSw34Sts "IRHZCUeSw34Sts";
BA_ "LongName" SG_ 940 RHZCUeSw34Sts "RHZCU eSwitch34 Status";
BA_ "SysSignalName" SG_ 940 RHZCUeSw34Sts "RHZCUeSw34Sts";
BA_ "CompuMethodName" SG_ 940 RHZCUeSw34DiagSts "RHZCUeSw34DiagSts";
BA_ "ISignalName" SG_ 940 RHZCUeSw34DiagSts "IRHZCUeSw34DiagSts";
BA_ "LongName" SG_ 940 RHZCUeSw34DiagSts "RHZCU eSwitch34 Diagnostic Status";
BA_ "SysSignalName" SG_ 940 RHZCUeSw34DiagSts "RHZCUeSw34DiagSts";
BA_ "CompuMethodName" SG_ 564 RZCU_50ms_Group37_CRC "RZCU_50ms_Group37_CRC";
BA_ "ISignalName" SG_ 564 RZCU_50ms_Group37_CRC "IRZCU_50ms_Group37_CRC";
BA_ "LongName" SG_ 564 RZCU_50ms_Group37_CRC "RZCU_50ms_Group37_CRC";
BA_ "SysSignalName" SG_ 564 RZCU_50ms_Group37_CRC "RZCU_50ms_Group37_CRC";
BA_ "CompuMethodName" SG_ 564 RZCU_50ms_Group37_RC "RZCU_50ms_Group37_RC";
BA_ "ISignalName" SG_ 564 RZCU_50ms_Group37_RC "IRZCU_50ms_Group37_RC";
BA_ "LongName" SG_ 564 RZCU_50ms_Group37_RC "RZCU_50ms_Group37_RC";
BA_ "SysSignalName" SG_ 564 RZCU_50ms_Group37_RC "RZCU_50ms_Group37_RC";
BA_ "CompuMethodName" SG_ 564 RZCU_50ms_Group37_Reserved15 "RZCU_50ms_Group37_Reserved15";
BA_ "GenSigStartValue" SG_ 564 RZCU_50ms_Group37_Reserved15 15;
BA_ "ISignalName" SG_ 564 RZCU_50ms_Group37_Reserved15 "IRZCU_50ms_Group37_Reserved15";
BA_ "SysSignalName" SG_ 564 RZCU_50ms_Group37_Reserved15 "RZCU_50ms_Group37_Reserved15";
BA_ "CompuMethodName" SG_ 564 RZCU_50ms_Group37_Reserved23 "RZCU_50ms_Group37_Reserved23";
BA_ "GenSigStartValue" SG_ 564 RZCU_50ms_Group37_Reserved23 255;
BA_ "ISignalName" SG_ 564 RZCU_50ms_Group37_Reserved23 "IRZCU_50ms_Group37_Reserved23";
BA_ "SysSignalName" SG_ 564 RZCU_50ms_Group37_Reserved23 "RZCU_50ms_Group37_Reserved23";
BA_ "CompuMethodName" SG_ 564 ChrgrFlapLtchCtrl "ChrgrFlapLtchCtrl";
BA_ "ISignalName" SG_ 564 ChrgrFlapLtchCtrl "IChrgrFlapLtchCtrl";
BA_ "LongName" SG_ 564 ChrgrFlapLtchCtrl "Charger Flap Latch Control";
BA_ "SysSignalName" SG_ 564 ChrgrFlapLtchCtrl "ChrgrFlapLtchCtrl";
BA_ "CompuMethodName" SG_ 564 RLDircnLghtSts "RLDircnLghtSts";
BA_ "ISignalName" SG_ 564 RLDircnLghtSts "IRLDircnLghtSts";
BA_ "LongName" SG_ 564 RLDircnLghtSts "Rear Left_Direction_Light_Status";
BA_ "SysSignalName" SG_ 564 RLDircnLghtSts "RLDircnLghtSts";
BA_ "CompuMethodName" SG_ 564 RZCU_50ms_Group37_Reserved31 "RZCU_50ms_Group37_Reserved31";
BA_ "GenSigStartValue" SG_ 564 RZCU_50ms_Group37_Reserved31 31;
BA_ "ISignalName" SG_ 564 RZCU_50ms_Group37_Reserved31 "IRZCU_50ms_Group37_Reserved31";
BA_ "SysSignalName" SG_ 564 RZCU_50ms_Group37_Reserved31 "RZCU_50ms_Group37_Reserved31";
BA_ "CompuMethodName" SG_ 564 RZCU_50ms_Group37_Reserved34 "RZCU_50ms_Group37_Reserved34";
BA_ "GenSigStartValue" SG_ 564 RZCU_50ms_Group37_Reserved34 31;
BA_ "ISignalName" SG_ 564 RZCU_50ms_Group37_Reserved34 "IRZCU_50ms_Group37_Reserved34";
BA_ "SysSignalName" SG_ 564 RZCU_50ms_Group37_Reserved34 "RZCU_50ms_Group37_Reserved34";
BA_ "CompuMethodName" SG_ 564 RRDircnLghtSts "RRDircnLghtSts";
BA_ "ISignalName" SG_ 564 RRDircnLghtSts "IRRDircnLghtSts";
BA_ "LongName" SG_ 564 RRDircnLghtSts "Rear_Right_Direction_Light_Status";
BA_ "SysSignalName" SG_ 564 RRDircnLghtSts "RRDircnLghtSts";
BA_ "CompuMethodName" SG_ 564 RZCU_50ms_Group37_Reserved36 "RZCU_50ms_Group37_Reserved36";
BA_ "GenSigStartValue" SG_ 564 RZCU_50ms_Group37_Reserved36 1;
BA_ "ISignalName" SG_ 564 RZCU_50ms_Group37_Reserved36 "IRZCU_50ms_Group37_Reserved36";
BA_ "SysSignalName" SG_ 564 RZCU_50ms_Group37_Reserved36 "RZCU_50ms_Group37_Reserved36";
BA_ "CompuMethodName" SG_ 564 RRDircnLghtFltsts "RRDircnLghtFltsts";
BA_ "ISignalName" SG_ 564 RRDircnLghtFltsts "IRRDircnLghtFltsts";
BA_ "LongName" SG_ 564 RRDircnLghtFltsts "Rear_Right_Direction_Light_Fault_Status";
BA_ "SysSignalName" SG_ 564 RRDircnLghtFltsts "RRDircnLghtFltsts";
BA_ "CompuMethodName" SG_ 564 RZCU_50ms_Group37_Reserved38 "RZCU_50ms_Group37_Reserved38";
BA_ "GenSigStartValue" SG_ 564 RZCU_50ms_Group37_Reserved38 1;
BA_ "ISignalName" SG_ 564 RZCU_50ms_Group37_Reserved38 "IRZCU_50ms_Group37_Reserved38";
BA_ "SysSignalName" SG_ 564 RZCU_50ms_Group37_Reserved38 "RZCU_50ms_Group37_Reserved38";
BA_ "CompuMethodName" SG_ 564 RLDircnLghtFltsts "RLDircnLghtFltsts";
BA_ "ISignalName" SG_ 564 RLDircnLghtFltsts "IRLDircnLghtFltsts";
BA_ "LongName" SG_ 564 RLDircnLghtFltsts "Rear Left_Direction_Light_Fault_Status";
BA_ "SysSignalName" SG_ 564 RLDircnLghtFltsts "RLDircnLghtFltsts";
BA_ "CompuMethodName" SG_ 564 RRDircnLghtFltsts_HW "RRDircnLghtFltsts_HW";
BA_ "ISignalName" SG_ 564 RRDircnLghtFltsts_HW "IRRDircnLghtFltsts_HW";
BA_ "LongName" SG_ 564 RRDircnLghtFltsts_HW "Right_Rear_Direction_Light_Fault_Status_HardWired";
BA_ "SysSignalName" SG_ 564 RRDircnLghtFltsts_HW "RRDircnLghtFltsts_HW";
BA_ "CompuMethodName" SG_ 564 RLDircnLghtFltsts_HW "RLDircnLghtFltsts_HW";
BA_ "ISignalName" SG_ 564 RLDircnLghtFltsts_HW "IRLDircnLghtFltsts_HW";
BA_ "LongName" SG_ 564 RLDircnLghtFltsts_HW "Left_Rear_Direction_Light_Fault_Status_HardWired";
BA_ "SysSignalName" SG_ 564 RLDircnLghtFltsts_HW "RLDircnLghtFltsts_HW";
BA_ "CompuMethodName" SG_ 564 RearFogLghtFltsts "RearFogLghtFltsts";
BA_ "ISignalName" SG_ 564 RearFogLghtFltsts "IRearFogLghtFltsts";
BA_ "LongName" SG_ 564 RearFogLghtFltsts "Rear_Fog_Light_Fault_Status";
BA_ "SysSignalName" SG_ 564 RearFogLghtFltsts "RearFogLghtFltsts";
BA_ "CompuMethodName" SG_ 564 RearFogLghtSts "RearFogLghtSts";
BA_ "ISignalName" SG_ 564 RearFogLghtSts "IRearFogLghtSts";
BA_ "LongName" SG_ 564 RearFogLghtSts "Rear_Fog_Light_Status";
BA_ "SysSignalName" SG_ 564 RearFogLghtSts "RearFogLghtSts";
BA_ "CompuMethodName" SG_ 564 RevsLghtFltSts "RevsLghtFltSts";
BA_ "ISignalName" SG_ 564 RevsLghtFltSts "IRevsLghtFltSts";
BA_ "LongName" SG_ 564 RevsLghtFltSts "Reverse_Light_Fault_Status";
BA_ "SysSignalName" SG_ 564 RevsLghtFltSts "RevsLghtFltSts";
BA_ "CompuMethodName" SG_ 564 BrkLghtFltSts_HW "BrkLghtFltSts_HW";
BA_ "ISignalName" SG_ 564 BrkLghtFltSts_HW "IBrkLghtFltSts_HW";
BA_ "LongName" SG_ 564 BrkLghtFltSts_HW "Brake_Light_Fault_Status_HardWired";
BA_ "SysSignalName" SG_ 564 BrkLghtFltSts_HW "BrkLghtFltSts_HW";
BA_ "CompuMethodName" SG_ 564 PwrLftgtClsSwtActv "PwrLftgtClsSwtActv";
BA_ "ISignalName" SG_ 564 PwrLftgtClsSwtActv "IPwrLftgtClsSwtActv";
BA_ "LongName" SG_ 564 PwrLftgtClsSwtActv "Power Liftgate Close Switch Active";
BA_ "SysSignalName" SG_ 564 PwrLftgtClsSwtActv "PwrLftgtClsSwtActv";
BA_ "CompuMethodName" SG_ 564 BrkLghtSts_HW "BrkLghtSts_HW";
BA_ "ISignalName" SG_ 564 BrkLghtSts_HW "IBrkLghtSts_HW";
BA_ "LongName" SG_ 564 BrkLghtSts_HW "Brake Light Status";
BA_ "SysSignalName" SG_ 564 BrkLghtSts_HW "BrkLghtSts_HW";
BA_ "CompuMethodName" SG_ 564 RLDircnLghtSts_HW "RLDircnLghtSts_HW";
BA_ "ISignalName" SG_ 564 RLDircnLghtSts_HW "IRLDircnLghtSts_HW";
BA_ "LongName" SG_ 564 RLDircnLghtSts_HW "Left Rear Direction Light Status";
BA_ "SysSignalName" SG_ 564 RLDircnLghtSts_HW "RLDircnLghtSts_HW";
BA_ "CompuMethodName" SG_ 564 RRDircnLghtSts_HW "RRDircnLghtSts_HW";
BA_ "ISignalName" SG_ 564 RRDircnLghtSts_HW "IRRDircnLghtSts_HW";
BA_ "LongName" SG_ 564 RRDircnLghtSts_HW "Right Rear Direction Light Status";
BA_ "SysSignalName" SG_ 564 RRDircnLghtSts_HW "RRDircnLghtSts_HW";
BA_ "CompuMethodName" SG_ 564 LdspcOpenSts "LdspcOpenSts";
BA_ "ISignalName" SG_ 564 LdspcOpenSts "ILdspcOpenSts";
BA_ "LongName" SG_ 564 LdspcOpenSts "Loadspace Open Status";
BA_ "SysSignalName" SG_ 564 LdspcOpenSts "LdspcOpenSts";
BA_ "CompuMethodName" SG_ 564 RevsLghtSts "RevsLghtSts";
BA_ "ISignalName" SG_ 564 RevsLghtSts "IRevsLghtSts";
BA_ "LongName" SG_ 564 RevsLghtSts "Reverse Light Status";
BA_ "SysSignalName" SG_ 564 RevsLghtSts "RevsLghtSts";
BA_ "CompuMethodName" SG_ 564 LdspcOpenStsV "LdspcOpenStsV";
BA_ "ISignalName" SG_ 564 LdspcOpenStsV "ILdspcOpenStsV";
BA_ "LongName" SG_ 564 LdspcOpenStsV "Loadspace Open Status";
BA_ "SysSignalName" SG_ 564 LdspcOpenStsV "LdspcOpenStsV";
BA_ "CompuMethodName" SG_ 564 RZCU_50ms_Group37_Reserved63 "RZCU_50ms_Group37_Reserved63";
BA_ "GenSigStartValue" SG_ 564 RZCU_50ms_Group37_Reserved63 255;
BA_ "ISignalName" SG_ 564 RZCU_50ms_Group37_Reserved63 "IRZCU_50ms_Group37_Reserved63";
BA_ "SysSignalName" SG_ 564 RZCU_50ms_Group37_Reserved63 "RZCU_50ms_Group37_Reserved63";
BA_ "CompuMethodName" SG_ 1142 TPMSSnsrRdoFrqcCtr "TPMSSnsrRdoFrqcCtr";
BA_ "ISignalName" SG_ 1142 TPMSSnsrRdoFrqcCtr "ITPMSSnsrRdoFrqcCtr";
BA_ "LongName" SG_ 1142 TPMSSnsrRdoFrqcCtr "Tire Pressure Monitor System Sensor Radio Frequency Counter";
BA_ "SysSignalName" SG_ 1142 TPMSSnsrRdoFrqcCtr "TPMSSnsrRdoFrqcCtr";
BA_ "CompuMethodName" SG_ 1142 TPMSSnsrID "TPMSSnsrID";
BA_ "ISignalName" SG_ 1142 TPMSSnsrID "ITPMSSnsrID";
BA_ "LongName" SG_ 1142 TPMSSnsrID "Tire Pressure Monitor System Sensor Id";
BA_ "SysSignalName" SG_ 1142 TPMSSnsrID "TPMSSnsrID";
BA_ "CompuMethodName" SG_ 1142 TPMSSnsrRdoFrqcCtrLoctn "TPMSSnsrRdoFrqcCtrLoctn";
BA_ "ISignalName" SG_ 1142 TPMSSnsrRdoFrqcCtrLoctn "ITPMSSnsrRdoFrqcCtrLoctn";
BA_ "LongName" SG_ 1142 TPMSSnsrRdoFrqcCtrLoctn "Tire Pressure Monitor System Sensor Radio Frequency Counter Location";
BA_ "SysSignalName" SG_ 1142 TPMSSnsrRdoFrqcCtrLoctn "TPMSSnsrRdoFrqcCtrLoctn";
BA_ "CompuMethodName" SG_ 1142 TPMSSnsrIDLoctn "TPMSSnsrIDLoctn";
BA_ "ISignalName" SG_ 1142 TPMSSnsrIDLoctn "ITPMSSnsrIDLoctn";
BA_ "LongName" SG_ 1142 TPMSSnsrIDLoctn "Tire Pressure Monitor System Sensor Id Location";
BA_ "SysSignalName" SG_ 1142 TPMSSnsrIDLoctn "TPMSSnsrIDLoctn";
BA_ "CompuMethodName" SG_ 1142 TPMSBtmNosRSSI "TPMSBtmNosRSSI";
BA_ "ISignalName" SG_ 1142 TPMSBtmNosRSSI "ITPMSBtmNosRSSI";
BA_ "LongName" SG_ 1142 TPMSBtmNosRSSI "Tire Pressure Monitor System Bottom Noise Received Signal Strength Indicator";
BA_ "SysSignalName" SG_ 1142 TPMSBtmNosRSSI "TPMSBtmNosRSSI";
BA_ "CompuMethodName" SG_ 1142 TPMSSnsrRSSI "TPMSSnsrRSSI";
BA_ "ISignalName" SG_ 1142 TPMSSnsrRSSI "ITPMSSnsrRSSI";
BA_ "LongName" SG_ 1142 TPMSSnsrRSSI "Tire Pressure Monitor System Sensor Received Signal Strength Indicator";
BA_ "SysSignalName" SG_ 1142 TPMSSnsrRSSI "TPMSSnsrRSSI";
BA_ "CompuMethodName" SG_ 210 En12VoltStrMotCmddOn "En12VoltStrMotCmddOn";
BA_ "ISignalName" SG_ 210 En12VoltStrMotCmddOn "IEn12VoltStrMotCmddOn";
BA_ "LongName" SG_ 210 En12VoltStrMotCmddOn "Engine 12 Volt Starter Motor Commanded On";
BA_ "SysSignalName" SG_ 210 En12VoltStrMotCmddOn "En12VoltStrMotCmddOn";
BA_ "CompuMethodName" SG_ 805 NOAQukChgSwReq "NOAQukChgSwReq";
BA_ "ISignalName" SG_ 805 NOAQukChgSwReq "INOAQukChgSwReq";
BA_ "LongName" SG_ 805 NOAQukChgSwReq "NOA quickly change Switch Request";
BA_ "SysSignalName" SG_ 805 NOAQukChgSwReq "NOAQukChgSwReq";
BA_ "CompuMethodName" SG_ 805 PDCPwrSts "PDCPwrSts";
BA_ "ISignalName" SG_ 805 PDCPwrSts "IPDCPwrSts";
BA_ "LongName" SG_ 805 PDCPwrSts "PDC Power Status";
BA_ "SysSignalName" SG_ 805 PDCPwrSts "PDCPwrSts";
BA_ "CompuMethodName" SG_ 805 MMCUPwrSts "MMCUPwrSts";
BA_ "ISignalName" SG_ 805 MMCUPwrSts "IMMCUPwrSts";
BA_ "LongName" SG_ 805 MMCUPwrSts "MMCU Power Status";
BA_ "SysSignalName" SG_ 805 MMCUPwrSts "MMCUPwrSts";
BA_ "CompuMethodName" SG_ 805 FICMACRTemV "FICMACRTemV";
BA_ "GenSigStartValue" SG_ 805 FICMACRTemV 1;
BA_ "ISignalName" SG_ 805 FICMACRTemV "IFICMACRTemV";
BA_ "LongName" SG_ 805 FICMACRTemV "Front Infotainment Control Module Air Conditioning Right Temperature Validity";
BA_ "SysSignalName" SG_ 805 FICMACRTemV "FICMACRTemV";
BA_ "CompuMethodName" SG_ 805 AIParkngReq_ZXD "AIParkngReq_ZXD";
BA_ "ISignalName" SG_ 805 AIParkngReq_ZXD "IAIParkngReq_ZXD";
BA_ "LongName" SG_ 805 AIParkngReq_ZXD "ParkingRequest_ZXD";
BA_ "SysSignalName" SG_ 805 AIParkngReq_ZXD "AIParkngReq_ZXD";
BA_ "CompuMethodName" SG_ 805 FICMACRAirMdSwReq "FICMACRAirMdSwReq";
BA_ "ISignalName" SG_ 805 FICMACRAirMdSwReq "IFICMACRAirMdSwReq";
BA_ "LongName" SG_ 805 FICMACRAirMdSwReq "Front Infotainment Control Module Air Conditioning Mode Switch Request";
BA_ "SysSignalName" SG_ 805 FICMACRAirMdSwReq "FICMACRAirMdSwReq";
BA_ "CompuMethodName" SG_ 805 FICMACLAirMdSwReq "FICMACLAirMdSwReq";
BA_ "ISignalName" SG_ 805 FICMACLAirMdSwReq "IFICMACLAirMdSwReq";
BA_ "LongName" SG_ 805 FICMACLAirMdSwReq "Front Infotainment Control Module Air Conditioning Mode Switch Request";
BA_ "SysSignalName" SG_ 805 FICMACLAirMdSwReq "FICMACLAirMdSwReq";
BA_ "CompuMethodName" SG_ 805 FICMACIonizerReqSwReq "FICMACIonizerReqSwReq";
BA_ "ISignalName" SG_ 805 FICMACIonizerReqSwReq "IFICMACIonizerReqSwReq";
BA_ "SysSignalName" SG_ 805 FICMACIonizerReqSwReq "FICMACIonizerReqSwReq";
BA_ "CompuMethodName" SG_ 805 FICMACFreshSwReq "FICMACFreshSwReq";
BA_ "ISignalName" SG_ 805 FICMACFreshSwReq "IFICMACFreshSwReq";
BA_ "SysSignalName" SG_ 805 FICMACFreshSwReq "FICMACFreshSwReq";
BA_ "CompuMethodName" SG_ 805 FICMClmOnOffSwReq "FICMClmOnOffSwReq";
BA_ "ISignalName" SG_ 805 FICMClmOnOffSwReq "IFICMClmOnOffSwReq";
BA_ "LongName" SG_ 805 FICMClmOnOffSwReq "Front Infotainment Control Module Climate On Off Switch Request";
BA_ "SysSignalName" SG_ 805 FICMClmOnOffSwReq "FICMClmOnOffSwReq";
BA_ "CompuMethodName" SG_ 805 FICMACSyncSwReq "FICMACSyncSwReq";
BA_ "ISignalName" SG_ 805 FICMACSyncSwReq "IFICMACSyncSwReq";
BA_ "LongName" SG_ 805 FICMACSyncSwReq "Front Infotainment Control Module Air Conditioning Sync Switch Request";
BA_ "SysSignalName" SG_ 805 FICMACSyncSwReq "FICMACSyncSwReq";
BA_ "CompuMethodName" SG_ 805 FICMACRTemIncSwReq "FICMACRTemIncSwReq";
BA_ "ISignalName" SG_ 805 FICMACRTemIncSwReq "IFICMACRTemIncSwReq";
BA_ "LongName" SG_ 805 FICMACRTemIncSwReq "Front Infotainment Control Module Air Conditioning Right Temperature Increase Switch Request";
BA_ "SysSignalName" SG_ 805 FICMACRTemIncSwReq "FICMACRTemIncSwReq";
BA_ "CompuMethodName" SG_ 805 FICMACRTemDecSwReq "FICMACRTemDecSwReq";
BA_ "ISignalName" SG_ 805 FICMACRTemDecSwReq "IFICMACRTemDecSwReq";
BA_ "LongName" SG_ 805 FICMACRTemDecSwReq "Front Infotainment Control Module Air Conditioning Right Temperature Decrease Switch Request";
BA_ "SysSignalName" SG_ 805 FICMACRTemDecSwReq "FICMACRTemDecSwReq";
BA_ "CompuMethodName" SG_ 805 FICMAirClnrBlwrLvlReq "FICMAirClnrBlwrLvlReq";
BA_ "ISignalName" SG_ 805 FICMAirClnrBlwrLvlReq "IFICMAirClnrBlwrLvlReq";
BA_ "LongName" SG_ 805 FICMAirClnrBlwrLvlReq "Front Infotainment Control Module Air Cleaner Blower Level Request";
BA_ "SysSignalName" SG_ 805 FICMAirClnrBlwrLvlReq "FICMAirClnrBlwrLvlReq";
BA_ "CompuMethodName" SG_ 805 FICMACRTemReq "FICMACRTemReq";
BA_ "GenSigStartValue" SG_ 805 FICMACRTemReq 31;
BA_ "ISignalName" SG_ 805 FICMACRTemReq "IFICMACRTemReq";
BA_ "LongName" SG_ 805 FICMACRTemReq "Front Infotainment Control Module Air Conditioning Left Temperature Request";
BA_ "SysSignalName" SG_ 805 FICMACRTemReq "FICMACRTemReq";
BA_ "CompuMethodName" SG_ 805 AutoLaneChngVcCmd "AutoLaneChngVcCmd";
BA_ "ISignalName" SG_ 805 AutoLaneChngVcCmd "IAutoLaneChngVcCmd";
BA_ "LongName" SG_ 805 AutoLaneChngVcCmd "Auto Lane Change Voice Command";
BA_ "SysSignalName" SG_ 805 AutoLaneChngVcCmd "AutoLaneChngVcCmd";
BA_ "CompuMethodName" SG_ 805 APAParkInOffsetTypeReq "APAParkInOffsetTypeReq";
BA_ "ISignalName" SG_ 805 APAParkInOffsetTypeReq "IAPAParkInOffsetTypeReq";
BA_ "LongName" SG_ 805 APAParkInOffsetTypeReq "apa_change_park_in_offset_type_request";
BA_ "SysSignalName" SG_ 805 APAParkInOffsetTypeReq "APAParkInOffsetTypeReq";
BA_ "CompuMethodName" SG_ 805 FICMIFPACOnOffSwReq "FICMIFPACOnOffSwReq";
BA_ "ISignalName" SG_ 805 FICMIFPACOnOffSwReq "IFICMIFPACOnOffSwReq";
BA_ "LongName" SG_ 805 FICMIFPACOnOffSwReq "Front Infotainment Control Module Infotainment Faceplate Air Conditioning On Off Switch Request";
BA_ "SysSignalName" SG_ 805 FICMIFPACOnOffSwReq "FICMIFPACOnOffSwReq";
BA_ "CompuMethodName" SG_ 805 NOAReportSetSwReq "NOAReportSetSwReq";
BA_ "ISignalName" SG_ 805 NOAReportSetSwReq "INOAReportSetSwReq";
BA_ "LongName" SG_ 805 NOAReportSetSwReq "NOA Report Set Switch Request";
BA_ "SysSignalName" SG_ 805 NOAReportSetSwReq "NOAReportSetSwReq";
BA_ "CompuMethodName" SG_ 805 NarRoVslAssSwReq "NarRoVslAssSwReq";
BA_ "ISignalName" SG_ 805 NarRoVslAssSwReq "INarRoVslAssSwReq";
BA_ "LongName" SG_ 805 NarRoVslAssSwReq "Narrow Road Visual Assist Switch Request";
BA_ "SysSignalName" SG_ 805 NarRoVslAssSwReq "NarRoVslAssSwReq";
BA_ "CompuMethodName" SG_ 805 ParkngSpdSwResp "ParkngSpdSwResp";
BA_ "ISignalName" SG_ 805 ParkngSpdSwResp "IParkngSpdSwResp";
BA_ "LongName" SG_ 805 ParkngSpdSwResp "Parking_Speed_Switch_Response";
BA_ "SysSignalName" SG_ 805 ParkngSpdSwResp "ParkngSpdSwResp";
BA_ "CompuMethodName" SG_ 805 NrwroadBwdAssSwReq "NrwroadBwdAssSwReq";
BA_ "ISignalName" SG_ 805 NrwroadBwdAssSwReq "INrwroadBwdAssSwReq";
BA_ "LongName" SG_ 805 NrwroadBwdAssSwReq "Narrow road Backward Assistance Switch Request";
BA_ "SysSignalName" SG_ 805 NrwroadBwdAssSwReq "NrwroadBwdAssSwReq";
BA_ "CompuMethodName" SG_ 805 AutoLaneChngSwReq "AutoLaneChngSwReq";
BA_ "ISignalName" SG_ 805 AutoLaneChngSwReq "IAutoLaneChngSwReq";
BA_ "LongName" SG_ 805 AutoLaneChngSwReq "Auto_Lane_Change_Switch_Request";
BA_ "SysSignalName" SG_ 805 AutoLaneChngSwReq "AutoLaneChngSwReq";
BA_ "CompuMethodName" SG_ 805 ESSAdoWrnngReq "ESSAdoWrnngReq";
BA_ "ISignalName" SG_ 805 ESSAdoWrnngReq "IESSAdoWrnngReq";
BA_ "LongName" SG_ 805 ESSAdoWrnngReq "Emergency_Steering_System__Audio_Warning_Request";
BA_ "SysSignalName" SG_ 805 ESSAdoWrnngReq "ESSAdoWrnngReq";
BA_ "CompuMethodName" SG_ 805 AutoLaneChngSetReq "AutoLaneChngSetReq";
BA_ "ISignalName" SG_ 805 AutoLaneChngSetReq "IAutoLaneChngSetReq";
BA_ "LongName" SG_ 805 AutoLaneChngSetReq "Auto Lane Change Set Request";
BA_ "SysSignalName" SG_ 805 AutoLaneChngSetReq "AutoLaneChngSetReq";
BA_ "CompuMethodName" SG_ 805 APASWReq "APASWReq";
BA_ "ISignalName" SG_ 805 APASWReq "IAPASWReq";
BA_ "LongName" SG_ 805 APASWReq "apa_switch_setting_request";
BA_ "SysSignalName" SG_ 805 APASWReq "APASWReq";
BA_ "CompuMethodName" SG_ 805 APAOneKeyParkSwReq "APAOneKeyParkSwReq";
BA_ "ISignalName" SG_ 805 APAOneKeyParkSwReq "IAPAOneKeyParkSwReq";
BA_ "LongName" SG_ 805 APAOneKeyParkSwReq "APA_One_Key_Parking_Switch_Request";
BA_ "SysSignalName" SG_ 805 APAOneKeyParkSwReq "APAOneKeyParkSwReq";
BA_ "CompuMethodName" SG_ 805 NarRoVslAssQuit "NarRoVslAssQuit";
BA_ "ISignalName" SG_ 805 NarRoVslAssQuit "INarRoVslAssQuit";
BA_ "LongName" SG_ 805 NarRoVslAssQuit "Narrow Road Visual Assist Quit";
BA_ "SysSignalName" SG_ 805 NarRoVslAssQuit "NarRoVslAssQuit";
BA_ "CompuMethodName" SG_ 805 LCRSwReq "LCRSwReq";
BA_ "ISignalName" SG_ 805 LCRSwReq "ILCRSwReq";
BA_ "LongName" SG_ 805 LCRSwReq "Lane Change Recommendation Switch Request";
BA_ "SysSignalName" SG_ 805 LCRSwReq "LCRSwReq";
BA_ "CompuMethodName" SG_ 805 FrtCarGoNotfrSwReq "FrtCarGoNotfrSwReq";
BA_ "ISignalName" SG_ 805 FrtCarGoNotfrSwReq "IFrtCarGoNotfrSwReq";
BA_ "LongName" SG_ 805 FrtCarGoNotfrSwReq "FrontCar GoNotifierSwltchRequest";
BA_ "SysSignalName" SG_ 805 FrtCarGoNotfrSwReq "FrtCarGoNotfrSwReq";
BA_ "CompuMethodName" SG_ 805 ESSswReq "ESSswReq";
BA_ "ISignalName" SG_ 805 ESSswReq "IESSswReq";
BA_ "LongName" SG_ 805 ESSswReq "Emergency_Steering_Switch_Request";
BA_ "SysSignalName" SG_ 805 ESSswReq "ESSswReq";
BA_ "CompuMethodName" SG_ 805 NOPSwReq "NOPSwReq";
BA_ "ISignalName" SG_ 805 NOPSwReq "INOPSwReq";
BA_ "LongName" SG_ 805 NOPSwReq "Hads Navigation On Pilot Switch Request";
BA_ "SysSignalName" SG_ 805 NOPSwReq "NOPSwReq";
BA_ "CompuMethodName" SG_ 805 NOPCitySwReq "NOPCitySwReq";
BA_ "ISignalName" SG_ 805 NOPCitySwReq "INOPCitySwReq";
BA_ "LongName" SG_ 805 NOPCitySwReq "Navigation On Pilot City Switch Request";
BA_ "SysSignalName" SG_ 805 NOPCitySwReq "NOPCitySwReq";
BA_ "CompuMethodName" SG_ 805 NOALaneSetSwReq "NOALaneSetSwReq";
BA_ "ISignalName" SG_ 805 NOALaneSetSwReq "INOALaneSetSwReq";
BA_ "LongName" SG_ 805 NOALaneSetSwReq "NOA Lane Set Switch Request";
BA_ "SysSignalName" SG_ 805 NOALaneSetSwReq "NOALaneSetSwReq";
BA_ "CompuMethodName" SG_ 805 NOAETCSetSwReq "NOAETCSetSwReq";
BA_ "ISignalName" SG_ 805 NOAETCSetSwReq "INOAETCSetSwReq";
BA_ "LongName" SG_ 805 NOAETCSetSwReq "NOA ETC Set Switch Request";
BA_ "SysSignalName" SG_ 805 NOAETCSetSwReq "NOAETCSetSwReq";
BA_ "CompuMethodName" SG_ 805 WlcmLghtReq "WlcmLghtReq";
BA_ "ISignalName" SG_ 805 WlcmLghtReq "IWlcmLghtReq";
BA_ "LongName" SG_ 805 WlcmLghtReq "Welcome Light Request";
BA_ "SysSignalName" SG_ 805 WlcmLghtReq "WlcmLghtReq";
BA_ "CompuMethodName" SG_ 805 D2DSwReq "D2DSwReq";
BA_ "ISignalName" SG_ 805 D2DSwReq "ID2DSwReq";
BA_ "LongName" SG_ 805 D2DSwReq "D2D Swicth Request";
BA_ "SysSignalName" SG_ 805 D2DSwReq "D2DSwReq";
BA_ "CompuMethodName" SG_ 805 ParkngDirSw "ParkngDirSw";
BA_ "ISignalName" SG_ 805 ParkngDirSw "IParkngDirSw";
BA_ "LongName" SG_ 805 ParkngDirSw "Parking_Direction_Switch";
BA_ "SysSignalName" SG_ 805 ParkngDirSw "ParkngDirSw";
BA_ "CompuMethodName" SG_ 805 NrwroadBwdAssConfrmSwReq "NrwroadBwdAssConfrmSwReq";
BA_ "ISignalName" SG_ 805 NrwroadBwdAssConfrmSwReq "INrwroadBwdAssConfrmSwReq";
BA_ "LongName" SG_ 805 NrwroadBwdAssConfrmSwReq "Narrow road Backward Assistance Conform Switch Request";
BA_ "SysSignalName" SG_ 805 NrwroadBwdAssConfrmSwReq "NrwroadBwdAssConfrmSwReq";
BA_ "CompuMethodName" SG_ 805 DistToDsttnNavForSus "DistToDsttnNavForSus";
BA_ "GenSigStartValue" SG_ 805 DistToDsttnNavForSus 255;
BA_ "ISignalName" SG_ 805 DistToDsttnNavForSus "IDistToDsttnNavForSus";
BA_ "LongName" SG_ 805 DistToDsttnNavForSus "Distance To Destination of Navigation For Suspension";
BA_ "SysSignalName" SG_ 805 DistToDsttnNavForSus "DistToDsttnNavForSus";
BA_ "CompuMethodName" SG_ 805 FrwlLghtReq "FrwlLghtReq";
BA_ "ISignalName" SG_ 805 FrwlLghtReq "IFrwlLghtReq";
BA_ "LongName" SG_ 805 FrwlLghtReq "Farewell Light Request";
BA_ "SysSignalName" SG_ 805 FrwlLghtReq "FrwlLghtReq";
BA_ "CompuMethodName" SG_ 805 FollowMeHomeReq "FollowMeHomeReq";
BA_ "ISignalName" SG_ 805 FollowMeHomeReq "IFollowMeHomeReq";
BA_ "LongName" SG_ 805 FollowMeHomeReq "Follow Me Home Request";
BA_ "SysSignalName" SG_ 805 FollowMeHomeReq "FollowMeHomeReq";
BA_ "CompuMethodName" SG_ 805 FICMChrgSttnMchngSta "FICMChrgSttnMchngSta";
BA_ "ISignalName" SG_ 805 FICMChrgSttnMchngSta "IFICMChrgSttnMchngSta";
BA_ "LongName" SG_ 805 FICMChrgSttnMchngSta "FICM Charge Station Matching State";
BA_ "SysSignalName" SG_ 805 FICMChrgSttnMchngSta "FICMChrgSttnMchngSta";
BA_ "CompuMethodName" SG_ 805 FVCMPowerFailSwReq "FVCMPowerFailSwReq";
BA_ "ISignalName" SG_ 805 FVCMPowerFailSwReq "IFVCMPowerFailSwReq";
BA_ "LongName" SG_ 805 FVCMPowerFailSwReq "FVCM_Power_Faile_Switch_Request";
BA_ "SysSignalName" SG_ 805 FVCMPowerFailSwReq "FVCMPowerFailSwReq";
BA_ "CompuMethodName" SG_ 805 D2DPriETClanSwReq "D2DPriETClanSwReq";
BA_ "ISignalName" SG_ 805 D2DPriETClanSwReq "ID2DPriETClanSwReq";
BA_ "LongName" SG_ 805 D2DPriETClanSwReq "D2D Priority ETC Lane Switch Request";
BA_ "SysSignalName" SG_ 805 D2DPriETClanSwReq "D2DPriETClanSwReq";
BA_ "CompuMethodName" SG_ 805 SLIFWrnngMdReq "SLIFWrnngMdReq";
BA_ "ISignalName" SG_ 805 SLIFWrnngMdReq "ISLIFWrnngMdReq";
BA_ "LongName" SG_ 805 SLIFWrnngMdReq "Speed Limit Information Function Warning Mode Request";
BA_ "SysSignalName" SG_ 805 SLIFWrnngMdReq "SLIFWrnngMdReq";
BA_ "CompuMethodName" SG_ 805 AIParkngEPAMdsw "AIParkngEPAMdsw";
BA_ "ISignalName" SG_ 805 AIParkngEPAMdsw "IAIParkngEPAMdsw";
BA_ "LongName" SG_ 805 AIParkngEPAMdsw "AIParking Exterior Parking Assist Model Switch";
BA_ "SysSignalName" SG_ 805 AIParkngEPAMdsw "AIParkngEPAMdsw";
BA_ "CompuMethodName" SG_ 805 PEBSwReq "PEBSwReq";
BA_ "ISignalName" SG_ 805 PEBSwReq "IPEBSwReq";
BA_ "LongName" SG_ 805 PEBSwReq "Parking_Emergency_Brake_Switch_Request";
BA_ "SysSignalName" SG_ 805 PEBSwReq "PEBSwReq";
BA_ "CompuMethodName" SG_ 711 SpedRegulaModSwReq "SpedRegulaModSwReq";
BA_ "ISignalName" SG_ 711 SpedRegulaModSwReq "ISpedRegulaModSwReq";
BA_ "LongName" SG_ 711 SpedRegulaModSwReq "Speed Regulation Mode Switch request";
BA_ "SysSignalName" SG_ 711 SpedRegulaModSwReq "SpedRegulaModSwReq";
BA_ "CompuMethodName" SG_ 1216 ZXD_NM_BSMtoRMS_BKPCANFD "ZXD_NM_BSMtoRMS_BKPCANFD";
BA_ "ISignalName" SG_ 1216 ZXD_NM_BSMtoRMS_BKPCANFD "IZXD_NM_BSMtoRMS_BKPCANFD";
BA_ "LongName" SG_ 1216 ZXD_NM_BSMtoRMS_BKPCANFD "ZXD_NM_BSMtoRMS_BKPCANFD";
BA_ "SysSignalName" SG_ 1216 ZXD_NM_BSMtoRMS_BKPCANFD "ZXD_NM_BSMtoRMS_BKPCANFD";
BA_ "CompuMethodName" SG_ 1216 ZXD_NM_PBSMtoRMS_BKPCANFD "ZXD_NM_PBSMtoRMS_BKPCANFD";
BA_ "ISignalName" SG_ 1216 ZXD_NM_PBSMtoRMS_BKPCANFD "IZXD_NM_PBSMtoRMS_BKPCANFD";
BA_ "LongName" SG_ 1216 ZXD_NM_PBSMtoRMS_BKPCANFD "ZXD_NM_PBSMtoRMS_BKPCANFD";
BA_ "SysSignalName" SG_ 1216 ZXD_NM_PBSMtoRMS_BKPCANFD "ZXD_NM_PBSMtoRMS_BKPCANFD";
BA_ "CompuMethodName" SG_ 1216 ZXD_NM_RMStoNOS_BKPCANFD "ZXD_NM_RMStoNOS_BKPCANFD";
BA_ "ISignalName" SG_ 1216 ZXD_NM_RMStoNOS_BKPCANFD "IZXD_NM_RMStoNOS_BKPCANFD";
BA_ "LongName" SG_ 1216 ZXD_NM_RMStoNOS_BKPCANFD "ZXD_NM_RMStoNOS_BKPCANFD";
BA_ "SysSignalName" SG_ 1216 ZXD_NM_RMStoNOS_BKPCANFD "ZXD_NM_RMStoNOS_BKPCANFD";
BA_ "CompuMethodName" SG_ 1216 ZXD_NM_RSStoNOS_BKPCANFD "ZXD_NM_RSStoNOS_BKPCANFD";
BA_ "ISignalName" SG_ 1216 ZXD_NM_RSStoNOS_BKPCANFD "IZXD_NM_RSStoNOS_BKPCANFD";
BA_ "LongName" SG_ 1216 ZXD_NM_RSStoNOS_BKPCANFD "ZXD_NM_RSStoNOS_BKPCANFD";
BA_ "SysSignalName" SG_ 1216 ZXD_NM_RSStoNOS_BKPCANFD "ZXD_NM_RSStoNOS_BKPCANFD";
BA_ "CompuMethodName" SG_ 1216 ZXD_NM_RSStoRMS_BKPCANFD "ZXD_NM_RSStoRMS_BKPCANFD";
BA_ "ISignalName" SG_ 1216 ZXD_NM_RSStoRMS_BKPCANFD "IZXD_NM_RSStoRMS_BKPCANFD";
BA_ "LongName" SG_ 1216 ZXD_NM_RSStoRMS_BKPCANFD "ZXD_NM_RSStoRMS_BKPCANFD";
BA_ "SysSignalName" SG_ 1216 ZXD_NM_RSStoRMS_BKPCANFD "ZXD_NM_RSStoRMS_BKPCANFD";
BA_ "CompuMethodName" SG_ 1216 ZXD_NM_NOStoRMS_BKPCANFD "ZXD_NM_NOStoRMS_BKPCANFD";
BA_ "ISignalName" SG_ 1216 ZXD_NM_NOStoRMS_BKPCANFD "IZXD_NM_NOStoRMS_BKPCANFD";
BA_ "LongName" SG_ 1216 ZXD_NM_NOStoRMS_BKPCANFD "ZXD_NM_NOStoRMS_BKPCANFD";
BA_ "SysSignalName" SG_ 1216 ZXD_NM_NOStoRMS_BKPCANFD "ZXD_NM_NOStoRMS_BKPCANFD";
BA_ "CompuMethodName" SG_ 1216 ZXD_NM_NOSSta_BKPCANFD "ZXD_NM_NOSSta_BKPCANFD";
BA_ "ISignalName" SG_ 1216 ZXD_NM_NOSSta_BKPCANFD "IZXD_NM_NOSSta_BKPCANFD";
BA_ "LongName" SG_ 1216 ZXD_NM_NOSSta_BKPCANFD "ZXD_NM_NOSSta_BKPCANFD";
BA_ "SysSignalName" SG_ 1216 ZXD_NM_NOSSta_BKPCANFD "ZXD_NM_NOSSta_BKPCANFD";
BA_ "CompuMethodName" SG_ 1216 ZXD_NM_RMSSta_BKPCANFD "ZXD_NM_RMSSta_BKPCANFD";
BA_ "ISignalName" SG_ 1216 ZXD_NM_RMSSta_BKPCANFD "IZXD_NM_RMSSta_BKPCANFD";
BA_ "LongName" SG_ 1216 ZXD_NM_RMSSta_BKPCANFD "ZXD_NM_RMSSta_BKPCANFD";
BA_ "SysSignalName" SG_ 1216 ZXD_NM_RMSSta_BKPCANFD "ZXD_NM_RMSSta_BKPCANFD";
BA_ "CompuMethodName" SG_ 1216 ZXD_NWI_BKPCANFD "ZXD_NWI_BKPCANFD";
BA_ "ISignalName" SG_ 1216 ZXD_NWI_BKPCANFD "IZXD_NWI_BKPCANFD";
BA_ "LongName" SG_ 1216 ZXD_NWI_BKPCANFD "ZXD BKPCANFD Network_Wakeup_Indication";
BA_ "SysSignalName" SG_ 1216 ZXD_NWI_BKPCANFD "ZXD_NWI_BKPCANFD";
BA_ "CompuMethodName" SG_ 1216 ZXD_NOI_BKPCANFD "ZXD_NOI_BKPCANFD";
BA_ "ISignalName" SG_ 1216 ZXD_NOI_BKPCANFD "IZXD_NOI_BKPCANFD";
BA_ "LongName" SG_ 1216 ZXD_NOI_BKPCANFD "ZXD BKPCANFD Network Operation Indication";
BA_ "SysSignalName" SG_ 1216 ZXD_NOI_BKPCANFD "ZXD_NOI_BKPCANFD";
BA_ "CompuMethodName" SG_ 1216 ZXD_NKI_BKPCANFD "ZXD_NKI_BKPCANFD";
BA_ "ISignalName" SG_ 1216 ZXD_NKI_BKPCANFD "IZXD_NKI_BKPCANFD";
BA_ "LongName" SG_ 1216 ZXD_NKI_BKPCANFD "ZXD BKPCANFD Network Keep Indication";
BA_ "SysSignalName" SG_ 1216 ZXD_NKI_BKPCANFD "ZXD_NKI_BKPCANFD";
VAL_ 299 DippedBeamActStatus 0 "DippedBeamActStatus_0_OFF" 1 "DippedBeamActStatus_1_ON";
VAL_ 299 RevsLghtCtrl 0 "RevsLghtCtrl_0_Off" 1 "RevsLghtCtrl_1_On";
VAL_ 299 PriySSBA 0 "PriySSBA_0_False" 1 "PriySSBA_1_True";
VAL_ 299 PriySSBAV 0 "PriySSBAV_0_Valid" 1 "PriySSBAV_1_Invalid";
VAL_ 299 SecySSBA 0 "SecySSBA_0_False" 1 "SecySSBA_1_True";
VAL_ 299 SecySSBAV 0 "SecySSBAV_0_Valid" 1 "SecySSBAV_1_Invalid";
VAL_ 299 SSBTrigd 0 "SSBTrigd_0_False" 1 "SSBTrigd_1_True";
VAL_ 299 RMainBeamLghtCtrl 0 "RMainBeamLghtCtrl_0_Off" 1 "RMainBeamLghtCtrl_1_On";
VAL_ 299 LMainBeamLghtCtrl 0 "LMainBeamLghtCtrl_0_Off" 1 "LMainBeamLghtCtrl_1_On";
VAL_ 299 RRDircnLghtCtrl 0 "RRDircnLghtCtrl_0_Off" 1 "RRDircnLghtCtrl_1_on";
VAL_ 299 RLDircnLghtCtrl 0 "RLDircnLghtCtrl_0_Off" 1 "RLDircnLghtCtrl_1_on";
VAL_ 299 FRDircnLghtCtrl 0 "FRDircnLghtCtrl_0_Off" 1 "FRDircnLghtCtrl_1_on";
VAL_ 299 FLDircnLghtCtrl 0 "FLDircnLghtCtrl_0_Off" 1 "FLDircnLghtCtrl_1_on";
VAL_ 299 BrkLghtCtrl 0 "BrkLghtCtrl_0_Off" 1 "BrkLghtCtrl_1_On";
VAL_ 299 HzrdLghtSwReq 0 "HzrdLghtSwReq_0_Off" 1 "HzrdLghtSwReq_1_On";
VAL_ 566 FindCarFuncInfoDsp 0 "FindCarFuncInfoDsp_0_DIsable" 1 "FindCarFuncInfoDsp_1_Light_Horn_Enable" 2 "FindCarFuncInfoDsp_2_Light_Enable" 3 "FindCarFuncInfoDsp_3_Horn_Enable";
VAL_ 566 FLDoorHndlPESwtActv 0 "FLDoorHndlPESwtActv_0_NoPress" 1 "FLDoorHndlPESwtActv_1_ShortPress" 2 "FLDoorHndlPESwtActv_2_LongPress" 3 "FLDoorHndlPESwtActv_3_ActivePress";
VAL_ 566 FRDoorHndlPESwtActv 0 "FRDoorHndlPESwtActv_0_NoPress" 1 "FRDoorHndlPESwtActv_1_ShortPress" 2 "FRDoorHndlPESwtActv_2_LongPress" 3 "FRDoorHndlPESwtActv_3_ActivePress";
VAL_ 566 BrkLghtSwStsV 0 "BrkLghtSwStsV_0_Valid" 1 "BrkLghtSwStsV_1_Invalid";
VAL_ 566 BrkLghtSwSts 0 "BrkLghtSwSts_0_Off" 1 "BrkLghtSwSts_1_On";
VAL_ 566 RrWiperReq 0 "RrWiperReq_0_No_Request" 1 "RrWiperReq_1_Request";
VAL_ 566 MainBeamLghtSwSts 0 "MainBeamLghtSwSts_0_Off" 1 "MainBeamLghtSwSts_1_On" 2 "MainBeamLghtSwSts_2_Flash";
VAL_ 566 DircnIndLghtSwSts 0 "DircnIndLghtSwSts_0_off" 1 "DircnIndLghtSwSts_1_LeftOn" 2 "DircnIndLghtSwSts_2_RightOn" 3 "DircnIndLghtSwSts_3_reserve";
VAL_ 566 LdspcRlseSwtActv 0 "LdspcRlseSwtActv_0_Inactive" 1 "LdspcRlseSwtActv_1_Active";
VAL_ 566 FLDSP_RRWinSwtSts 0 "FLDSP_RRWinSwtSts_0_no_request" 1 "FLDSP_RRWinSwtSts_1_up_request" 2 "FLDSP_RRWinSwtSts_2_down_request" 3 "FLDSP_RRWinSwtSts_3_auto_up_request" 4 "FLDSP_RRWinSwtSts_4_auto_down_request";
VAL_ 566 FLDSP_RLWinSwtSts 0 "FLDSP_RLWinSwtSts_0_no_request" 1 "FLDSP_RLWinSwtSts_1_up_request" 2 "FLDSP_RLWinSwtSts_2_down_request" 3 "FLDSP_RLWinSwtSts_3_auto_up_request" 4 "FLDSP_RLWinSwtSts_4_auto_down_request";
VAL_ 566 FLDSP_FRWinSwtSts 0 "FLDSP_FRWinSwtSts_0_no_request" 1 "FLDSP_FRWinSwtSts_1_up_request" 2 "FLDSP_FRWinSwtSts_2_down_request" 3 "FLDSP_FRWinSwtSts_3_auto_up_request" 4 "FLDSP_FRWinSwtSts_4_auto_down_request";
VAL_ 566 BrkPdlTrigd 0 "BrkPdlTrigd_0_False" 1 "BrkPdlTrigd_1_True";
VAL_ 566 FLWinLclSwtSts 0 "FLWinLclSwtSts_0_no_request" 1 "FLWinLclSwtSts_1_up_request" 2 "FLWinLclSwtSts_2_down_request" 3 "FLWinLclSwtSts_3_auto_up_request" 4 "FLWinLclSwtSts_4_auto_down_request";
VAL_ 566 ExtrLckActnIndcn 0 "ExtrLckActnIndcn_0_NoAction" 1 "ExtrLckActnIndcn_1_LockAction" 2 "ExtrLckActnIndcn_2_UnLockAction" 3 "ExtrLckActnIndcn_3_Reserved" 4 "ExtrLckActnIndcn_4_Reserved" 5 "ExtrLckActnIndcn_5_Reserved" 6 "ExtrLckActnIndcn_6_Reserved" 7 "ExtrLckActnIndcn_7_Reserved";
VAL_ 566 AutoMainBeamLghtSts 0 "AutoMainBeamLghtSts_0_Auto_Main_Beam_OFF_and_Main_Beam_OFF" 1 "AutoMainBeamLghtSts_1_Auto_Main_Beam_OFF_and_Main_Beam_ON" 2 "AutoMainBeamLghtSts_2_Auto_Main_Beam_On_and_Main_Beam_OFF" 3 "AutoMainBeamLghtSts_3_Auto_Main_Beam_On_and_Main_Beam_ON";
VAL_ 566 DrvrDetSnsrFltSts 0 "DrvrDetSnsrFltSts_0_NoFault" 1 "DrvrDetSnsrFltSts_1_ShortToGnd" 2 "DrvrDetSnsrFltSts_2_ShortToBattery" 3 "DrvrDetSnsrFltSts_3_OpenCircuit";
VAL_ 566 DircnIndLghtMdSts 0 "DircnIndLghtMdSts_0_off" 1 "DircnIndLghtMdSts_1_Left_First_gear_On" 2 "DircnIndLghtMdSts_2_Left_Second_gear_On" 3 "DircnIndLghtMdSts_3_Right_First_gear_On" 4 "DircnIndLghtMdSts_4_Right_Second_gear_On" 5 "DircnIndLghtMdSts_5_reserve";
VAL_ 652 DrvrDetSts 0 "DrvrDetSts_0_NoDriverPresent" 1 "DrvrDetSts_1_DriverPresent" 2 "DrvrDetSts_2_SensorFault";
VAL_ 652 RLDoorOpenSts 0 "RLDoorOpenSts_0_Closed" 1 "RLDoorOpenSts_1_CantDetectDoorAjarStatus" 2 "RLDoorOpenSts_2_Ajar" 3 "RLDoorOpenSts_3_Open";
VAL_ 652 DrvrDoorOpenSts 0 "DrvrDoorOpenSts_0_Closed" 1 "DrvrDoorOpenSts_1_CantDetectDoorAjarStatus" 2 "DrvrDoorOpenSts_2_Ajar" 3 "DrvrDoorOpenSts_3_Open";
VAL_ 652 BntOpenSts 0 "BntOpenSts_0_BonnetClosed" 1 "BntOpenSts_1_BonnetOpen" 2 "BntOpenSts_2_BonnetSwitchDisconnect" 3 "BntOpenSts_3_Reserved";
VAL_ 652 VehLckSts 0 "VehLckSts_0_Unlocked" 1 "VehLckSts_1_SignalPositionEntryUnlocked" 2 "VehLckSts_2_InteriorLocked" 3 "VehLckSts_3_ExteriorLocked" 4 "VehLckSts_4_SuperLocked" 5 "VehLckSts_5_Reserved" 6 "VehLckSts_6_Reserved" 7 "VehLckSts_7_Unknow";
VAL_ 652 RLSInitnFltPrst 0 "RLSInitnFltPrst_l_0_False" 1 "RLSInitnFltPrst_l_1_True";
VAL_ 652 DirnLghtSftyMonErr 0 "DirnLghtSftyMonErr_0_no_error" 1 "DirnLghtSftyMonErr_1_communication_error" 2 "DirnLghtSftyMonErr_2_internal_error" 3 "DirnLghtSftyMonErr_3_unkown";
VAL_ 547 SideLghtSts 0 "SideLghtSts_0_Off" 1 "SideLghtSts_1_On";
VAL_ 547 LHZCUeFs12Sts 0 "LHZCUeFs12Sts_0_Unknown" 1 "LHZCUeFs12Sts_1_Off" 2 "LHZCUeFs12Sts_2_On" 3 "LHZCUeFs12Sts_3_LatchOn" 4 "LHZCUeFs12Sts_4_FailureOff" 5 "LHZCUeFs12Sts_5_GoingDown";
VAL_ 547 LHZCUeFs12DiagSts 0 "LHZCUeFs12DiagSts_0_NoFault" 1 "LHZCUeFs12DiagSts_1_OCP" 2 "LHZCUeFs12DiagSts_2_OVP" 3 "LHZCUeFs12DiagSts_3_UVP" 4 "LHZCUeFs12DiagSts_4_OT" 5 "LHZCUeFs12DiagSts_5_SPI_Fault" 6 "LHZCUeFs12DiagSts_6_ChipFault" 7 "LHZCUeFs12DiagSts_7_OpenCircuit" 8 "LHZCUeFs12DiagSts_8_ShortToGND" 9 "LHZCUeFs12DiagSts_9_ShortToBattery" 10 "LHZCUeFs12DiagSts_10_OtherFault" 11 "LHZCUeFs12DiagSts_11_Drive_Mismatch";
VAL_ 547 LHZCUeSw17Sts 0 "LHZCUeSw17Sts_0_Unknown" 1 "LHZCUeSw17Sts_1_Off" 2 "LHZCUeSw17Sts_2_On" 3 "LHZCUeSw17Sts_3_LatchOn" 4 "LHZCUeSw17Sts_4_FailureOff" 5 "LHZCUeSw17Sts_5_GoingDown";
VAL_ 547 LHZCUeSw17DiagSts 0 "LHZCUeSw17DiagSts_0_NoFault" 1 "LHZCUeSw17DiagSts_1_OCP" 2 "LHZCUeSw17DiagSts_2_OVP" 3 "LHZCUeSw17DiagSts_3_UVP" 4 "LHZCUeSw17DiagSts_4_OT" 5 "LHZCUeSw17DiagSts_5_SPI_Fault" 6 "LHZCUeSw17DiagSts_6_ChipFault" 7 "LHZCUeSw17DiagSts_7_OpenCircuit" 8 "LHZCUeSw17DiagSts_8_ShortToGND" 9 "LHZCUeSw17DiagSts_9_ShortToBattery" 10 "LHZCUeSw17DiagSts_10_OtherFault" 11 "LHZCUeSw17DiagSts_11_Drive_Mismatch";
VAL_ 547 LHZCUeSw16Sts 0 "LHZCUeSw16Sts_0_Unknown" 1 "LHZCUeSw16Sts_1_Off" 2 "LHZCUeSw16Sts_2_On" 3 "LHZCUeSw16Sts_3_LatchOn" 4 "LHZCUeSw16Sts_4_FailureOff" 5 "LHZCUeSw16Sts_5_GoingDown";
VAL_ 547 LHZCUeSw16DiagSts 0 "LHZCUeSw16DiagSts_0_NoFault" 1 "LHZCUeSw16DiagSts_1_OCP" 2 "LHZCUeSw16DiagSts_2_OVP" 3 "LHZCUeSw16DiagSts_3_UVP" 4 "LHZCUeSw16DiagSts_4_OT" 5 "LHZCUeSw16DiagSts_5_SPI_Fault" 6 "LHZCUeSw16DiagSts_6_ChipFault" 7 "LHZCUeSw16DiagSts_7_OpenCircuit" 8 "LHZCUeSw16DiagSts_8_ShortToGND" 9 "LHZCUeSw16DiagSts_9_ShortToBattery" 10 "LHZCUeSw16DiagSts_10_OtherFault" 11 "LHZCUeSw16DiagSts_11_Drive_Mismatch";
VAL_ 547 LHZCUeSw15Sts 0 "LHZCUeSw15Sts_0_Unknown" 1 "LHZCUeSw15Sts_1_Off" 2 "LHZCUeSw15Sts_2_On" 3 "LHZCUeSw15Sts_3_LatchOn" 4 "LHZCUeSw15Sts_4_FailureOff" 5 "LHZCUeSw15Sts_5_GoingDown";
VAL_ 547 LHZCUeSw15DiagSts 0 "LHZCUeSw15DiagSts_0_NoFault" 1 "LHZCUeSw15DiagSts_1_OCP" 2 "LHZCUeSw15DiagSts_2_OVP" 3 "LHZCUeSw15DiagSts_3_UVP" 4 "LHZCUeSw15DiagSts_4_OT" 5 "LHZCUeSw15DiagSts_5_SPI_Fault" 6 "LHZCUeSw15DiagSts_6_ChipFault" 7 "LHZCUeSw15DiagSts_7_OpenCircuit" 8 "LHZCUeSw15DiagSts_8_ShortToGND" 9 "LHZCUeSw15DiagSts_9_ShortToBattery" 10 "LHZCUeSw15DiagSts_10_OtherFault" 11 "LHZCUeSw15DiagSts_11_Drive_Mismatch";
VAL_ 547 LHZCUeSw14Sts 0 "LHZCUeSw14Sts_0_Unknown" 1 "LHZCUeSw14Sts_1_Off" 2 "LHZCUeSw14Sts_2_On" 3 "LHZCUeSw14Sts_3_LatchOn" 4 "LHZCUeSw14Sts_4_FailureOff" 5 "LHZCUeSw14Sts_5_GoingDown";
VAL_ 547 LHZCUeSw14DiagSts 0 "LHZCUeSw14DiagSts_0_NoFault" 1 "LHZCUeSw14DiagSts_1_OCP" 2 "LHZCUeSw14DiagSts_2_OVP" 3 "LHZCUeSw14DiagSts_3_UVP" 4 "LHZCUeSw14DiagSts_4_OT" 5 "LHZCUeSw14DiagSts_5_SPI_Fault" 6 "LHZCUeSw14DiagSts_6_ChipFault" 7 "LHZCUeSw14DiagSts_7_OpenCircuit" 8 "LHZCUeSw14DiagSts_8_ShortToGND" 9 "LHZCUeSw14DiagSts_9_ShortToBattery" 10 "LHZCUeSw14DiagSts_10_OtherFault" 11 "LHZCUeSw14DiagSts_11_Drive_Mismatch";
VAL_ 547 LHZCUeSw13Sts 0 "LHZCUeSw13Sts_0_Unknown" 1 "LHZCUeSw13Sts_1_Off" 2 "LHZCUeSw13Sts_2_On" 3 "LHZCUeSw13Sts_3_LatchOn" 4 "LHZCUeSw13Sts_4_FailureOff" 5 "LHZCUeSw13Sts_5_GoingDown";
VAL_ 547 LHZCUeSw13DiagSts 0 "LHZCUeSw13DiagSts_0_NoFault" 1 "LHZCUeSw13DiagSts_1_OCP" 2 "LHZCUeSw13DiagSts_2_OVP" 3 "LHZCUeSw13DiagSts_3_UVP" 4 "LHZCUeSw13DiagSts_4_OT" 5 "LHZCUeSw13DiagSts_5_SPI_Fault" 6 "LHZCUeSw13DiagSts_6_ChipFault" 7 "LHZCUeSw13DiagSts_7_OpenCircuit" 8 "LHZCUeSw13DiagSts_8_ShortToGND" 9 "LHZCUeSw13DiagSts_9_ShortToBattery" 10 "LHZCUeSw13DiagSts_10_OtherFault" 11 "LHZCUeSw13DiagSts_11_Drive_Mismatch";
VAL_ 547 LHZCUeSw12Sts 0 "LHZCUeSw12Sts_0_Unknown" 1 "LHZCUeSw12Sts_1_Off" 2 "LHZCUeSw12Sts_2_On" 3 "LHZCUeSw12Sts_3_LatchOn" 4 "LHZCUeSw12Sts_4_FailureOff" 5 "LHZCUeSw12Sts_5_GoingDown";
VAL_ 547 LHZCUeSw12DiagSts 0 "LHZCUeSw12DiagSts_0_NoFault" 1 "LHZCUeSw12DiagSts_1_OCP" 2 "LHZCUeSw12DiagSts_2_OVP" 3 "LHZCUeSw12DiagSts_3_UVP" 4 "LHZCUeSw12DiagSts_4_OT" 5 "LHZCUeSw12DiagSts_5_SPI_Fault" 6 "LHZCUeSw12DiagSts_6_ChipFault" 7 "LHZCUeSw12DiagSts_7_OpenCircuit" 8 "LHZCUeSw12DiagSts_8_ShortToGND" 9 "LHZCUeSw12DiagSts_9_ShortToBattery" 10 "LHZCUeSw12DiagSts_10_OtherFault" 11 "LHZCUeSw12DiagSts_11_Drive_Mismatch";
VAL_ 547 LHZCUeFs13Sts 0 "LHZCUeFs13Sts_0_Unknown" 1 "LHZCUeFs13Sts_1_Off" 2 "LHZCUeFs13Sts_2_On" 3 "LHZCUeFs13Sts_3_LatchOn" 4 "LHZCUeFs13Sts_4_FailureOff" 5 "LHZCUeFs13Sts_5_GoingDown";
VAL_ 547 LHZCUeFs13DiagSts 0 "LHZCUeFs13DiagSts_0_NoFault" 1 "LHZCUeFs13DiagSts_1_OCP" 2 "LHZCUeFs13DiagSts_2_OVP" 3 "LHZCUeFs13DiagSts_3_UVP" 4 "LHZCUeFs13DiagSts_4_OT" 5 "LHZCUeFs13DiagSts_5_SPI_Fault" 6 "LHZCUeFs13DiagSts_6_ChipFault" 7 "LHZCUeFs13DiagSts_7_OpenCircuit" 8 "LHZCUeFs13DiagSts_8_ShortToGND" 9 "LHZCUeFs13DiagSts_9_ShortToBattery" 10 "LHZCUeFs13DiagSts_10_OtherFault" 11 "LHZCUeFs13DiagSts_11_Drive_Mismatch";
VAL_ 994 RFCTWrnng_ADAS 0 "RFCTWrnng_ADAS_0_no_warning" 1 "RFCTWrnng_ADAS_1_RFCTAWrnng_level_1" 2 "RFCTWrnng_ADAS_2_RFCTAWrnng_level_2" 3 "RFCTWrnng_ADAS_3_RFCTBActive_Active" 4 "RFCTWrnng_ADAS_4_Reserved" 5 "RFCTWrnng_ADAS_5_Reserved" 6 "RFCTWrnng_ADAS_6_Reserved";
VAL_ 994 FCTBSysFltSts_ADAS 0 "FCTBSysFltSts_ADAS_0_No_Error" 1 "FCTBSysFltSts_ADAS_1_System_Temporary_Unvailable" 2 "FCTBSysFltSts_ADAS_2_Service_Required" 3 "FCTBSysFltSts_ADAS_3_Reserved";
VAL_ 994 FCTSysFltSts_ADAS 0 "FCTSysFltSts_ADAS_0_No_Error" 1 "FCTSysFltSts_ADAS_1_System_Temporary_Unvailable" 2 "FCTSysFltSts_ADAS_2_Service_Required" 3 "FCTSysFltSts_ADAS_3_Reserved";
VAL_ 994 FCTSwSts_ADAS 0 "FCTSwSts_ADAS_0_unavaliable" 1 "FCTSwSts_ADAS_1_FCTA_off" 2 "FCTSwSts_ADAS_2_FCTA_on" 3 "FCTSwSts_ADAS_3_FCTB__FCTA__on" 4 "FCTSwSts_ADAS_4_Reserved" 5 "FCTSwSts_ADAS_5_Reserved" 6 "FCTSwSts_ADAS_6_Reserved" 7 "FCTSwSts_ADAS_7_Reserved";
VAL_ 994 LFCTWrnng_ADAS 0 "LFCTWrnng_ADAS_0_no_warning" 1 "LFCTWrnng_ADAS_1_LFCTAWrnng_level_1" 2 "LFCTWrnng_ADAS_2_LFCTAWrnng_level_2" 3 "LFCTWrnng_ADAS_3_LFCTBActive_Active" 4 "LFCTWrnng_ADAS_4_Reserved" 5 "LFCTWrnng_ADAS_5_Reserved" 6 "LFCTWrnng_ADAS_6_Reserved";
VAL_ 484 AEBDclReqSts_ADAS 0 "AEBDclReqSts_0_NoRequest" 1 "AEBDclReqSts_1_AebDecelerationRequest";
VAL_ 1230 RFSDA_NM_BSMtoRMS_BKPCANFD 0 "RFSDA_NM_BSMtoRMS_BKPCANFD_0_RFSDA_NM_BSMtoRMS_0_False" 1 "RFSDA_NM_BSMtoRMS_BKPCANFD_1_RFSDA_NM_BSMtoRMS_1_True";
VAL_ 1230 RFSDA_NM_PBSMtoRMS_BKPCANFD 0 "RFSDA_NM_PBSMtoRMS_BKPCANFD_0_RFSDA_NM_PBSMtoRMS_0_False" 1 "RFSDA_NM_PBSMtoRMS_BKPCANFD_1_RFSDA_NM_PBSMtoRMS_1_True";
VAL_ 1230 RFSDA_NM_RMStoNOS_BKPCANFD 0 "RFSDA_NM_RMStoNOS_BKPCANFD_0_RFSDA_NM_RMStoNOS_0_False" 1 "RFSDA_NM_RMStoNOS_BKPCANFD_1_RFSDA_NM_RMStoNOS_1_True";
VAL_ 1230 RFSDA_NM_RSStoNOS_BKPCANFD 0 "RFSDA_NM_RSStoNOS_BKPCANFD_0_RFSDA_NM_RSStoNOS_0_False" 1 "RFSDA_NM_RSStoNOS_BKPCANFD_1_RFSDA_NM_RSStoNOS_1_True";
VAL_ 1230 RFSDA_NM_RSStoRMS_BKPCANFD 0 "RFSDA_NM_RSStoRMS_BKPCANFD_0_RFSDA_NM_RSStoRMS_0_False" 1 "RFSDA_NM_RSStoRMS_BKPCANFD_1_RFSDA_NM_RSStoRMS_1_True";
VAL_ 1230 RFSDA_NM_NOStoRMS_BKPCANFD 0 "RFSDA_NM_NOStoRMS_BKPCANFD_0_RFSDA_NM_NOStoRMS_0_False" 1 "RFSDA_NM_NOStoRMS_BKPCANFD_1_RFSDA_NM_NOStoRMS_1_True";
VAL_ 1230 RFSDA_NM_NOSSta_BKPCANFD 0 "RFSDA_NM_NOSSta_BKPCANFD_0_RFSDA_NM_NOSSta_0_False" 1 "RFSDA_NM_NOSSta_BKPCANFD_1_RFSDA_NM_NOSSta_1_True";
VAL_ 1230 RFSDA_NM_RMSSta_BKPCANFD 0 "RFSDA_NM_RMSSta_BKPCANFD_0_RFSDA_NM_RMSSta_0_False" 1 "RFSDA_NM_RMSSta_BKPCANFD_1_RFSDA_NM_RMSSta_1_True";
VAL_ 1230 RFSDA_NWI_BKPCANFD 0 "RFSDA_NWI_BKPCANFD_0_NoWakeNetworkSource" 1 "RFSDA_NWI_BKPCANFD_1_PowerModeIsNonOFF" 2 "RFSDA_NWI_BKPCANFD_2_OnboardChargerConnected";
VAL_ 1230 RFSDA_NOI_BKPCANFD 0 "RFSDA_NOI_BKPCANFD_0_NoRequest" 65535 "RFSDA_NOI_BKPCANFD_65535_AllNetworkOperationActive";
VAL_ 1230 RFSDA_NKI_BKPCANFD 0 "RFSDA_NKI_BKPCANFD_0_NoRequest" 1 "RFSDA_NKI_BKPCANFD_1_PowerModeIsNonOFF" 2 "RFSDA_NKI_BKPCANFD_2_DOW" 3 "RFSDA_NKI_BKPCANFD_3_RPA";
VAL_ 725 RDOWWrnng 0 "RDOWWrnng_0_no_warning" 1 "RDOWWrnng_1_warning_level_1" 2 "RDOWWrnng_2_warning_level_2" 3 "RDOWWrnng_3_Reserved";
VAL_ 725 LDOWWrnng 0 "LDOWWrnng_0_no_warning" 1 "LDOWWrnng_1_warning_level_1" 2 "LDOWWrnng_2_warning_level_2" 3 "LDOWWrnng_3_Reserved";
VAL_ 725 RDASysSta 1 "RDASysSta_1_Reserved" 2 "RDASysSta_2_System_Temporary_unavailability" 3 "RDASysSta_3_SensorBlockage" 4 "RDASysSta_4_Disabled_Off" 5 "RDASysSta_5_Enabled_On" 6 "RDASysSta_6_SystemError";
VAL_ 725 RBSDAndLCAWrnng 0 "RBSDAndLCAWrnng_0_no_warning" 1 "RBSDAndLCAWrnng_1_warning_level_1" 2 "RBSDAndLCAWrnng_2_warning_level_2" 3 "RBSDAndLCAWrnng_3_Reserved";
VAL_ 725 LBSDAndLCAWrnng 0 "LBSDAndLCAWrnng_0_no_warning" 1 "LBSDAndLCAWrnng_1_warning_level_1" 2 "LBSDAndLCAWrnng_2_warning_level_2" 3 "LBSDAndLCAWrnng_3_Reserved";
VAL_ 725 DOWSelSts 0 "DOWSelSts_0_On" 1 "DOWSelSts_1_Off" 2 "DOWSelSts_2_disable" 3 "DOWSelSts_3_reserved";
VAL_ 725 RDASwSts 0 "RDASwSts_0_On" 1 "RDASwSts_1_Off" 2 "RDASwSts_2_disable" 3 "RDASwSts_3_reserved";
VAL_ 725 LCASelSts 0 "LCASelSts_0_On" 1 "LCASelSts_1_Off" 2 "LCASelSts_2_disable" 3 "LCASelSts_3_reserved";
VAL_ 725 RRCTAWrnng 0 "RRCTAWrnng_0_no_warning" 1 "RRCTAWrnng_1_warning_level_1" 2 "RRCTAWrnng_2_warning_level_2" 3 "RRCTAWrnng_3_Reserved";
VAL_ 725 RCTSysSelSts 0 "RCTSysSelStsIPD_0_RCTA_On" 1 "RCTSysSelStsIPD_1_RCTA_RCTB_off" 2 "RCTSysSelStsIPD_2_disable" 3 "RCTSysSelStsIPD_3_RCTB_RCTA_On";
VAL_ 725 LRCTAWrnng 0 "LRCTAWrnng_0_no_warning" 1 "LRCTAWrnng_1_warning_level_1" 2 "LRCTAWrnng_2_warning_level_2" 3 "LRCTAWrnng_3_Reserved";
VAL_ 725 RRRdrEmgcLineChngWrnng 0 "RRRdrEmgcLineChngWrnng_0_Invalid" 1 "RRRdrEmgcLineChngWrnng_1_No_Waring" 2 "RRRdrEmgcLineChngWrnng_2_Waring";
VAL_ 725 RrCrnRdrCalSts 0 "RrCrnRdrCalSts_0_No_Request" 1 "RrCrnRdrCalSts_1_Calibration_Started" 2 "RrCrnRdrCalSts_2_Calibration_in_progress" 3 "RrCrnRdrCalSts_3_Calibration_Finished_Succesful" 4 "RrCrnRdrCalSts_4_Calibration_Finished_need_Adjust" 5 "RrCrnRdrCalSts_5_calibration_failure" 6 "RrCrnRdrCalSts_6_reserve" 7 "RrCrnRdrCalSts_7_reserve";
VAL_ 725 BSDSelSts 0 "BSDSelSts_0_On" 1 "BSDSelSts_1_Off" 2 "BSDSelSts_2_disable" 3 "BSDSelSts_3_reserved";
VAL_ 725 RLRdrEmgcLineChngWrnng 0 "RLRdrEmgcLineChngWrnng_0_Invalid" 1 "RLRdrEmgcLineChngWrnng_1_No_Waring" 2 "RLRdrEmgcLineChngWrnng_2_Waring";
VAL_ 1228 RHRDA_NM_BSMtoRMS_BKPCANFD 0 "RHRDA_NM_BSMtoRMS_BKPCANFD_0_False" 1 "RHRDA_NM_BSMtoRMS_BKPCANFD_1_True";
VAL_ 1228 RHRDA_NM_PBSMtoRMS_BKPCANFD 0 "RHRDA_NM_PBSMtoRMS_BKPCANFD_0_False" 1 "RHRDA_NM_PBSMtoRMS_BKPCANFD_1_True";
VAL_ 1228 RHRDA_NM_RMStoNOS_BKPCANFD 0 "RHRDA_NM_RMStoNOS_BKPCANFD_0_False" 1 "RHRDA_NM_RMStoNOS_BKPCANFD_1_True";
VAL_ 1228 RHRDA_NM_RSStoNOS_BKPCANFD 0 "RHRDA_NM_RSStoNOS_BKPCANFD_0_False" 1 "RHRDA_NM_RSStoNOS_BKPCANFD_1_True";
VAL_ 1228 RHRDA_NM_RSStoRMS_BKPCANFD 0 "RHRDA_NM_RSStoRMS_BKPCANFD_0_False" 1 "RHRDA_NM_RSStoRMS_BKPCANFD_1_True";
VAL_ 1228 RHRDA_NM_NOStoRMS_BKPCANFD 0 "RHRDA_NM_NOStoRMS_BKPCANFD_0_False" 1 "RHRDA_NM_NOStoRMS_BKPCANFD_1_True";
VAL_ 1228 RHRDA_NM_NOSSta_BKPCANFD 0 "RHRDA_NM_NOSSta_BKPCANFD_0_False" 1 "RHRDA_NM_NOSSta_BKPCANFD_1_True";
VAL_ 1228 RHRDA_NM_RMSSta_BKPCANFD 0 "RHRDA_NM_RMSSta_BKPCANFD_0_False" 1 "RHRDA_NM_RMSSta_BKPCANFD_1_True";
VAL_ 1228 RHRDA_NWI_BKPCANFD 0 "RHRDA_NWI_BKPCANFD_0_NoWakeNetworkSource";
VAL_ 1228 RHRDA_NOI_BKPCANFD 0 "RHRDA_NOI_BKPCANFD_0_NoRequest" 65535 "RHRDA_NOI_BKPCANFD_65535_AllNetworkOperationActive";
VAL_ 1228 RHRDA_NKI_BKPCANFD 0 "RHRDA_NKI_BKPCANFD_0_NoRequest";
VAL_ 936 FrtCamrHeatSts 0 "FrtCamrHeatSts_0_OFF" 1 "FrtCamrHeatSts_1_ON" 2 "FrtCamrHeatSts_2_Notused" 3 "FrtCamrHeatSts_3_Error";
VAL_ 936 FrSsdLrngFailRrsn 0 "FrSsdLrngFailRrsn_0_No_Fail" 1 "FrSsdLrngFailRrsn_1_Motor_drive_fault" 2 "FrSsdLrngFailRrsn_2_Hall_fault" 3 "FrSsdLrngFailRrsn_3_Hall_number_anomaly" 4 "FrSsdLrngFailRrsn_4_Abnormal_voltage_fault" 5 "FrSsdLrngFailRrsn_5_Other_fault";
VAL_ 544 RHZCUeSw37Sts 0 "RHZCUeSw37Sts_0_Unknown" 1 "RHZCUeSw37Sts_1_Off" 2 "RHZCUeSw37Sts_2_On" 3 "RHZCUeSw37Sts_3_LatchOn" 4 "RHZCUeSw37Sts_4_Failure" 5 "RHZCUeSw37Sts_5_GoingDown";
VAL_ 544 RHZCUeSw37DiagSts 0 "RHZCUeSw37DiagSts_0_NoFault" 1 "RHZCUeSw37DiagSts_1_OCP" 2 "RHZCUeSw37DiagSts_2_OVP" 3 "RHZCUeSw37DiagSts_3_UVP" 4 "RHZCUeSw37DiagSts_4_OT" 5 "RHZCUeSw37DiagSts_5_SPI_Fault" 6 "RHZCUeSw37DiagSts_6_ChipFault" 7 "RHZCUeSw37DiagSts_7_OpenCircuit" 8 "RHZCUeSw37DiagSts_8_ShortToGND" 9 "RHZCUeSw37DiagSts_9_ShortToBattery" 10 "RHZCUeSw37DiagSts_10_OtherFault" 11 "RHZCUeSw37DiagSts_11_Drive_Mismatch";
VAL_ 544 RHZCUeSw3Sts 0 "RHZCUeSw3Sts_0_Unknown" 1 "RHZCUeSw3Sts_1_Off" 2 "RHZCUeSw3Sts_2_On" 3 "RHZCUeSw3Sts_3_LatchOn" 4 "RHZCUeSw3Sts_4_Failure" 5 "RHZCUeSw3Sts_5_GoingDown";
VAL_ 544 RHZCUeSw3DiagSts 0 "RHZCUeSw3DiagSts_0_NoFault" 1 "RHZCUeSw3DiagSts_1_OCP" 2 "RHZCUeSw3DiagSts_2_OVP" 3 "RHZCUeSw3DiagSts_3_UVP" 4 "RHZCUeSw3DiagSts_4_OT" 5 "RHZCUeSw3DiagSts_5_SPI_Fault" 6 "RHZCUeSw3DiagSts_6_ChipFault" 7 "RHZCUeSw3DiagSts_7_OpenCircuit" 8 "RHZCUeSw3DiagSts_8_ShortToGND" 9 "RHZCUeSw3DiagSts_9_ShortToBattery" 10 "RHZCUeSw3DiagSts_10_OtherFault" 11 "RHZCUeSw3DiagSts_11_Drive_Mismatch";
VAL_ 544 RHZCUeSw9Sts 0 "RHZCUeSw9Sts_0_Unknown" 1 "RHZCUeSw9Sts_1_Off" 2 "RHZCUeSw9Sts_2_On" 3 "RHZCUeSw9Sts_3_LatchOn" 4 "RHZCUeSw9Sts_4_Failure" 5 "RHZCUeSw9Sts_5_GoingDown";
VAL_ 544 RHZCUeSw9DiagSts 0 "RHZCUeSw9DiagSts_0_NoFault" 1 "RHZCUeSw9DiagSts_1_OCP" 2 "RHZCUeSw9DiagSts_2_OVP" 3 "RHZCUeSw9DiagSts_3_UVP" 4 "RHZCUeSw9DiagSts_4_OT" 5 "RHZCUeSw9DiagSts_5_SPI_Fault" 6 "RHZCUeSw9DiagSts_6_ChipFault" 7 "RHZCUeSw9DiagSts_7_OpenCircuit" 8 "RHZCUeSw9DiagSts_8_ShortToGND" 9 "RHZCUeSw9DiagSts_9_ShortToBattery" 10 "RHZCUeSw9DiagSts_10_OtherFault" 11 "RHZCUeSw9DiagSts_11_Drive_Mismatch";
VAL_ 544 RHZCUeSw33Sts 0 "RHZCUeSw33Sts_0_Unknown" 1 "RHZCUeSw33Sts_1_Off" 2 "RHZCUeSw33Sts_2_On" 3 "RHZCUeSw33Sts_3_LatchOn" 4 "RHZCUeSw33Sts_4_Failure" 5 "RHZCUeSw33Sts_5_GoingDown";
VAL_ 544 RHZCUeSw33DiagSts 0 "RHZCUeSw33DiagSts_0_NoFault" 1 "RHZCUeSw33DiagSts_1_OCP" 2 "RHZCUeSw33DiagSts_2_OVP" 3 "RHZCUeSw33DiagSts_3_UVP" 4 "RHZCUeSw33DiagSts_4_OT" 5 "RHZCUeSw33DiagSts_5_SPI_Fault" 6 "RHZCUeSw33DiagSts_6_ChipFault" 7 "RHZCUeSw33DiagSts_7_OpenCircuit" 8 "RHZCUeSw33DiagSts_8_ShortToGND" 9 "RHZCUeSw33DiagSts_9_ShortToBattery" 10 "RHZCUeSw33DiagSts_10_OtherFault" 11 "RHZCUeSw33DiagSts_11_Drive_Mismatch";
VAL_ 544 RHZCUeSw42Sts 0 "RHZCUeSw42Sts_0_Unknown" 1 "RHZCUeSw42Sts_1_Off" 2 "RHZCUeSw42Sts_2_On" 3 "RHZCUeSw42Sts_3_LatchOn" 4 "RHZCUeSw42Sts_4_Failure" 5 "RHZCUeSw42Sts_5_GoingDown";
VAL_ 544 RHZCUeSw42DiagSts 0 "RHZCUeSw42DiagSts_0_NoFault" 1 "RHZCUeSw42DiagSts_1_OCP" 2 "RHZCUeSw42DiagSts_2_OVP" 3 "RHZCUeSw42DiagSts_3_UVP" 4 "RHZCUeSw42DiagSts_4_OT" 5 "RHZCUeSw42DiagSts_5_SPI_Fault" 6 "RHZCUeSw42DiagSts_6_ChipFault" 7 "RHZCUeSw42DiagSts_7_OpenCircuit" 8 "RHZCUeSw42DiagSts_8_ShortToGND" 9 "RHZCUeSw42DiagSts_9_ShortToBattery" 10 "RHZCUeSw42DiagSts_10_OtherFault" 11 "RHZCUeSw42DiagSts_11_Drive_Mismatch";
VAL_ 544 RHZCUeSw43Sts 0 "RHZCUeSw43Sts_0_Unknown" 1 "RHZCUeSw43Sts_1_Off" 2 "RHZCUeSw43Sts_2_On" 3 "RHZCUeSw43Sts_3_LatchOn" 4 "RHZCUeSw43Sts_4_Failure" 5 "RHZCUeSw43Sts_5_GoingDown";
VAL_ 544 RHZCUeSw43DiagSts 0 "RHZCUeSw43DiagSts_0_NoFault" 1 "RHZCUeSw43DiagSts_1_OCP" 2 "RHZCUeSw43DiagSts_2_OVP" 3 "RHZCUeSw43DiagSts_3_UVP" 4 "RHZCUeSw43DiagSts_4_OT" 5 "RHZCUeSw43DiagSts_5_SPI_Fault" 6 "RHZCUeSw43DiagSts_6_ChipFault" 7 "RHZCUeSw43DiagSts_7_OpenCircuit" 8 "RHZCUeSw43DiagSts_8_ShortToGND" 9 "RHZCUeSw43DiagSts_9_ShortToBattery" 10 "RHZCUeSw43DiagSts_10_OtherFault" 11 "RHZCUeSw43DiagSts_11_Drive_Mismatch";
VAL_ 514 RDipdBeamLghtSts 0 "RDipdBeamLghtSts_0_Off" 1 "RDipdBeamLghtSts_1_On" 2 "RDipdBeamLghtSts_2_Error" 3 "RDipdBeamLghtSts_3_Unknow";
VAL_ 514 RRSuperLckSts 0 "RRSuperLckSts_0_Lock" 1 "RRSuperLckSts_1_Unlock" 2 "RRSuperLckSts_2_Error";
VAL_ 514 FRSuperLckSts 0 "FRSuperLckSts_0_Lock" 1 "FRSuperLckSts_1_Unlock" 2 "FRSuperLckSts_2_Error";
VAL_ 514 FRDSP_RLWinSwtSts 0 "RLWinDrvrSwtSts__0_no_request" 1 "RLWinDrvrSwtSts__1_up_request" 2 "RLWinDrvrSwtSts__2_down_request" 3 "RLWinDrvrSwtSts__3_auto_up_request" 4 "RLWinDrvrSwtSts__4_auto_down_request";
VAL_ 514 FRDSP_FLWinSwtSts 0 "FRWinDrvrSwtSts__0_no_request" 1 "FRWinDrvrSwtSts__1_up_request" 2 "FRWinDrvrSwtSts__2_down_request" 3 "FRWinDrvrSwtSts__3_auto_up_request" 4 "FRWinDrvrSwtSts__4_auto_down_request";
VAL_ 514 FRDircnLghtSts 0 "FRDircnLghtSts_0_Off" 1 "FRDircnLghtSts_1_On";
VAL_ 514 RMainBeamLghtSts 0 "RMainBeamLghtSts_0_Off" 1 "RMainBeamLghtSts_1_On";
VAL_ 514 FRDSP_RRWinSwtSts 0 "RRWinDrvrSwtSts__0_no_request" 1 "RRWinDrvrSwtSts__1_up_request" 2 "RRWinDrvrSwtSts__2_down_request" 3 "RRWinDrvrSwtSts__3_auto_up_request" 4 "RRWinDrvrSwtSts__4_auto_down_request";
VAL_ 829 ACAmbtTemV 0 "ACAmbtTemV_0_Valid" 1 "ACAmbtTemV_1_Invalid";
VAL_ 829 ACAmbtTemMsk 0 "ACAmbtTemMsk_0_Dont_Use_Data" 1 "ACAmbtTemMsk_1_Use_Data";
VAL_ 829 FRSeatHorzPos 254 "FRSeatHorzPos_254_Stop" 255 "FRSeatHorzPos_255_Invalid";
VAL_ 829 FRSeatVertPos 254 "FRSeatVertPos_254_Stop" 255 "FRSeatVertPos_255_Invalid";
VAL_ 857 ACLAirMdDspCmd 0 "ACLAirMdDspCmd_0_face" 1 "ACLAirMdDspCmd_1_face_foot" 2 "ACLAirMdDspCmd_2_foot" 3 "ACLAirMdDspCmd_3_foot_defrost" 4 "ACLAirMdDspCmd_4_defrost" 5 "ACLAirMdDspCmd_5_face_foot_defrost" 6 "ACLAirMdDspCmd_6_face_defrost" 7 "ACLAirMdDspCmd_7_auto_air_distribute_mode";
VAL_ 857 FrSsdMotVolErrSts 0 "FrSsdMotVolErrSts_0_False" 1 "FrSsdMotVolErrSts_1_True";
VAL_ 857 FrSsdMotThrmlProtnSts 0 "FrSsdMotThrmlProtnSts_0_False" 1 "FrSsdMotThrmlProtnSts_1_True";
VAL_ 857 FrSsdMotSledSts 0 "FrSsdMotSledSts_0_False" 1 "FrSsdMotSledSts_1_True";
VAL_ 857 FrSsdHallErrSts 0 "FrSsdHallErrSts_0_False" 1 "FrSsdHallErrSts_1_True";
VAL_ 857 FrSsdInitSts 0 "FrSsdInitSts_0_Normal" 1 "FrSsdInitSts_1_Error";
VAL_ 857 ACFrtBlwrSpdDspCmd 0 "ACFrtBlwrSpdDspCmd_0_Blower_Off" 1 "ACFrtBlwrSpdDspCmd_1_blower_level_1" 2 "ACFrtBlwrSpdDspCmd_2_blower_level_2" 3 "ACFrtBlwrSpdDspCmd_3_blower_level_3" 4 "ACFrtBlwrSpdDspCmd_4_blower_level_4" 5 "ACFrtBlwrSpdDspCmd_5_blower_level_5" 6 "ACFrtBlwrSpdDspCmd_6_blower_level_6" 7 "ACFrtBlwrSpdDspCmd_7_blower_level_7" 8 "ACFrtBlwrSpdDspCmd_8_blower_level_8" 9 "ACFrtBlwrSpdDspCmd_9_blower_level_9" 10 "ACFrtBlwrSpdDspCmd_10_blower_level_10" 11 "ACFrtBlwrSpdDspCmd_11_blower_level_11" 12 "ACFrtBlwrSpdDspCmd_12_blower_level_12" 13 "ACFrtBlwrSpdDspCmd_13_blower_level_13" 14 "ACFrtBlwrSpdDspCmd_14_blower_level_14" 15 "ACFrtBlwrSpdDspCmd_15_auto_blower_level";
VAL_ 857 DfstOnDspCmd 0 "DfstOnDspCmd_0_False" 1 "DfstOnDspCmd_1_True";
VAL_ 857 ACOnOffDspCmd 0 "ACOnOffDspCmd_0_OFF" 1 "ACOnOffDspCmd_1_ON";
VAL_ 857 ACAutoDspCmd 0 "ACAutoDspCmd_0_False" 1 "ACAutoDspCmd_1_True";
VAL_ 857 FrSsdMotRlyFltSts 0 "FrSsdMotRlyFltSts_0_False" 1 "FrSsdMotRlyFltSts_1_True";
VAL_ 857 FrSsdAntiPnchSts 0 "FrSsdAntiPnchSts_0_False" 1 "FrSsdAntiPnchSts_1_True";
VAL_ 857 FrSsdLrngSts 0 "FrSsdLrngSts__0__Not_learning" 1 "FrSsdLrngSts__1__Learning_successful" 2 "FrSsdLrngSts__2__Learning_failure" 3 "FrSsdLrngSts__3__Refuse_learning_MoreThanmax_time" 4 "FrSsdLrngSts__4__In_learning" 5 "FrSsdLrngSts__5__Learning_status_unknown";
VAL_ 857 FrSsdMovSts 0 "FrSsdMovSts_0_Unknown" 1 "FrSsdMovSts_1_Stop" 2 "FrSsdMovSts_2_MannulOpening" 3 "FrSsdMovSts_3_MannulClosing" 4 "FrSsdMovSts_4_AutoOpenig" 5 "FrSsdMovSts_5_AutoClosing" 6 "FrSsdMovSts_6_Anti_Pinch_Reversing";
VAL_ 943 FRDoorOpenSts 0 "FRDoorOpenSts_0_Closed" 1 "FRDoorOpenSts_1_CantDetectDoorAjarStatus" 2 "FRDoorOpenSts_2_Ajar" 3 "FRDoorOpenSts_3_Open";
VAL_ 943 RRWinShrtDwnSucd 0 "RRWinShrtDwnSucd_0_failed" 1 "RRWinShrtDwnSucd_1_succeed";
VAL_ 943 ROtsdMirFoldSts 0 "ROtsdMirFoldSts_0_Initial" 1 "ROtsdMirFoldSts_1_Folded" 2 "ROtsdMirFoldSts_2_Unfolded" 3 "ROtsdMirFoldSts_3_Folding" 4 "ROtsdMirFoldSts_4_Unfolding" 5 "ROtsdMirFoldSts_5_Failure";
VAL_ 943 RRWinMotSts 0 "RRWinMotSts_0_still" 1 "RRWinMotSts_1_up" 2 "RRWinMotSts_2_down" 3 "RRWinMotSts_3_auto_up" 4 "RRWinMotSts_4_auto_down" 5 "RRWinMotSts_5_aeration" 6 "RRWinMotSts_6_frameless_short_drive_up" 7 "RRWinMotSts_7_frameless_short_drive_down" 8 "RRWinMotSts_8_Anti_pinch_auto_reverse" 9 "RRWinMotSts_9_Stall" 10 "RRWinMotSts_10_Anti_pinch_Override" 11 "RRWinMotSts_11_AutoriseAtDoorOpen";
VAL_ 943 FRWinShrtDwnSucd 0 "FRWinShrtDwnSucd_0_failed" 1 "FRWinShrtDwnSucd_1_succeed";
VAL_ 943 RRWinLclSwtFlt 0 "RRWinLclSwtFlt_0_no_error" 1 "RRWinLclSwtFlt_1_error";
VAL_ 943 RRWinLclSwtSts 0 "RRWinLclSwtSts_0_no_request" 1 "RRWinLclSwtSts_1_up_request" 2 "RRWinLclSwtSts_2_down_request" 3 "RRWinLclSwtSts_3_auto_up_request" 4 "RRWinLclSwtSts_4_auto_down_request";
VAL_ 943 RRWinIninSts 0 "RRWinIninSts_0_initialized" 1 "RRWinIninSts_1_not_initialized";
VAL_ 943 FRWinIninSts 0 "FRWinIninSts_0_initialized" 1 "FRWinIninSts_1_not_initialized";
VAL_ 649 RRDoorOpenSts 0 "RRDoorOpenSts_0_Closed" 1 "RRDoorOpenSts_1_CantDetectDoorAjarStatus" 2 "RRDoorOpenSts_2_Ajar" 3 "RRDoorOpenSts_3_Open";
VAL_ 649 RHZCUeSw41DiagSts 0 "RHZCUeSw41DiagSts_0_NoFault" 1 "RHZCUeSw41DiagSts_1_OCP" 2 "RHZCUeSw41DiagSts_2_OVP" 3 "RHZCUeSw41DiagSts_3_UVP" 4 "RHZCUeSw41DiagSts_4_OT" 5 "RHZCUeSw41DiagSts_5_SPI_Fault" 6 "RHZCUeSw41DiagSts_6_ChipFault" 7 "RHZCUeSw41DiagSts_7_OpenCircuit" 8 "RHZCUeSw41DiagSts_8_ShortToGND" 9 "RHZCUeSw41DiagSts_9_ShortToBattery" 10 "RHZCUeSw41DiagSts_10_OtherFault" 11 "RHZCUeSw41DiagSts_11_Drive_Mismatch";
VAL_ 649 RHZCUeSw41Sts 0 "RHZCUeSw41Sts_0_Unknown" 1 "RHZCUeSw41Sts_1_Off" 2 "RHZCUeSw41Sts_2_On" 3 "RHZCUeSw41Sts_3_LatchOn" 4 "RHZCUeSw41Sts_4_Failure" 5 "RHZCUeSw41Sts_5_GoingDown";
VAL_ 940 RHZCUeSw14Sts 0 "RHZCUeSw14Sts_0_Unknown" 1 "RHZCUeSw14Sts_1_Off" 2 "RHZCUeSw14Sts_2_On" 3 "RHZCUeSw14Sts_3_LatchOn" 4 "RHZCUeSw14Sts_4_FailureOff" 5 "RHZCUeSw14Sts_5_GoingDown";
VAL_ 940 RHZCUeSw14DiagSts 0 "RHZCUeSw14DiagSts_0_NoFault" 1 "RHZCUeSw14DiagSts_1_OCP" 2 "RHZCUeSw14DiagSts_2_OVP" 3 "RHZCUeSw14DiagSts_3_UVP" 4 "RHZCUeSw14DiagSts_4_OT" 5 "RHZCUeSw14DiagSts_5_SPI_Fault" 6 "RHZCUeSw14DiagSts_6_ChipFault" 7 "RHZCUeSw14DiagSts_7_OpenCircuit" 8 "RHZCUeSw14DiagSts_8_ShortToGND" 9 "RHZCUeSw14DiagSts_9_ShortToBattery" 10 "RHZCUeSw14DiagSts_10_OtherFault" 11 "RHZCUeSw14DiagSts_11_Drive_Mismatch";
VAL_ 940 RHZCUeSw31Sts 0 "RHZCUeSw31Sts_0_Unknown" 1 "RHZCUeSw31Sts_1_Off" 2 "RHZCUeSw31Sts_2_On" 3 "RHZCUeSw31Sts_3_LatchOn" 4 "RHZCUeSw31Sts_4_Failure" 5 "RHZCUeSw31Sts_5_GoingDown";
VAL_ 940 RHZCUeSw31DiagSts 0 "RHZCUeSw31DiagSts_0_NoFault" 1 "RHZCUeSw31DiagSts_1_OCP" 2 "RHZCUeSw31DiagSts_2_OVP" 3 "RHZCUeSw31DiagSts_3_UVP" 4 "RHZCUeSw31DiagSts_4_OT" 5 "RHZCUeSw31DiagSts_5_SPI_Fault" 6 "RHZCUeSw31DiagSts_6_ChipFault" 7 "RHZCUeSw31DiagSts_7_OpenCircuit" 8 "RHZCUeSw31DiagSts_8_ShortToGND" 9 "RHZCUeSw31DiagSts_9_ShortToBattery" 10 "RHZCUeSw31DiagSts_10_OtherFault" 11 "RHZCUeSw31DiagSts_11_Drive_Mismatch";
VAL_ 940 RHZCUIgnSts 0 "RHZCUIgnSts_0_Unknown" 1 "RHZCUIgnSts_1_Off" 2 "RHZCUIgnSts_2_On" 3 "RHZCUIgnSts_3_LatchOn" 4 "RHZCUIgnSts_4_FailureOff" 5 "RHZCUIgnSts_5_Reserve";
VAL_ 940 RHZCUIgnDiagSts 0 "RHZCUIgnDiagSts_0_NoFault" 1 "RHZCUIgnDiagSts_1_OCP" 2 "RHZCUIgnDiagSts_2_OVP" 3 "RHZCUIgnDiagSts_3_UVP" 4 "RHZCUIgnDiagSts_4_OT" 5 "RHZCUIgnDiagSts_5_SPI_Fault" 6 "RHZCUIgnDiagSts_6_ChipFault" 7 "RHZCUIgnDiagSts_7_OpenCircuit" 8 "RHZCUIgnDiagSts_8_ShortToGND" 9 "RHZCUIgnDiagSts_9_ShortToBattery" 10 "RHZCUIgnDiagSts_10_OtherFault" 11 "RHZCUignDiagSts_11_Drive_Mismatch";
VAL_ 940 RHZCUeFs3Sts 0 "RHZCUeFs3Sts_0_Unknown" 1 "RHZCUeFs3Sts_1_Off" 2 "RHZCUeFs3Sts_2_On" 3 "RHZCUeFs3Sts_3_LatchOn" 4 "RHZCUeFs3Sts_4_FailureOff" 5 "RHZCUeFs3Sts_5_GoingDown";
VAL_ 940 RHZCUeFs3DiagSts 0 "RHZCUeFs3DiagSts_0_NoFault" 1 "RHZCUeFs3DiagSts_1_OCP" 2 "RHZCUeFs3DiagSts_2_OVP" 3 "RHZCUeFs3DiagSts_3_UVP" 4 "RHZCUeFs3DiagSts_4_OT" 5 "RHZCUeFs3DiagSts_5_SPI_Fault" 6 "RHZCUeFs3DiagSts_6_ChipFault" 7 "RHZCUeFs3DiagSts_7_OpenCircuit" 8 "RHZCUeFs3DiagSts_8_ShortToGND" 9 "RHZCUeFs3DiagSts_9_ShortToBattery" 10 "RHZCUeFs3DiagSts_10_OtherFault" 11 "RHZCUeFs3DiagSts_11_Drive_Mismatch";
VAL_ 940 RHZCUeFs2Sts 0 "RHZCUeFs2Sts_0_Unknown" 1 "RHZCUeFs2Sts_1_Off" 2 "RHZCUeFs2Sts_2_On" 3 "RHZCUeFs2Sts_3_LatchOn" 4 "RHZCUeFs2Sts_4_FailureOff" 5 "RHZCUeFs2Sts_5_GoingDown";
VAL_ 940 RHZCUeFs2DiagSts 0 "RHZCUeFs2DiagSts_0_NoFault" 1 "RHZCUeFs2DiagSts_1_OCP" 2 "RHZCUeFs2DiagSts_2_OVP" 3 "RHZCUeFs2DiagSts_3_UVP" 4 "RHZCUeFs2DiagSts_4_OT" 5 "RHZCUeFs2DiagSts_5_SPI_Fault" 6 "RHZCUeFs2DiagSts_6_ChipFault" 7 "RHZCUeFs2DiagSts_7_OpenCircuit" 8 "RHZCUeFs2DiagSts_8_ShortToGND" 9 "RHZCUeFs2DiagSts_9_ShortToBattery" 10 "RHZCUeFs2DiagSts_10_OtherFault" 11 "RHZCUeFs2DiagSts_11_Drive_Mismatch";
VAL_ 940 RHZCUeFs1Sts 0 "RHZCUeFs1Sts_0_Unknown" 1 "RHZCUeFs1Sts_1_Off" 2 "RHZCUeFs1Sts_2_On" 3 "RHZCUeFs1Sts_3_LatchOn" 4 "RHZCUeFs1Sts_4_FailureOff" 5 "RHZCUeFs1Sts_5_GoingDown";
VAL_ 940 RHZCUeFs1DiagSts 0 "RHZCUeFs1DiagSts_0_NoFault" 1 "RHZCUeFs1DiagSts_1_OCP" 2 "RHZCUeFs1DiagSts_2_OVP" 3 "RHZCUeFs1DiagSts_3_UVP" 4 "RHZCUeFs1DiagSts_4_OT" 5 "RHZCUeFs1DiagSts_5_SPI_Fault" 6 "RHZCUeFs1DiagSts_6_ChipFault" 7 "RHZCUeFs1DiagSts_7_OpenCircuit" 8 "RHZCUeFs1DiagSts_8_ShortToGND" 9 "RHZCUeFs1DiagSts_9_ShortToBattery" 10 "RHZCUeFs1DiagSts_10_OtherFault" 11 "RHZCUeFs1DiagSts_11_Drive_Mismatch";
VAL_ 940 RHZCUeSw10Sts 0 "RHZCUeSw10Sts_0_Unknown" 1 "RHZCUeSw10Sts_1_Off" 2 "RHZCUeSw10Sts_2_On" 3 "RHZCUeSw10Sts_3_LatchOn" 4 "RHZCUeSw10Sts_4_FailureOff" 5 "RHZCUeSw10Sts_5_GoingDown";
VAL_ 940 RHZCUeSw10DiagSts 0 "RHZCUeSw10DiagSts_0_NoFault" 1 "RHZCUeSw10DiagSts_1_OCP" 2 "RHZCUeSw10DiagSts_2_OVP" 3 "RHZCUeSw10DiagSts_3_UVP" 4 "RHZCUeSw10DiagSts_4_OT" 5 "RHZCUeSw10DiagSts_5_SPI_Fault" 6 "RHZCUeSw10DiagSts_6_ChipFault" 7 "RHZCUeSw10DiagSts_7_OpenCircuit" 8 "RHZCUeSw10DiagSts_8_ShortToGND" 9 "RHZCUeSw10DiagSts_9_ShortToBattery" 10 "RHZCUeSw10DiagSts_10_OtherFault" 11 "RHZCUeSw10DiagSts_11_Drive_Mismatch";
VAL_ 940 RHZCUeSw34Sts 0 "RHZCUeSw34Sts_0_Unknown" 1 "RHZCUeSw34Sts_1_Off" 2 "RHZCUeSw34Sts_2_On" 3 "RHZCUeSw34Sts_3_LatchOn" 4 "RHZCUeSw34Sts_4_Failure" 5 "RHZCUeSw34Sts_5_GoingDown";
VAL_ 940 RHZCUeSw34DiagSts 0 "RHZCUeSw34DiagSts_0_NoFault" 1 "RHZCUeSw34DiagSts_1_OCP" 2 "RHZCUeSw34DiagSts_2_OVP" 3 "RHZCUeSw34DiagSts_3_UVP" 4 "RHZCUeSw34DiagSts_4_OT" 5 "RHZCUeSw34DiagSts_5_SPI_Fault" 6 "RHZCUeSw34DiagSts_6_ChipFault" 7 "RHZCUeSw34DiagSts_7_OpenCircuit" 8 "RHZCUeSw34DiagSts_8_ShortToGND" 9 "RHZCUeSw34DiagSts_9_ShortToBattery" 10 "RHZCUeSw34DiagSts_10_OtherFault" 11 "RHZCUeSw34DiagSts_11_Drive_Mismatch";
VAL_ 564 ChrgrFlapLtchCtrl 0 "ChrgrFlapLtchCtrl_0_NoRequest" 1 "ChrgrFlapLtchCtrl_1_ChrgrFlapLockRequest" 2 "ChrgrFlapLtchCtrl_2_ChrgrFlapUnlockRequest" 3 "ChrgrFlapLtchCtrl_3_Reserved";
VAL_ 564 RLDircnLghtSts 0 "RLDircnLghtSts_0_Off" 1 "RLDircnLghtSts_1_On";
VAL_ 564 RRDircnLghtSts 0 "RRDircnLghtSts_0_Off" 1 "RRDircnLghtSts_1_On";
VAL_ 564 RRDircnLghtFltsts 0 "RRDircnLghtFltsts_0_False" 1 "RRDircnLghtFltsts_1_True";
VAL_ 564 RLDircnLghtFltsts 0 "RLDircnLghtFltsts_0_False" 1 "RLDircnLghtFltsts_1_True";
VAL_ 564 RRDircnLghtFltsts_HW 0 "RRDircnLghtFltsts_HW_0_False" 1 "RRDircnLghtFltsts_HW_1_True";
VAL_ 564 RLDircnLghtFltsts_HW 0 "RLDircnLghtFltsts_HW_0_False" 1 "RLDircnLghtFltsts_HW_1_True";
VAL_ 564 RearFogLghtFltsts 0 "RearFogLghtFltsts_0_False" 1 "RearFogLghtFltsts_1_True";
VAL_ 564 RearFogLghtSts 0 "RearFogLghtSts_0_Off" 1 "RearFogLghtSts_1_On";
VAL_ 564 RevsLghtFltSts 0 "RevsLghtFltSts_0_False" 1 "RevsLghtFltSts_1_True";
VAL_ 564 BrkLghtFltSts_HW 0 "BrkLghtFltSts_HW_0_False" 1 "BrkLghtFltSts_HW_1_True";
VAL_ 564 PwrLftgtClsSwtActv 0 "PwrLftgtClsSwtActv_0_NoRequest" 1 "PwrLftgtClsSwtActv_1_CloseRequest" 2 "PwrLftgtClsSwtActv_2_OpenAngleSetRequest" 3 "PwrLftgtClsSwtActv_3_Reserved";
VAL_ 564 BrkLghtSts_HW 0 "BrkLghtSts_HW_0_Off" 1 "BrkLghtSts_HW_1_On";
VAL_ 564 RLDircnLghtSts_HW 0 "RLDircnLghtSts_HW_0_Off" 1 "RLDircnLghtSts_HW_1_On";
VAL_ 564 RRDircnLghtSts_HW 0 "RRDircnLghtSts_HW_0_Off" 1 "RRDircnLghtSts_HW_1_On";
VAL_ 564 LdspcOpenSts 0 "LdspcOpenSts_0_Closed" 1 "LdspcOpenSts_1_Open";
VAL_ 564 RevsLghtSts 0 "RevsLghtSts_0_off" 1 "RevsLghtSts_1_on";
VAL_ 564 LdspcOpenStsV 0 "LdspcOpenStsV_0_Valid" 1 "LdspcOpenStsV_1_Invalid";
VAL_ 1142 TPMSSnsrRdoFrqcCtrLoctn 0 "TPMSSnsrRdoFrqcCtrLoctn_0_FLSensor_Counter" 1 "TPMSSnsrRdoFrqcCtrLoctn_1_FRSensor_Counter" 2 "TPMSSnsrRdoFrqcCtrLoctn_2_RRSensor_Counter" 3 "TPMSSnsrRdoFrqcCtrLoctn_3_RLSensor_Counter";
VAL_ 1142 TPMSSnsrIDLoctn 0 "TPMSSnsrIDLoctn_0_FLSensor_ID" 1 "TPMSSnsrIDLoctn_1_FRSensor_ID" 2 "TPMSSnsrIDLoctn_2_RRSensor_ID" 3 "TPMSSnsrIDLoctn_3_RLSensor_ID";
VAL_ 210 En12VoltStrMotCmddOn 0 "En12VoltStrMotCmddOn_0_False" 1 "En12VoltStrMotCmddOn_1_True";
VAL_ 805 NOAQukChgSwReq 0 "NOAQukChgSwReq_0_False" 1 "NOAQukChgSwReq_1_True";
VAL_ 805 PDCPwrSts 0 "PDCPwrSts_0_OFF" 1 "PDCPwrSts_1_ON";
VAL_ 805 MMCUPwrSts 0 "MMCUPwrSts_0_OFF" 1 "MMCUPwrSts_1_ON";
VAL_ 805 FICMACRTemV 0 "FICMACRTemV_0_Valid" 1 "FICMACRTemV_1_Invalid";
VAL_ 805 AIParkngReq_ZXD 0 "AIParkngReq_ZXD_0_No_Request" 1 "AIParkngReq_ZXD_1_Start_Parking_in" 2 "AIParkngReq_ZXD_2_Start_Parking_out" 3 "AIParkngReq_ZXD_3_Pause" 4 "AIParkngReq_ZXD_4_Continue" 5 "AIParkngReq_ZXD_5_Cancel" 7 "AIParkngReq_ZXD_7_Left_Parking_out" 8 "AIParkngReq_ZXD_8_Right_Parking_out" 9 "AIParkngReq_ZXD_9_Fast_Parking" 10 "AIParkngReq_ZXD_10_Line_out_System_Start" 11 "AIParkngReq_ZXD_11_Line_back_System_Start" 12 "AIParkngReq_ZXD_12_Call_to_Position_X" 13 "AIParkngReq_ZXD_13_StartParkingScanningManualDriving" 14 "AIParkngReq_ZXD_14_Remote_turn_left" 15 "AIParkngReq_ZXD_15_Remote_turn_right" 16 "AIParkngReq_ZXD_16_RememberBuildMap" 17 "AIParkngReq_ZXD_17_Remember_Park_In" 18 "AIParkngReq_ZXD_18_Remember_Summon" 19 "AIParkngReq_ZXD_19_Start_Remember_Parking" 20 "AIParkngReq_ZXD_20_Keep_Going_Forword" 21 "AIParkngReq_ZXD_21_Keep_Going_Back" 22 "AIParkngReq_ZXD_22_Start_AVP_in" 23 "AIParkngReq_ZXD_23_Start_AVP_out" 24 "AIParkngReq_ZXD_24_Back_Left_Parking_out" 25 "AIParkngReq_ZXD_25_Back_Right_Parking_out" 26 "AIParkngReq_ZXD_26_Start_NRCD" 27 "AIParkngReq_ZXD_27_Front_Left_Cross_Park_Out" 28 "AIParkngReq_ZXD_28_Front_Left_Parallel_Park_Out" 29 "AIParkngReq_ZXD_29_Front_Out_Park_Out" 30 "AIParkngReq_ZXD_30_Front_Right_Cross_Park_Out" 31 "AIParkngReq_ZXD_31_Front_Right_Parallel_Park_Out" 32 "AIParkngReq_ZXD_32_Back_Out_Park_Out" 33 "AIParkngReq_ZXD_33_Back_Left_Cross_Park_Out" 34 "AIParkngReq_ZXD_34_Back_Right_Cross_Park_Out" 35 "AIParkngReq_ZXD_35_Start_Confirm" 36 "AIParkngReq_ZXD_36_Start_RPI" 37 "AIParkngReq_ZXD_37_Start_RPI_Super" 38 "AIParkngReq_ZXD_38_Confirm" 39 "AIParkngReq_ZXD_39_Quit" 40 "AIParkngReq_ZXD_40_Start_RADS" 41 "AIParkngReq_ZXD_41_Start_NPA" 48 "AIParkngReq_ZXD_48_Start_NCP";
VAL_ 805 FICMACRAirMdSwReq 0 "FICMACRAirMdSwReq_0_No_request" 1 "FICMACRAirMdSwReq_1_Short_press" 2 "FICMACRAirMdSwReq_2_Long_press";
VAL_ 805 FICMACLAirMdSwReq 0 "FICMACLAirMdSwReq_0_No_request" 1 "FICMACLAirMdSwReq_1_Short_press" 2 "FICMACLAirMdSwReq_2_Long_press";
VAL_ 805 FICMACIonizerReqSwReq 0 "FICMACIonizerReqSwReq_0_No_request" 1 "FICMACIonizerReqSwReq_1_Short_press" 2 "FICMACIonizerReqSwReq_2_Long_press";
VAL_ 805 FICMACFreshSwReq 0 "FICMACFreshSwReq_0_No_request" 1 "FICMACFreshSwReq_1_Short_press" 2 "FICMACFreshSwReq_2_Long_press";
VAL_ 805 FICMClmOnOffSwReq 0 "FICMClmOnOffSwReq_0_No_request" 1 "FICMClmOnOffSwReq_1_Short_press" 2 "FICMClmOnOffSwReq_2_Long_press" 3 "FICMClmOnOffSwReq_3_Reversed";
VAL_ 805 FICMACSyncSwReq 0 "FICMACSyncSwReq_0_No_request" 1 "FICMACSyncSwReq_1_Short_press" 2 "FICMACSyncSwReq_2_Long_press" 3 "FICMACSyncSwReq_3_Reserved";
VAL_ 805 FICMACRTemIncSwReq 0 "FICMACRTemIncSwReq_0_No_request" 1 "FICMACRTemIncSwReq_1_Short_press" 2 "FICMACRTemIncSwReq_2_Long_press";
VAL_ 805 FICMACRTemDecSwReq 0 "FICMACRTemDecSwReq_0_No_request" 1 "FICMACRTemDecSwReq_1_Short_press" 2 "FICMACRTemDecSwReq_2_Long_press";
VAL_ 805 FICMAirClnrBlwrLvlReq 0 "FICMAirClnrBlwrLvlReq_0_Blower_Off" 1 "FICMAirClnrBlwrLvlReq_1_level" 2 "FICMAirClnrBlwrLvlReq_2_level" 3 "FICMAirClnrBlwrLvlReq_3_level" 4 "FICMAirClnrBlwrLvlReq_4_level" 5 "FICMAirClnrBlwrLvlReq_5_level" 6 "FICMAirClnrBlwrLvlReq_6_level" 7 "FICMAirClnrBlwrLvlReq_7_level";
VAL_ 805 FICMACRTemReq 0 "FICMACRTemReq_0_Lo" 30 "FICMACRTemReq_30_High" 31 "FICMACRTemReq_31_Reserved";
VAL_ 805 AutoLaneChngVcCmd 0 "AutoLaneChngVcCmd_0_NoRequest" 1 "AutoLaneChngVcCmd_1_Right_Command_Auto_Lane_Change" 2 "AutoLaneChngVcCmd_2_Left_Command_Auto_Lane_Change" 3 "AutoLaneChngVcCmd_3_Cancel_Command_Auto_Lane_Change";
VAL_ 805 APAParkInOffsetTypeReq 0 "APAParkInOffsetTypeReq_0_INVALID" 1 "APAParkInOffsetTypeReq_1_LEFT" 2 "APAParkInOffsetTypeReq_2_MIDDLE" 3 "APAParkInOffsetTypeReq_3_RIGHT";
VAL_ 805 FICMIFPACOnOffSwReq 0 "FICMIFPACOnOffSwReq_0_No_request" 1 "FICMIFPACOnOffSwReq_1_Short_press" 2 "FICMIFPACOnOffSwReq_2_Long_press";
VAL_ 805 NOAReportSetSwReq 0 "NOAReportSetSwReq_0_no_request" 1 "NOAReportSetSwReq_1_detail" 2 "NOAReportSetSwReq_2_concision" 3 "NOAReportSetSwReq_3_minimal" 4 "NOAReportSetSwReq_4_Reserved";
VAL_ 805 NarRoVslAssSwReq 0 "NarRoVslAssSwReq_0_0_Norequest" 1 "NarRoVslAssSwReq_1_1_Off" 2 "NarRoVslAssSwReq_2_2_Near" 3 "NarRoVslAssSwReq_3_3_Middle" 4 "NarRoVslAssSwReq_4_4_Far";
VAL_ 805 ParkngSpdSwResp 0 "ParkngSpdSwResp_0_Default" 1 "ParkngSpdSwResp_1_LowSpeed" 2 "ParkngSpdSwResp_2_MiddleSpeed" 3 "ParkngSpdSwResp_3_HighSpeed";
VAL_ 805 NrwroadBwdAssSwReq 0 "NrwroadBwdAssSwReq_0_0_No_request" 1 "NrwroadBwdAssSwReq_1_1_RequestStart" 2 "NrwroadBwdAssSwReq_2_2_RequestActive" 3 "NrwroadBwdAssSwReq_3_3_Pause" 4 "NrwroadBwdAssSwReq_4_4_Continue" 5 "NrwroadBwdAssSwReq_5_5_Quit";
VAL_ 805 AutoLaneChngSwReq 0 "AutoLaneChngSwReq_0_AutoLaneChngSwReq_0_no_request" 1 "AutoLaneChngSwReq_1_AutoLaneChngSwReq_1_off" 2 "AutoLaneChngSwReq_2_AutoLaneChngSwReq_2_lane_change_suggestion" 3 "AutoLaneChngSwReq_3_AutoLaneChngSwReq_3_AlcWithDriver" 4 "AutoLaneChngSwReq_4_AutoLaneChngSwReq_4_AlcWithoutDriver_reserved" 5 "AutoLaneChngSwReq_5_AutoLaneChngSwReq_5_Reserved" 6 "AutoLaneChngSwReq_6_AutoLaneChngSwReq_6_Reserved" 7 "AutoLaneChngSwReq_7_AutoLaneChngSwReq_7_Reserved";
VAL_ 805 ESSAdoWrnngReq 0 "ESSAdoWrnngReq_0_no_request" 1 "ESSAdoWrnngReq_1_off" 2 "ESSAdoWrnngReq_2_on";
VAL_ 805 AutoLaneChngSetReq 0 "AutoLaneChngSetReq_0_NoRequest" 1 "AutoLaneChngSetReq_1_Level1" 2 "AutoLaneChngSetReq_2_Level2" 3 "AutoLaneChngSetReq_3_Level3";
VAL_ 805 APASWReq 0 "APASWReq_0_CLOSE" 1 "APASWReq_1_OPEN";
VAL_ 805 APAOneKeyParkSwReq 0 "APAOneKeyParkSwReq_0_no_request" 1 "APAOneKeyParkSwReq_1_Off" 2 "APAOneKeyParkSwReq_2_On";
VAL_ 805 NarRoVslAssQuit 0 "NarRoVslAssQuit_0_NoRequest" 1 "NarRoVslAssQuit_1_Quit";
VAL_ 805 LCRSwReq 0 "LCRSwReq_0_NoRequest" 1 "LCRSwReq_1_off" 2 "LCRSwReq_2_on" 3 "LCRSwReq_3_reserved";
VAL_ 805 FrtCarGoNotfrSwReq 0 "FrtCarGoNotfrSwReq_0_No_request" 1 "FrtCarGoNotfrSwReq_1_Off" 2 "FrtCarGoNotfrSwReq_2_On" 3 "FrtCarGoNotfrSwReq_3_Reserved";
VAL_ 805 ESSswReq 0 "ESSSwReq_0_NoRequest" 1 "ESSSwReq_1_off" 2 "ESSSwReq_2_on" 3 "AESSwDspCmd_3_On";
VAL_ 805 NOPSwReq 0 "NOPSwReq_0_NoRequest" 1 "NOPSwReq_1_off" 2 "NOPSwReq_2_on" 3 "NOPSwReq_3_reserved";
VAL_ 805 NOPCitySwReq 0 "NOPCitySwReq_0_NoRequest" 1 "NOPCitySwReq_1_Off" 2 "NOPCitySwReq_2_On" 3 "NOPCitySwReq_3_Reserved";
VAL_ 805 NOALaneSetSwReq 0 "NOALaneSetSwReq_0_No_request" 1 "NOALaneSetSwReq_1_Left1" 2 "NOALaneSetSwReq_2_Left2" 3 "NOALaneSetSwReq_3_Reserved";
VAL_ 805 NOAETCSetSwReq 0 "NOAETCSetSwReq_0_NoRequest" 1 "NOAETCSetSwReq_1_MTC" 2 "NOAETCSetSwReq_2_ETC" 3 "NOAETCSetSwReq_3_Reserved";
VAL_ 805 WlcmLghtReq 0 "WlcmLghtReq_0_false" 1 "WlcmLghtReq_1_true";
VAL_ 805 D2DSwReq 0 "D2DSwReq_0_no_request" 1 "D2DSwReq_1_off" 2 "D2DSwReq_2_on" 3 "D2DSwReq_3_reserved";
VAL_ 805 ParkngDirSw 0 "ParkngDirSw_0_NoRequest" 1 "ParkngDirSw_1_Frontparkingin" 2 "ParkngDirSw_2_backparkingin" 3 "ParkngDirSw_3_Reserved";
VAL_ 805 NrwroadBwdAssConfrmSwReq 0 "NrwroadBwdAssConfrmSwReq_0_0_No_request" 1 "NrwroadBwdAssConfrmSwReq_1_1_Activerequest" 2 "NrwroadBwdAssConfrmSwReq_2_2_quit_request";
VAL_ 805 FrwlLghtReq 0 "FrwlLghtReq_0_false" 1 "FrwlLghtReq_1_true";
VAL_ 805 FollowMeHomeReq 0 "FollowMeHomeReq_0_false" 1 "FollowMeHomeReq_1_true";
VAL_ 805 FICMChrgSttnMchngSta 0 "FICMChrgSttnMchngSta_0_None" 1 "FICMChrgSttnMchngSta_1_ChargeStationMatchingSuccess" 2 "FICMChrgSttnMchngSta_2_ChargeStationMatchingFailure" 3 "FICMChrgSttnMchngSta_3_Reserved";
VAL_ 805 FVCMPowerFailSwReq 0 "FVCMPowerFailSwReq_0_NoRequest" 1 "FVCMPowerFailSwReq_1_off" 2 "FVCMPowerFailSwReq_2_on" 3 "FVCMPowerFailSwReq_3_LowPwrMd";
VAL_ 805 D2DPriETClanSwReq 0 "D2DPriETClanSwReq_0_no_request" 1 "D2DPriETClanSwReq_1_off" 2 "D2DPriETClanSwReq_2_on" 3 "D2DPriETClanSwReq_3_reserved";
VAL_ 805 SLIFWrnngMdReq 0 "SLIFWrnngMdReq_0__NoRequest" 1 "SLIFWrnngMdReq_1__Off" 2 "SLIFWrnngMdReq_2__Visual" 3 "SLIFWrnngMdReq_3__Audible";
VAL_ 805 AIParkngEPAMdsw 0 "AIParkngEPAMdsw_0_Lockmode" 1 "AIParkngEPAMdsw_1_Simplemode";
VAL_ 805 PEBSwReq 0 "PEBSwReq_0_No_Request" 1 "PEBSwReq_1_Request";
VAL_ 711 SpedRegulaModSwReq 0 "SpedRegulaModSwReq_0_no_request" 1 "SpedRegulaModSwReq_1_ON_request" 2 "SpedRegulaModSwReq_2_OFF_request" 3 "SpedRegulaModSwReq_3_Reserved" 4 "SpedRegulaModSwReq_4_Reserved" 5 "SpedRegulaModSwReq_5_Reserved" 6 "SpedRegulaModSwReq_6_Reserved" 7 "SpedRegulaModSwReq_7_Reserved";
VAL_ 1216 ZXD_NM_BSMtoRMS_BKPCANFD 0 "ZXD_NM_BSMtoRMS_BKPCANFD_0_False" 1 "ZXD_NM_BSMtoRMS_BKPCANFD_1_True";
VAL_ 1216 ZXD_NM_PBSMtoRMS_BKPCANFD 0 "ZXD_NM_PBSMtoRMS_BKPCANFD_0_False" 1 "ZXD_NM_PBSMtoRMS_BKPCANFD_1_True";
VAL_ 1216 ZXD_NM_RMStoNOS_BKPCANFD 0 "ZXD_NM_RMStoNOS_BKPCANFD_0_False" 1 "ZXD_NM_RMStoNOS_BKPCANFD_1_True";
VAL_ 1216 ZXD_NM_RSStoNOS_BKPCANFD 0 "ZXD_NM_RSStoNOS_BKPCANFD_0_False" 1 "ZXD_NM_RSStoNOS_BKPCANFD_1_True";
VAL_ 1216 ZXD_NM_RSStoRMS_BKPCANFD 0 "ZXD_NM_RSStoRMS_BKPCANFD_0_False" 1 "ZXD_NM_RSStoRMS_BKPCANFD_1_True";
VAL_ 1216 ZXD_NM_NOStoRMS_BKPCANFD 0 "ZXD_NM_NOStoRMS_BKPCANFD_0_False" 1 "ZXD_NM_NOStoRMS_BKPCANFD_1_True";
VAL_ 1216 ZXD_NM_NOSSta_BKPCANFD 0 "ZXD_NM_NOSSta_BKPCANFD_0_False" 1 "ZXD_NM_NOSSta_BKPCANFD_1_True";
VAL_ 1216 ZXD_NM_RMSSta_BKPCANFD 0 "ZXD_NM_RMSSta_BKPCANFD_0_False" 1 "ZXD_NM_RMSSta_BKPCANFD_1_True";
VAL_ 1216 ZXD_NWI_BKPCANFD 0 "ZXD_NWI_BKPCANFD_0_NoWakeNetworkSource" 1 "ZXD_NWI_BKPCANFD_1_PowerModeIsNonOFF";
VAL_ 1216 ZXD_NOI_BKPCANFD 0 "ZXD_NOI_BKPCANFD_0_NoRequest" 65535 "ZXD_NOI_BKPCANFD_65535_AllNetworkOperationActive";
VAL_ 1216 ZXD_NKI_BKPCANFD 0 "ZXD_NKI_BKPCANFD_0_NoRequest" 1 "ZXD_NKI_BKPCANFD_1_PowerModeIsNonOFF";
SIG_GROUP_ 299 ILHZCU_20ms_Group03 1 : BrkLghtCtrl DippedBeamActStatus FLDircnLghtCtrl FRDircnLghtCtrl HzrdLghtSwReq LHZCU_20ms_Group03_CRC LHZCU_20ms_Group03_RC LHZCU_20ms_Group03_Reserved1 LHZCU_20ms_Group03_Reserved2 LHZCU_20ms_Group03_Reserved3 LHZCU_20ms_Group03_Reserved4 LHZCU_20ms_Group03_Reserved5 LHZCU_20ms_Group03_Reserved6 LMainBeamLghtCtrl PriySSBA PriySSBAV RLDircnLghtCtrl RMainBeamLghtCtrl RRDircnLghtCtrl RevsLghtCtrl SSBTrigd SecySSBA SecySSBAV;
SIG_GROUP_ 652 ILHZCU_50ms_Group06 1 : BntOpenSts DirnLghtSftyMonErr DrvrDetSts DrvrDoorOpenSts LHZCU_50ms_Group06_CRC LHZCU_50ms_Group06_RC LHZCU_50ms_Group06_Reserved1 LHZCU_50ms_Group06_Reserved2 LHZCU_50ms_Group06_Reserved3 LHZCU_50ms_Group06_Reserved4 LHZCU_50ms_Group06_Reserved5 LHZCU_50ms_Group06_Reserved6 LHZCU_50ms_Group06_Reserved7 LHZCU_50ms_Group06_Reserved8 RLDoorOpenSts RLSInitnFltPrst VehLckSts;
SIG_GROUP_ 484 IRFSDA_20ms_Group02 1 : AEBDclReqSts_ADAS AEBDclReqToqVal_ADAS AEBDclReqVal_ADAS RFSDA_20ms_Group02_CRC RFSDA_20ms_Group02_RC RFSDA_20ms_Group02_Reserved1 RFSDA_20ms_Group02_Reserved10 RFSDA_20ms_Group02_Reserved11 RFSDA_20ms_Group02_Reserved12 RFSDA_20ms_Group02_Reserved2 RFSDA_20ms_Group02_Reserved3 RFSDA_20ms_Group02_Reserved4 RFSDA_20ms_Group02_Reserved5 RFSDA_20ms_Group02_Reserved6 RFSDA_20ms_Group02_Reserved7 RFSDA_20ms_Group02_Reserved8 RFSDA_20ms_Group02_Reserved9;
SIG_GROUP_ 725 IRHRDA_50ms_Group04 1 : BSDSelSts DOWSelSts LBSDAndLCAWrnng LCASelSts LDOWWrnng LRCTAWrnng RBSDAndLCAWrnng RCTSysSelSts RDASwSts RDASysSta RDOWWrnng RHRDA_50ms_Group04_CRC RHRDA_50ms_Group04_RC RHRDA_50ms_Group04_Reserved1 RHRDA_50ms_Group04_Reserved2 RHRDA_50ms_Group04_Reserved3 RHRDA_50ms_Group04_Reserved4 RLRdrEmgcLineChngWrnng RRCTAWrnng RRRdrEmgcLineChngWrnng RrCrnRdrCalSts;
SIG_GROUP_ 544 IRHZCU_50ms_Group27 1 : RHZCU_50ms_Group27_CRC RHZCU_50ms_Group27_RC RHZCU_50ms_Group27_Reserved1 RHZCU_50ms_Group27_Reserved2 RHZCU_50ms_Group27_Reserved3 RHZCU_50ms_Group27_Reserved4 RHZCU_50ms_Group27_Reserved5 RHZCU_50ms_Group27_Reserved6 RHZCU_50ms_Group27_Reserved7 RHZCUeSw33DiagSts RHZCUeSw33Sts RHZCUeSw37DiagSts RHZCUeSw37Sts RHZCUeSw3DiagSts RHZCUeSw3Sts RHZCUeSw42DiagSts RHZCUeSw42Sts RHZCUeSw43DiagSts RHZCUeSw43Sts RHZCUeSw9DiagSts RHZCUeSw9Sts;
SIG_GROUP_ 829 IRHZCU_100ms_Group10 1 : ACAmbtTem ACAmbtTemMsk ACAmbtTemV ACComprActuPwr FRSeatHorzPos FRSeatVertPos RHZCU_100ms_Group10_CRC RHZCU_100ms_Group10_RC RHZCU_100ms_Group10_Reserved1 RHZCU_100ms_Group10_Reserved2 RHZCU_100ms_Group10_Reserved3 RHZCU_100ms_Group10_Reserved4;
SIG_GROUP_ 649 IRHZCU_50ms_Group01 1 : RHZCU_50ms_Group01_CRC RHZCU_50ms_Group01_RC RHZCU_50ms_Group01_Reserved1 RHZCU_50ms_Group01_Reserved2 RHZCU_50ms_Group01_Reserved3 RHZCU_50ms_Group01_Reserved4 RHZCU_50ms_Group01_Reserved5 RHZCU_50ms_Group01_Reserved6 RHZCU_50ms_Group01_Reserved7 RHZCUeSw41DiagSts RHZCUeSw41Sts RRDoorOpenSts;
SIG_GROUP_ 564 IRZCU_50ms_Group37 1 : BrkLghtFltSts_HW BrkLghtSts_HW ChrgrFlapLtchCtrl LdspcOpenSts LdspcOpenStsV PwrLftgtClsSwtActv RLDircnLghtFltsts RLDircnLghtFltsts_HW RLDircnLghtSts RLDircnLghtSts_HW RRDircnLghtFltsts RRDircnLghtFltsts_HW RRDircnLghtSts RRDircnLghtSts_HW RZCU_50ms_Group37_CRC RZCU_50ms_Group37_RC RZCU_50ms_Group37_Reserved15 RZCU_50ms_Group37_Reserved23 RZCU_50ms_Group37_Reserved31 RZCU_50ms_Group37_Reserved34 RZCU_50ms_Group37_Reserved36 RZCU_50ms_Group37_Reserved38 RZCU_50ms_Group37_Reserved63 RearFogLghtFltsts RearFogLghtSts RevsLghtFltSts RevsLghtSts;
